VERSION ""

NS_ :

BS_:

BU_: Device Host
VAL_TABLE_ vtBridgeOperation 0 "Freewheeling" 1 "Forward" 2 "Reverse" 3 "Brake" 6 "Error" 7 "Not Available" ;
VAL_TABLE_ vtBridgeStatus 0 "OK" 1 "Shutdown" 2 "Unconfigured" 3 "Not Available" ;
VAL_TABLE_ vtDigitalInput 0 "InputLow" 1 "InputHigh" 2 "Error" 3 "Not Available" ;
VAL_TABLE_ vtOnOff 0 "Off" 1 "On" 2 "Error" 3 "Not Available" ;
VAL_TABLE_ vtPinMode 0 "Disabled" 1 "VREF" 2 "HighSide" 3 "LowSide" 4 "InputOnly" 5 "Bridge" 14 "Error" 15 "Not Available" ;
VAL_TABLE_ vtPinPullMode 0 "None" 1 "PullDown" 2 "PullUp" 3 "Not Available" ;
VAL_TABLE_ vtPwmFreq 0 "1 Hz" 1 "2 Hz" 2 "5 Hz" 3 "10 Hz" 4 "20 Hz" 5 "50 Hz" 6 "100 Hz" 7 "200 Hz" 8 "500 Hz" 9 "1 KHz" 10 "2 KHz" 11 "5 KHz" 14 "Error" 15 "Not Available" ;
VAL_TABLE_ vtQEncoderDirection 0 "Stopped" 1 "Forward" 2 "Reverse" 3 "NotAvailable" ;

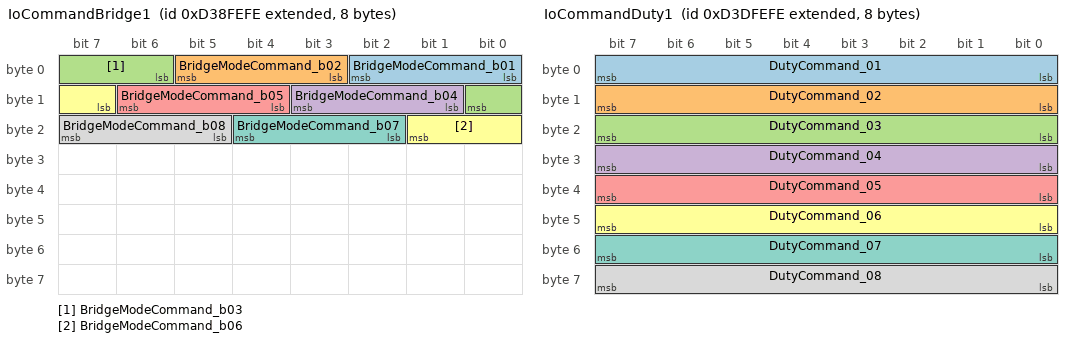
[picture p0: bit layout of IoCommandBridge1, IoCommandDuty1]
BO_ 2369322750 IoCommandBridge1: 8 Host
 SG_ BridgeModeCommand_b01 : 0|3@1+ (1,0) [0|7] ""  Device
 SG_ BridgeModeCommand_b02 : 3|3@1+ (1,0) [0|7] ""  Device
 SG_ BridgeModeCommand_b03 : 6|3@1+ (1,0) [0|7] ""  Device
 SG_ BridgeModeCommand_b04 : 9|3@1+ (1,0) [0|7] ""  Device
 SG_ BridgeModeCommand_b05 : 12|3@1+ (1,0) [0|7] ""  Device
 SG_ BridgeModeCommand_b06 : 15|3@1+ (1,0) [0|7] ""  Device
 SG_ BridgeModeCommand_b07 : 18|3@1+ (1,0) [0|7] ""  Device
 SG_ BridgeModeCommand_b08 : 21|3@1+ (1,0) [0|7] ""  Device

BO_ 2369650430 IoCommandDuty1: 8 Host
 SG_ DutyCommand_01 : 0|8@1+ (0.5,0) [0|100] "%"  Device
 SG_ DutyCommand_02 : 8|8@1+ (0.5,0) [0|100] "%"  Device
 SG_ DutyCommand_03 : 16|8@1+ (0.5,0) [0|100] "%"  Device
 SG_ DutyCommand_04 : 24|8@1+ (0.5,0) [0|100] "%"  Device
 SG_ DutyCommand_05 : 32|8@1+ (0.5,0) [0|100] "%"  Device
 SG_ DutyCommand_06 : 40|8@1+ (0.5,0) [0|100] "%"  Device
 SG_ DutyCommand_07 : 48|8@1+ (0.5,0) [0|100] "%"  Device
 SG_ DutyCommand_08 : 56|8@1+ (0.5,0) [0|100] "%"  Device

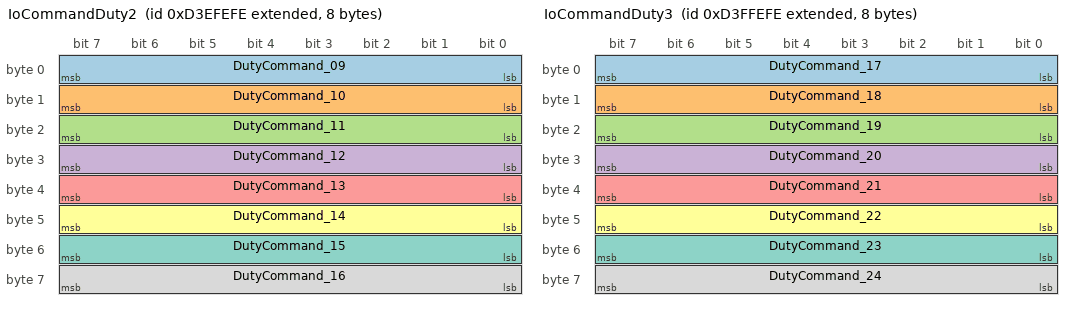
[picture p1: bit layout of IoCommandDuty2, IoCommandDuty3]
BO_ 2369715966 IoCommandDuty2: 8 Host
 SG_ DutyCommand_09 : 0|8@1+ (0.5,0) [0|100] "%"  Device
 SG_ DutyCommand_10 : 8|8@1+ (0.5,0) [0|100] "%"  Device
 SG_ DutyCommand_11 : 16|8@1+ (0.5,0) [0|100] "%"  Device
 SG_ DutyCommand_12 : 24|8@1+ (0.5,0) [0|100] "%"  Device
 SG_ DutyCommand_13 : 32|8@1+ (0.5,0) [0|100] "%"  Device
 SG_ DutyCommand_14 : 40|8@1+ (0.5,0) [0|100] "%"  Device
 SG_ DutyCommand_15 : 48|8@1+ (0.5,0) [0|100] "%"  Device
 SG_ DutyCommand_16 : 56|8@1+ (0.5,0) [0|100] "%"  Device

BO_ 2369781502 IoCommandDuty3: 8 Host
 SG_ DutyCommand_17 : 0|8@1+ (0.5,0) [0|100] "%"  Device
 SG_ DutyCommand_18 : 8|8@1+ (0.5,0) [0|100] "%"  Device
 SG_ DutyCommand_19 : 16|8@1+ (0.5,0) [0|100] "%"  Device
 SG_ DutyCommand_20 : 24|8@1+ (0.5,0) [0|100] "%"  Device
 SG_ DutyCommand_21 : 32|8@1+ (0.5,0) [0|100] "%"  Device
 SG_ DutyCommand_22 : 40|8@1+ (0.5,0) [0|100] "%"  Device
 SG_ DutyCommand_23 : 48|8@1+ (0.5,0) [0|100] "%"  Device
 SG_ DutyCommand_24 : 56|8@1+ (0.5,0) [0|100] "%"  Device

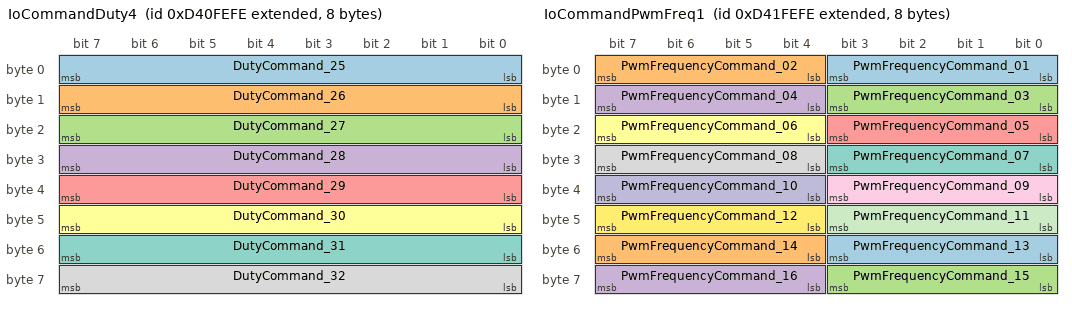
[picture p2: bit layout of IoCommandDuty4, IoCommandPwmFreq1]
BO_ 2369847038 IoCommandDuty4: 8 Host
 SG_ DutyCommand_25 : 0|8@1+ (0.5,0) [0|100] "%"  Device
 SG_ DutyCommand_26 : 8|8@1+ (0.5,0) [0|100] "%"  Device
 SG_ DutyCommand_27 : 16|8@1+ (0.5,0) [0|100] "%"  Device
 SG_ DutyCommand_28 : 24|8@1+ (0.5,0) [0|100] "%"  Device
 SG_ DutyCommand_29 : 32|8@1+ (0.5,0) [0|100] "%"  Device
 SG_ DutyCommand_30 : 40|8@1+ (0.5,0) [0|100] "%"  Device
 SG_ DutyCommand_31 : 48|8@1+ (0.5,0) [0|100] "%"  Device
 SG_ DutyCommand_32 : 56|8@1+ (0.5,0) [0|100] "%"  Device

BO_ 2370043646 IoCommandDutyFD: 32 Host
 SG_ DutyCommand_01 : 0|8@1+ (0.5,0) [0|100] "%"  Device
 SG_ DutyCommand_02 : 8|8@1+ (0.5,0) [0|100] "%"  Device
 SG_ DutyCommand_03 : 16|8@1+ (0.5,0) [0|100] "%"  Device
 SG_ DutyCommand_04 : 24|8@1+ (0.5,0) [0|100] "%"  Device
 SG_ DutyCommand_05 : 32|8@1+ (0.5,0) [0|100] "%"  Device
 SG_ DutyCommand_06 : 40|8@1+ (0.5,0) [0|100] "%"  Device
 SG_ DutyCommand_07 : 48|8@1+ (0.5,0) [0|100] "%"  Device
 SG_ DutyCommand_08 : 56|8@1+ (0.5,0) [0|100] "%"  Device
 SG_ DutyCommand_09 : 64|8@1+ (0.5,0) [0|100] "%"  Device
 SG_ DutyCommand_10 : 72|8@1+ (0.5,0) [0|100] "%"  Device
 SG_ DutyCommand_11 : 80|8@1+ (0.5,0) [0|100] "%"  Device
 SG_ DutyCommand_12 : 88|8@1+ (0.5,0) [0|100] "%"  Device
 SG_ DutyCommand_13 : 96|8@1+ (0.5,0) [0|100] "%"  Device
 SG_ DutyCommand_14 : 104|8@1+ (0.5,0) [0|100] "%"  Device
 SG_ DutyCommand_15 : 112|8@1+ (0.5,0) [0|100] "%"  Device
 SG_ DutyCommand_16 : 120|8@1+ (0.5,0) [0|100] "%"  Device
 SG_ DutyCommand_17 : 128|8@1+ (0.5,0) [0|100] "%"  Device
 SG_ DutyCommand_18 : 136|8@1+ (0.5,0) [0|100] "%"  Device
 SG_ DutyCommand_19 : 144|8@1+ (0.5,0) [0|100] "%"  Device
 SG_ DutyCommand_20 : 152|8@1+ (0.5,0) [0|100] "%"  Device
 SG_ DutyCommand_21 : 160|8@1+ (0.5,0) [0|100] "%"  Device
 SG_ DutyCommand_22 : 168|8@1+ (0.5,0) [0|100] "%"  Device
 SG_ DutyCommand_23 : 176|8@1+ (0.5,0) [0|100] "%"  Device
 SG_ DutyCommand_24 : 184|8@1+ (0.5,0) [0|100] "%"  Device
 SG_ DutyCommand_25 : 192|8@1+ (0.5,0) [0|100] "%"  Device
 SG_ DutyCommand_26 : 200|8@1+ (0.5,0) [0|100] "%"  Device
 SG_ DutyCommand_27 : 208|8@1+ (0.5,0) [0|100] "%"  Device
 SG_ DutyCommand_28 : 216|8@1+ (0.5,0) [0|100] "%"  Device
 SG_ DutyCommand_29 : 224|8@1+ (0.5,0) [0|100] "%"  Device
 SG_ DutyCommand_30 : 232|8@1+ (0.5,0) [0|100] "%"  Device
 SG_ DutyCommand_31 : 240|8@1+ (0.5,0) [0|100] "%"  Device
 SG_ DutyCommand_32 : 248|8@1+ (0.5,0) [0|100] "%"  Device

BO_ 2369388286 IoCommandPinMode1: 8 Host
 SG_ PinModeCommand_01 : 0|4@1+ (1,0) [0|0] ""  Device
 SG_ PinPullModeCommand_01 : 4|2@1+ (1,0) [0|0] ""  Device
 SG_ LoadDetectionCommand_01 : 6|2@1+ (1,0) [0|0] ""  Device
 SG_ PinModeCommand_02 : 8|4@1+ (1,0) [0|0] ""  Device
 SG_ PinPullModeCommand_02 : 12|2@1+ (1,0) [0|0] ""  Device
 SG_ LoadDetectionCommand_02 : 14|2@1+ (1,0) [0|0] ""  Device
 SG_ PinModeCommand_03 : 16|4@1+ (1,0) [0|0] ""  Device
 SG_ PinPullModeCommand_03 : 20|2@1+ (1,0) [0|0] ""  Device
 SG_ LoadDetectionCommand_03 : 22|2@1+ (1,0) [0|0] ""  Device
 SG_ PinModeCommand_04 : 24|4@1+ (1,0) [0|0] ""  Device
 SG_ PinPullModeCommand_04 : 28|2@1+ (1,0) [0|0] ""  Device
 SG_ LoadDetectionCommand_04 : 30|2@1+ (1,0) [0|0] ""  Device
 SG_ PinModeCommand_05 : 32|4@1+ (1,0) [0|0] ""  Device
 SG_ PinPullModeCommand_05 : 36|2@1+ (1,0) [0|0] ""  Device
 SG_ LoadDetectionCommand_05 : 38|2@1+ (1,0) [0|0] ""  Device
 SG_ PinModeCommand_06 : 40|4@1+ (1,0) [0|0] ""  Device
 SG_ PinPullModeCommand_06 : 44|2@1+ (1,0) [0|0] ""  Device
 SG_ LoadDetectionCommand_06 : 46|2@1+ (1,0) [0|0] ""  Device
 SG_ PinModeCommand_07 : 48|4@1+ (1,0) [0|0] ""  Device
 SG_ PinPullModeCommand_07 : 52|2@1+ (1,0) [0|0] ""  Device
 SG_ LoadDetectionCommand_07 : 54|2@1+ (1,0) [0|0] ""  Device
 SG_ PinModeCommand_08 : 56|4@1+ (1,0) [0|0] ""  Device
 SG_ PinPullModeCommand_08 : 60|2@1+ (1,0) [0|0] ""  Device
 SG_ LoadDetectionCommand_08 : 62|2@1+ (1,0) [0|0] ""  Device

BO_ 2369453822 IoCommandPinMode2: 8 Host
 SG_ PinModeCommand_09 : 0|4@1+ (1,0) [0|0] ""  Device
 SG_ PinPullModeCommand_09 : 4|2@1+ (1,0) [0|0] ""  Device
 SG_ LoadDetectionCommand_09 : 6|2@1+ (1,0) [0|0] ""  Device
 SG_ PinModeCommand_10 : 8|4@1+ (1,0) [0|0] ""  Device
 SG_ PinPullModeCommand_10 : 12|2@1+ (1,0) [0|0] ""  Device
 SG_ LoadDetectionCommand_10 : 14|2@1+ (1,0) [0|0] ""  Device
 SG_ PinModeCommand_11 : 16|4@1+ (1,0) [0|0] ""  Device
 SG_ PinPullModeCommand_11 : 20|2@1+ (1,0) [0|0] ""  Device
 SG_ LoadDetectionCommand_11 : 22|2@1+ (1,0) [0|0] ""  Device
 SG_ PinModeCommand_12 : 24|4@1+ (1,0) [0|0] ""  Device
 SG_ PinPullModeCommand_12 : 28|2@1+ (1,0) [0|0] ""  Device
 SG_ LoadDetectionCommand_12 : 30|2@1+ (1,0) [0|0] ""  Device
 SG_ PinModeCommand_13 : 32|4@1+ (1,0) [0|0] ""  Device
 SG_ PinPullModeCommand_13 : 36|2@1+ (1,0) [0|0] ""  Device
 SG_ LoadDetectionCommand_13 : 38|2@1+ (1,0) [0|0] ""  Device
 SG_ PinModeCommand_14 : 40|4@1+ (1,0) [0|0] ""  Device
 SG_ PinPullModeCommand_14 : 44|2@1+ (1,0) [0|0] ""  Device
 SG_ LoadDetectionCommand_14 : 46|2@1+ (1,0) [0|0] ""  Device
 SG_ PinModeCommand_15 : 48|4@1+ (1,0) [0|0] ""  Device
 SG_ PinPullModeCommand_15 : 52|2@1+ (1,0) [0|0] ""  Device
 SG_ LoadDetectionCommand_15 : 54|2@1+ (1,0) [0|0] ""  Device
 SG_ PinModeCommand_16 : 56|4@1+ (1,0) [0|0] ""  Device
 SG_ PinPullModeCommand_16 : 60|2@1+ (1,0) [0|0] ""  Device
 SG_ LoadDetectionCommand_16 : 62|2@1+ (1,0) [0|0] ""  Device

BO_ 2369519358 IoCommandPinMode3: 8 Host
 SG_ PinModeCommand_17 : 0|4@1+ (1,0) [0|0] ""  Device
 SG_ PinPullModeCommand_17 : 4|2@1+ (1,0) [0|0] ""  Device
 SG_ LoadDetectionCommand_17 : 6|2@1+ (1,0) [0|0] ""  Device
 SG_ PinModeCommand_18 : 8|4@1+ (1,0) [0|0] ""  Device
 SG_ PinPullModeCommand_18 : 12|2@1+ (1,0) [0|0] ""  Device
 SG_ LoadDetectionCommand_18 : 14|2@1+ (1,0) [0|0] ""  Device
 SG_ PinModeCommand_19 : 16|4@1+ (1,0) [0|0] ""  Device
 SG_ PinPullModeCommand_19 : 20|2@1+ (1,0) [0|0] ""  Device
 SG_ LoadDetectionCommand_19 : 22|2@1+ (1,0) [0|0] ""  Device
 SG_ PinModeCommand_20 : 24|4@1+ (1,0) [0|0] ""  Device
 SG_ PinPullModeCommand_20 : 28|2@1+ (1,0) [0|0] ""  Device
 SG_ LoadDetectionCommand_20 : 30|2@1+ (1,0) [0|0] ""  Device
 SG_ PinModeCommand_21 : 32|4@1+ (1,0) [0|0] ""  Device
 SG_ PinPullModeCommand_21 : 36|2@1+ (1,0) [0|0] ""  Device
 SG_ LoadDetectionCommand_21 : 38|2@1+ (1,0) [0|0] ""  Device
 SG_ PinModeCommand_22 : 40|4@1+ (1,0) [0|0] ""  Device
 SG_ PinPullModeCommand_22 : 44|2@1+ (1,0) [0|0] ""  Device
 SG_ LoadDetectionCommand_22 : 46|2@1+ (1,0) [0|0] ""  Device
 SG_ PinModeCommand_23 : 48|4@1+ (1,0) [0|0] ""  Device
 SG_ PinPullModeCommand_23 : 52|2@1+ (1,0) [0|0] ""  Device
 SG_ LoadDetectionCommand_23 : 54|2@1+ (1,0) [0|0] ""  Device
 SG_ PinModeCommand_24 : 56|4@1+ (1,0) [0|0] ""  Device
 SG_ PinPullModeCommand_24 : 60|2@1+ (1,0) [0|0] ""  Device
 SG_ LoadDetectionCommand_24 : 62|2@1+ (1,0) [0|0] ""  Device

BO_ 2369584894 IoCommandPinMode4: 8 Host
 SG_ PinModeCommand_25 : 0|4@1+ (1,0) [0|0] ""  Device
 SG_ PinPullModeCommand_25 : 4|2@1+ (1,0) [0|0] ""  Device
 SG_ LoadDetectionCommand_25 : 6|2@1+ (1,0) [0|0] ""  Device
 SG_ PinModeCommand_26 : 8|4@1+ (1,0) [0|0] ""  Device
 SG_ PinPullModeCommand_26 : 12|2@1+ (1,0) [0|0] ""  Device
 SG_ LoadDetectionCommand_26 : 14|2@1+ (1,0) [0|0] ""  Device
 SG_ PinModeCommand_27 : 16|4@1+ (1,0) [0|0] ""  Device
 SG_ PinPullModeCommand_27 : 20|2@1+ (1,0) [0|0] ""  Device
 SG_ LoadDetectionCommand_27 : 22|2@1+ (1,0) [0|0] ""  Device
 SG_ PinModeCommand_28 : 24|4@1+ (1,0) [0|0] ""  Device
 SG_ PinPullModeCommand_28 : 28|2@1+ (1,0) [0|0] ""  Device
 SG_ LoadDetectionCommand_28 : 30|2@1+ (1,0) [0|0] ""  Device
 SG_ PinModeCommand_29 : 32|4@1+ (1,0) [0|0] ""  Device
 SG_ PinPullModeCommand_29 : 36|2@1+ (1,0) [0|0] ""  Device
 SG_ LoadDetectionCommand_29 : 38|2@1+ (1,0) [0|0] ""  Device
 SG_ PinModeCommand_30 : 40|4@1+ (1,0) [0|0] ""  Device
 SG_ PinPullModeCommand_30 : 44|2@1+ (1,0) [0|0] ""  Device
 SG_ LoadDetectionCommand_30 : 46|2@1+ (1,0) [0|0] ""  Device
 SG_ PinModeCommand_31 : 48|4@1+ (1,0) [0|0] ""  Device
 SG_ PinPullModeCommand_31 : 52|2@1+ (1,0) [0|0] ""  Device
 SG_ LoadDetectionCommand_31 : 54|2@1+ (1,0) [0|0] ""  Device
 SG_ PinModeCommand_32 : 56|4@1+ (1,0) [0|0] ""  Device
 SG_ PinPullModeCommand_32 : 60|2@1+ (1,0) [0|0] ""  Device
 SG_ LoadDetectionCommand_32 : 62|2@1+ (1,0) [0|0] ""  Device

BO_ 2369912574 IoCommandPwmFreq1: 8 Host
 SG_ PwmFrequencyCommand_01 : 0|4@1+ (1,0) [0|15] ""  Device
 SG_ PwmFrequencyCommand_02 : 4|4@1+ (1,0) [0|15] ""  Device
 SG_ PwmFrequencyCommand_03 : 8|4@1+ (1,0) [0|15] ""  Device
 SG_ PwmFrequencyCommand_04 : 12|4@1+ (1,0) [0|15] ""  Device
 SG_ PwmFrequencyCommand_05 : 16|4@1+ (1,0) [0|15] ""  Device
 SG_ PwmFrequencyCommand_06 : 20|4@1+ (1,0) [0|15] ""  Device
 SG_ PwmFrequencyCommand_07 : 24|4@1+ (1,0) [0|15] ""  Device
 SG_ PwmFrequencyCommand_08 : 28|4@1+ (1,0) [0|15] ""  Device
 SG_ PwmFrequencyCommand_09 : 32|4@1+ (1,0) [0|15] ""  Device
 SG_ PwmFrequencyCommand_10 : 36|4@1+ (1,0) [0|15] ""  Device
 SG_ PwmFrequencyCommand_11 : 40|4@1+ (1,0) [0|15] ""  Device
 SG_ PwmFrequencyCommand_12 : 44|4@1+ (1,0) [0|15] ""  Device
 SG_ PwmFrequencyCommand_13 : 48|4@1+ (1,0) [0|15] ""  Device
 SG_ PwmFrequencyCommand_14 : 52|4@1+ (1,0) [0|15] ""  Device
 SG_ PwmFrequencyCommand_15 : 56|4@1+ (1,0) [0|15] ""  Device
 SG_ PwmFrequencyCommand_16 : 60|4@1+ (1,0) [0|15] ""  Device

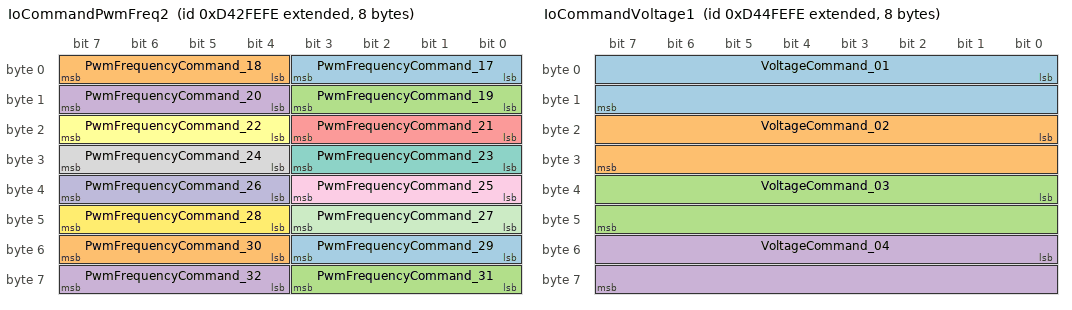
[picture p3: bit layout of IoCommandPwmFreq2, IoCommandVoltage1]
BO_ 2369978110 IoCommandPwmFreq2: 8 Host
 SG_ PwmFrequencyCommand_17 : 0|4@1+ (1,0) [0|15] ""  Device
 SG_ PwmFrequencyCommand_18 : 4|4@1+ (1,0) [0|15] ""  Device
 SG_ PwmFrequencyCommand_19 : 8|4@1+ (1,0) [0|15] ""  Device
 SG_ PwmFrequencyCommand_20 : 12|4@1+ (1,0) [0|15] ""  Device
 SG_ PwmFrequencyCommand_21 : 16|4@1+ (1,0) [0|15] ""  Device
 SG_ PwmFrequencyCommand_22 : 20|4@1+ (1,0) [0|15] ""  Device
 SG_ PwmFrequencyCommand_23 : 24|4@1+ (1,0) [0|15] ""  Device
 SG_ PwmFrequencyCommand_24 : 28|4@1+ (1,0) [0|15] ""  Device
 SG_ PwmFrequencyCommand_25 : 32|4@1+ (1,0) [0|15] ""  Device
 SG_ PwmFrequencyCommand_26 : 36|4@1+ (1,0) [0|15] ""  Device
 SG_ PwmFrequencyCommand_27 : 40|4@1+ (1,0) [0|15] ""  Device
 SG_ PwmFrequencyCommand_28 : 44|4@1+ (1,0) [0|15] ""  Device
 SG_ PwmFrequencyCommand_29 : 48|4@1+ (1,0) [0|15] ""  Device
 SG_ PwmFrequencyCommand_30 : 52|4@1+ (1,0) [0|15] ""  Device
 SG_ PwmFrequencyCommand_31 : 56|4@1+ (1,0) [0|15] ""  Device
 SG_ PwmFrequencyCommand_32 : 60|4@1+ (1,0) [0|15] ""  Device

BO_ 2370109182 IoCommandVoltage1: 8 Host
 SG_ VoltageCommand_01 : 0|16@1+ (0.001,0) [0|64.255] "V"  Device
 SG_ VoltageCommand_02 : 16|16@1+ (0.001,0) [0|64.255] "V"  Device
 SG_ VoltageCommand_03 : 32|16@1+ (0.001,0) [0|64.255] "V"  Device
 SG_ VoltageCommand_04 : 48|16@1+ (0.001,0) [0|64.255] "V"  Device

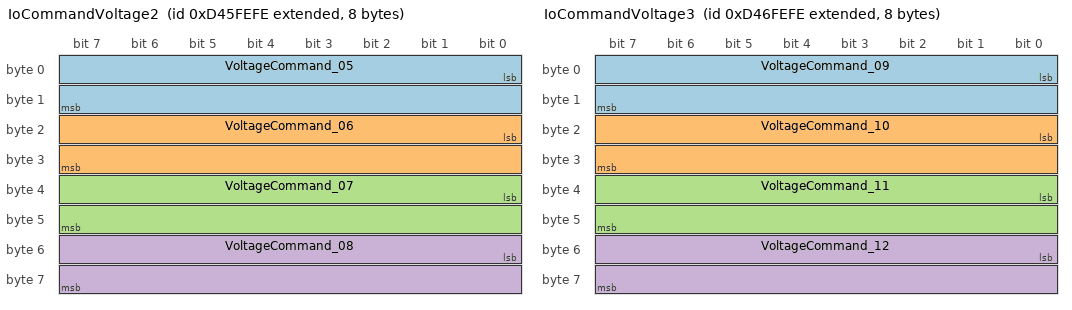
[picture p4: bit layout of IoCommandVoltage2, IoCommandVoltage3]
BO_ 2370174718 IoCommandVoltage2: 8 Host
 SG_ VoltageCommand_05 : 0|16@1+ (0.001,0) [0|64.255] "V"  Device
 SG_ VoltageCommand_06 : 16|16@1+ (0.001,0) [0|64.255] "V"  Device
 SG_ VoltageCommand_07 : 32|16@1+ (0.001,0) [0|64.255] "V"  Device
 SG_ VoltageCommand_08 : 48|16@1+ (0.001,0) [0|64.255] "V"  Device

BO_ 2370240254 IoCommandVoltage3: 8 Host
 SG_ VoltageCommand_09 : 0|16@1+ (0.001,0) [0|64.255] "V"  Device
 SG_ VoltageCommand_10 : 16|16@1+ (0.001,0) [0|64.255] "V"  Device
 SG_ VoltageCommand_11 : 32|16@1+ (0.001,0) [0|64.255] "V"  Device
 SG_ VoltageCommand_12 : 48|16@1+ (0.001,0) [0|64.255] "V"  Device

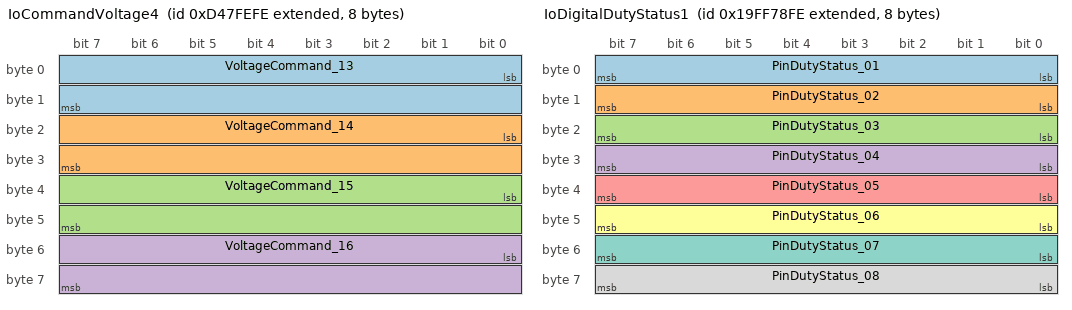
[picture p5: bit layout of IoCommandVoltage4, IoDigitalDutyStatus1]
BO_ 2370305790 IoCommandVoltage4: 8 Host
 SG_ VoltageCommand_13 : 0|16@1+ (0.001,0) [0|64.255] "V"  Device
 SG_ VoltageCommand_14 : 16|16@1+ (0.001,0) [0|64.255] "V"  Device
 SG_ VoltageCommand_15 : 32|16@1+ (0.001,0) [0|64.255] "V"  Device
 SG_ VoltageCommand_16 : 48|16@1+ (0.001,0) [0|64.255] "V"  Device

BO_ 2583656702 IoDigitalDutyStatus1: 8 Device
 SG_ PinDutyStatus_01 : 0|8@1+ (0.5,0) [0|100] "%"  Host
 SG_ PinDutyStatus_02 : 8|8@1+ (0.5,0) [0|100] "%"  Host
 SG_ PinDutyStatus_03 : 16|8@1+ (0.5,0) [0|100] "%"  Host
 SG_ PinDutyStatus_04 : 24|8@1+ (0.5,0) [0|100] "%"  Host
 SG_ PinDutyStatus_05 : 32|8@1+ (0.5,0) [0|100] "%"  Host
 SG_ PinDutyStatus_06 : 40|8@1+ (0.5,0) [0|100] "%"  Host
 SG_ PinDutyStatus_07 : 48|8@1+ (0.5,0) [0|100] "%"  Host
 SG_ PinDutyStatus_08 : 56|8@1+ (0.5,0) [0|100] "%"  Host

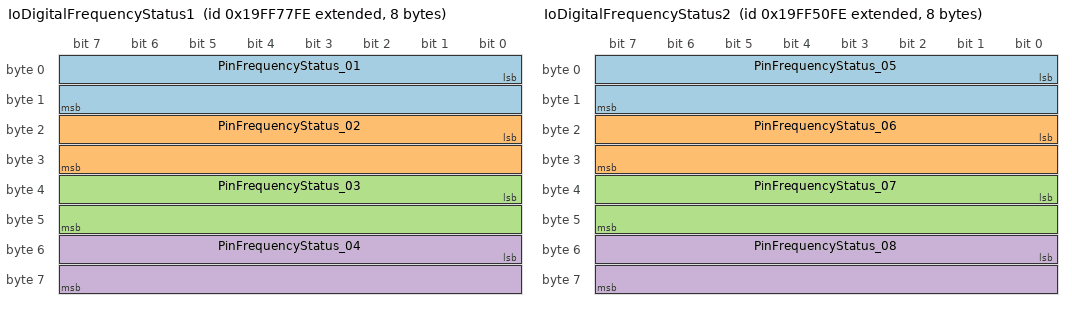
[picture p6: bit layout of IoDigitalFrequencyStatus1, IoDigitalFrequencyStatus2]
BO_ 2583656446 IoDigitalFrequencyStatus1: 8 Device
 SG_ PinFrequencyStatus_01 : 0|16@1+ (0.1,0) [0|6425.5] "Hz"  Host
 SG_ PinFrequencyStatus_02 : 16|16@1+ (0.1,0) [0|6425.5] "Hz"  Host
 SG_ PinFrequencyStatus_03 : 32|16@1+ (0.1,0) [0|6425.5] "Hz"  Host
 SG_ PinFrequencyStatus_04 : 48|16@1+ (0.1,0) [0|6425.5] "Hz"  Host

BO_ 2583646462 IoDigitalFrequencyStatus2: 8 Device
 SG_ PinFrequencyStatus_05 : 0|16@1+ (0.1,0) [0|6425.5] "Hz"  Host
 SG_ PinFrequencyStatus_06 : 16|16@1+ (0.1,0) [0|6425.5] "Hz"  Host
 SG_ PinFrequencyStatus_07 : 32|16@1+ (0.1,0) [0|6425.5] "Hz"  Host
 SG_ PinFrequencyStatus_08 : 48|16@1+ (0.1,0) [0|6425.5] "Hz"  Host

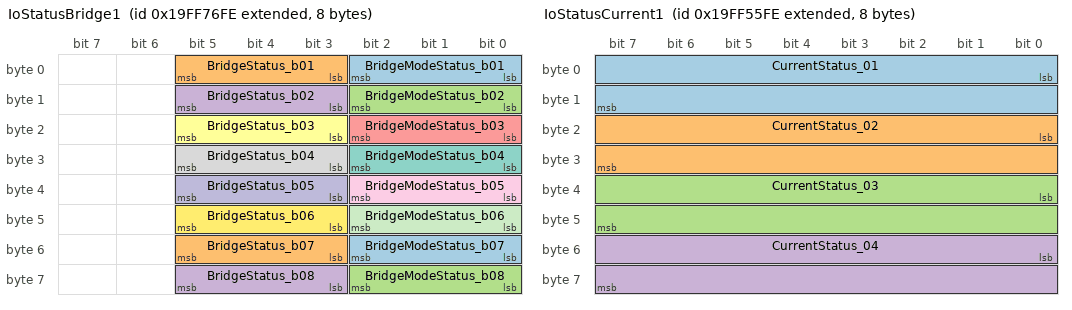
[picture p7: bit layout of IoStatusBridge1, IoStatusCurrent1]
BO_ 2583656190 IoStatusBridge1: 8 Device
 SG_ BridgeModeStatus_b01 : 0|3@1+ (1,0) [0|7] ""  Host
 SG_ BridgeStatus_b01 : 3|3@1+ (1,0) [0|7] ""  Host
 SG_ BridgeModeStatus_b02 : 8|3@1+ (1,0) [0|7] ""  Host
 SG_ BridgeStatus_b02 : 11|3@1+ (1,0) [0|7] ""  Host
 SG_ BridgeModeStatus_b03 : 16|3@1+ (1,0) [0|7] ""  Host
 SG_ BridgeStatus_b03 : 19|3@1+ (1,0) [0|7] ""  Host
 SG_ BridgeModeStatus_b04 : 24|3@1+ (1,0) [0|7] ""  Host
 SG_ BridgeStatus_b04 : 27|3@1+ (1,0) [0|7] ""  Host
 SG_ BridgeModeStatus_b05 : 32|3@1+ (1,0) [0|7] ""  Host
 SG_ BridgeStatus_b05 : 35|3@1+ (1,0) [0|7] ""  Host
 SG_ BridgeModeStatus_b06 : 40|3@1+ (1,0) [0|7] ""  Host
 SG_ BridgeStatus_b06 : 43|3@1+ (1,0) [0|7] ""  Host
 SG_ BridgeModeStatus_b07 : 48|3@1+ (1,0) [0|7] ""  Host
 SG_ BridgeStatus_b07 : 51|3@1+ (1,0) [0|7] ""  Host
 SG_ BridgeModeStatus_b08 : 56|3@1+ (1,0) [0|7] ""  Host
 SG_ BridgeStatus_b08 : 59|3@1+ (1,0) [0|7] ""  Host

BO_ 2583647742 IoStatusCurrent1: 8 Device
 SG_ CurrentStatus_01 : 0|16@1+ (0.01,-320) [-320|320] "A"  Host
 SG_ CurrentStatus_02 : 16|16@1+ (0.01,-320) [-320|320] "A"  Host
 SG_ CurrentStatus_03 : 32|16@1+ (0.01,-320) [-320|320] "A"  Host
 SG_ CurrentStatus_04 : 48|16@1+ (0.01,-320) [-320|320] "A"  Host

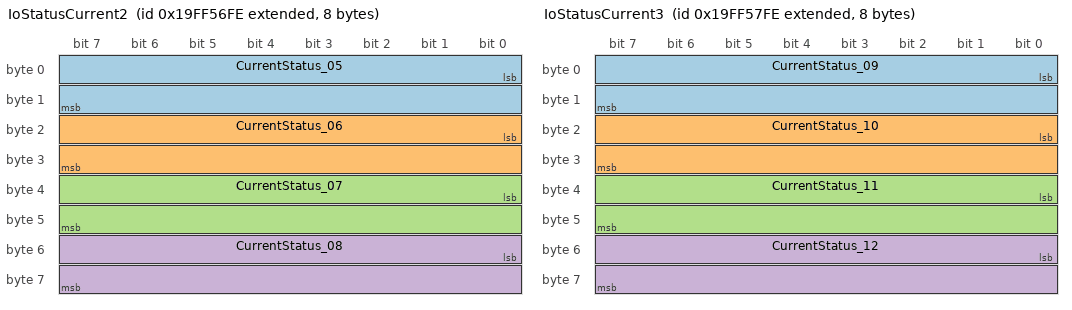
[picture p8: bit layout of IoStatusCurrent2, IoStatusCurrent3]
BO_ 2583647998 IoStatusCurrent2: 8 Device
 SG_ CurrentStatus_05 : 0|16@1+ (0.01,-320) [-320|320] "A"  Host
 SG_ CurrentStatus_06 : 16|16@1+ (0.01,-320) [-320|320] "A"  Host
 SG_ CurrentStatus_07 : 32|16@1+ (0.01,-320) [-320|320] "A"  Host
 SG_ CurrentStatus_08 : 48|16@1+ (0.01,-320) [-320|320] "A"  Host

BO_ 2583648254 IoStatusCurrent3: 8 Device
 SG_ CurrentStatus_09 : 0|16@1+ (0.01,-320) [-320|320] "A"  Host
 SG_ CurrentStatus_10 : 16|16@1+ (0.01,-320) [-320|320] "A"  Host
 SG_ CurrentStatus_11 : 32|16@1+ (0.01,-320) [-320|320] "A"  Host
 SG_ CurrentStatus_12 : 48|16@1+ (0.01,-320) [-320|320] "A"  Host

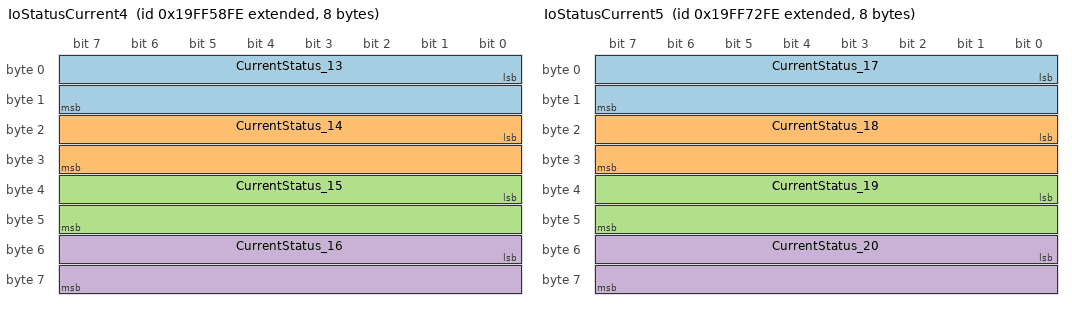
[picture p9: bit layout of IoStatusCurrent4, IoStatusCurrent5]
BO_ 2583648510 IoStatusCurrent4: 8 Device
 SG_ CurrentStatus_13 : 0|16@1+ (0.01,-320) [-320|320] "A"  Host
 SG_ CurrentStatus_14 : 16|16@1+ (0.01,-320) [-320|320] "A"  Host
 SG_ CurrentStatus_15 : 32|16@1+ (0.01,-320) [-320|320] "A"  Host
 SG_ CurrentStatus_16 : 48|16@1+ (0.01,-320) [-320|320] "A"  Host

BO_ 2583655166 IoStatusCurrent5: 8 Device
 SG_ CurrentStatus_17 : 0|16@1+ (0.01,-320) [-320|320] "A"  Host
 SG_ CurrentStatus_18 : 16|16@1+ (0.01,-320) [-320|320] "A"  Host
 SG_ CurrentStatus_19 : 32|16@1+ (0.01,-320) [-320|320] "A"  Host
 SG_ CurrentStatus_20 : 48|16@1+ (0.01,-320) [-320|320] "A"  Host

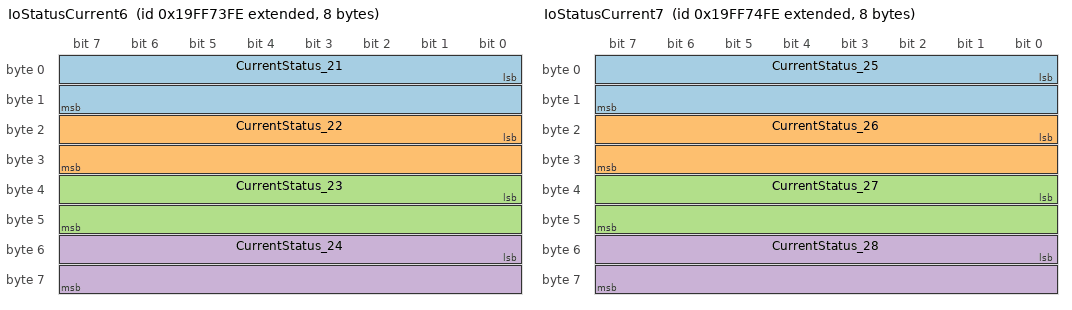
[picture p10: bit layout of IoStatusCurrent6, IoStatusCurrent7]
BO_ 2583655422 IoStatusCurrent6: 8 Device
 SG_ CurrentStatus_21 : 0|16@1+ (0.01,-320) [-320|320] "A"  Host
 SG_ CurrentStatus_22 : 16|16@1+ (0.01,-320) [-320|320] "A"  Host
 SG_ CurrentStatus_23 : 32|16@1+ (0.01,-320) [-320|320] "A"  Host
 SG_ CurrentStatus_24 : 48|16@1+ (0.01,-320) [-320|320] "A"  Host

BO_ 2583655678 IoStatusCurrent7: 8 Device
 SG_ CurrentStatus_25 : 0|16@1+ (0.01,-320) [-320|320] "A"  Host
 SG_ CurrentStatus_26 : 16|16@1+ (0.01,-320) [-320|320] "A"  Host
 SG_ CurrentStatus_27 : 32|16@1+ (0.01,-320) [-320|320] "A"  Host
 SG_ CurrentStatus_28 : 48|16@1+ (0.01,-320) [-320|320] "A"  Host

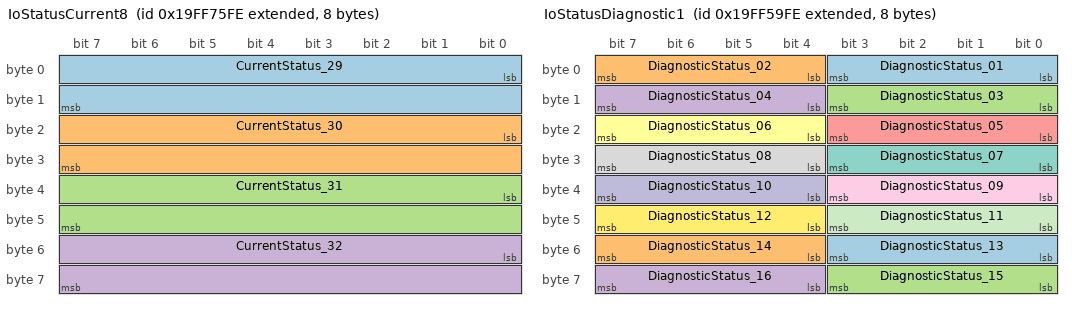
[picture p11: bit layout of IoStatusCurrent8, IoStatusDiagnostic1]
BO_ 2583655934 IoStatusCurrent8: 8 Device
 SG_ CurrentStatus_29 : 0|16@1+ (0.01,-320) [-320|320] "A"  Host
 SG_ CurrentStatus_30 : 16|16@1+ (0.01,-320) [-320|320] "A"  Host
 SG_ CurrentStatus_31 : 32|16@1+ (0.01,-320) [-320|320] "A"  Host
 SG_ CurrentStatus_32 : 48|16@1+ (0.01,-320) [-320|320] "A"  Host

BO_ 2582845950 IoStatusCurrentFD: 64 Device
 SG_ CurrentStatus_01 : 0|16@1+ (0.01,-320) [-320|320] "A"  Host
 SG_ CurrentStatus_02 : 16|16@1+ (0.01,-320) [-320|320] "A"  Host
 SG_ CurrentStatus_03 : 32|16@1+ (0.01,-320) [-320|320] "A"  Host
 SG_ CurrentStatus_04 : 48|16@1+ (0.01,-320) [-320|320] "A"  Host
 SG_ CurrentStatus_05 : 64|16@1+ (0.01,-320) [-320|320] "A"  Host
 SG_ CurrentStatus_06 : 80|16@1+ (0.01,-320) [-320|320] "A"  Host
 SG_ CurrentStatus_07 : 96|16@1+ (0.01,-320) [-320|320] "A"  Host
 SG_ CurrentStatus_08 : 112|16@1+ (0.01,-320) [-320|320] "A"  Host
 SG_ CurrentStatus_09 : 128|16@1+ (0.01,-320) [-320|320] "A"  Host
 SG_ CurrentStatus_10 : 144|16@1+ (0.01,-320) [-320|320] "A"  Host
 SG_ CurrentStatus_11 : 160|16@1+ (0.01,-320) [-320|320] "A"  Host
 SG_ CurrentStatus_12 : 176|16@1+ (0.01,-320) [-320|320] "A"  Host
 SG_ CurrentStatus_13 : 192|16@1+ (0.01,-320) [-320|320] "A"  Host
 SG_ CurrentStatus_14 : 208|16@1+ (0.01,-320) [-320|320] "A"  Host
 SG_ CurrentStatus_15 : 224|16@1+ (0.01,-320) [-320|320] "A"  Host
 SG_ CurrentStatus_16 : 240|16@1+ (0.01,-320) [-320|320] "A"  Host
 SG_ CurrentStatus_17 : 256|16@1+ (0.01,-320) [-320|320] "A"  Host
 SG_ CurrentStatus_18 : 272|16@1+ (0.01,-320) [-320|320] "A"  Host
 SG_ CurrentStatus_19 : 288|16@1+ (0.01,-320) [-320|320] "A"  Host
 SG_ CurrentStatus_20 : 304|16@1+ (0.01,-320) [-320|320] "A"  Host
 SG_ CurrentStatus_21 : 320|16@1+ (0.01,-320) [-320|320] "A"  Host
 SG_ CurrentStatus_22 : 336|16@1+ (0.01,-320) [-320|320] "A"  Host
 SG_ CurrentStatus_23 : 352|16@1+ (0.01,-320) [-320|320] "A"  Host
 SG_ CurrentStatus_24 : 368|16@1+ (0.01,-320) [-320|320] "A"  Host
 SG_ CurrentStatus_25 : 384|16@1+ (0.01,-320) [-320|320] "A"  Host
 SG_ CurrentStatus_26 : 400|16@1+ (0.01,-320) [-320|320] "A"  Host
 SG_ CurrentStatus_27 : 416|16@1+ (0.01,-320) [-320|320] "A"  Host
 SG_ CurrentStatus_28 : 432|16@1+ (0.01,-320) [-320|320] "A"  Host
 SG_ CurrentStatus_29 : 448|16@1+ (0.01,-320) [-320|320] "A"  Host
 SG_ CurrentStatus_30 : 464|16@1+ (0.01,-320) [-320|320] "A"  Host
 SG_ CurrentStatus_31 : 480|16@1+ (0.01,-320) [-320|320] "A"  Host
 SG_ CurrentStatus_32 : 496|16@1+ (0.01,-320) [-320|320] "A"  Host

BO_ 2583648766 IoStatusDiagnostic1: 8 Device
 SG_ DiagnosticStatus_01 : 0|4@1+ (1,0) [0|0] ""  Host
 SG_ DiagnosticStatus_02 : 4|4@1+ (1,0) [0|0] ""  Host
 SG_ DiagnosticStatus_03 : 8|4@1+ (1,0) [0|0] ""  Host
 SG_ DiagnosticStatus_04 : 12|4@1+ (1,0) [0|0] ""  Host
 SG_ DiagnosticStatus_05 : 16|4@1+ (1,0) [0|0] ""  Host
 SG_ DiagnosticStatus_06 : 20|4@1+ (1,0) [0|0] ""  Host
 SG_ DiagnosticStatus_07 : 24|4@1+ (1,0) [0|0] ""  Host
 SG_ DiagnosticStatus_08 : 28|4@1+ (1,0) [0|0] ""  Host
 SG_ DiagnosticStatus_09 : 32|4@1+ (1,0) [0|0] ""  Host
 SG_ DiagnosticStatus_10 : 36|4@1+ (1,0) [0|0] ""  Host
 SG_ DiagnosticStatus_11 : 40|4@1+ (1,0) [0|0] ""  Host
 SG_ DiagnosticStatus_12 : 44|4@1+ (1,0) [0|0] ""  Host
 SG_ DiagnosticStatus_13 : 48|4@1+ (1,0) [0|0] ""  Host
 SG_ DiagnosticStatus_14 : 52|4@1+ (1,0) [0|0] ""  Host
 SG_ DiagnosticStatus_15 : 56|4@1+ (1,0) [0|0] ""  Host
 SG_ DiagnosticStatus_16 : 60|4@1+ (1,0) [0|0] ""  Host

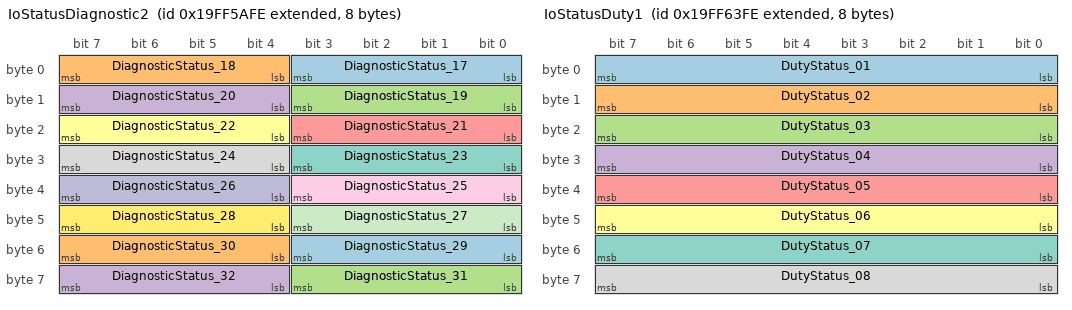
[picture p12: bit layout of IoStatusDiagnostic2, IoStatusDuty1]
BO_ 2583649022 IoStatusDiagnostic2: 8 Device
 SG_ DiagnosticStatus_17 : 0|4@1+ (1,0) [0|0] ""  Host
 SG_ DiagnosticStatus_18 : 4|4@1+ (1,0) [0|0] ""  Host
 SG_ DiagnosticStatus_19 : 8|4@1+ (1,0) [0|0] ""  Host
 SG_ DiagnosticStatus_20 : 12|4@1+ (1,0) [0|0] ""  Host
 SG_ DiagnosticStatus_21 : 16|4@1+ (1,0) [0|0] ""  Host
 SG_ DiagnosticStatus_22 : 20|4@1+ (1,0) [0|0] ""  Host
 SG_ DiagnosticStatus_23 : 24|4@1+ (1,0) [0|0] ""  Host
 SG_ DiagnosticStatus_24 : 28|4@1+ (1,0) [0|0] ""  Host
 SG_ DiagnosticStatus_25 : 32|4@1+ (1,0) [0|0] ""  Host
 SG_ DiagnosticStatus_26 : 36|4@1+ (1,0) [0|0] ""  Host
 SG_ DiagnosticStatus_27 : 40|4@1+ (1,0) [0|0] ""  Host
 SG_ DiagnosticStatus_28 : 44|4@1+ (1,0) [0|0] ""  Host
 SG_ DiagnosticStatus_29 : 48|4@1+ (1,0) [0|0] ""  Host
 SG_ DiagnosticStatus_30 : 52|4@1+ (1,0) [0|0] ""  Host
 SG_ DiagnosticStatus_31 : 56|4@1+ (1,0) [0|0] ""  Host
 SG_ DiagnosticStatus_32 : 60|4@1+ (1,0) [0|0] ""  Host

BO_ 2582847486 IoStatusDiagnosticFD: 16 Device
 SG_ DiagnosticStatus_01 : 0|4@1+ (1,0) [0|0] ""  Host
 SG_ DiagnosticStatus_02 : 4|4@1+ (1,0) [0|0] ""  Host
 SG_ DiagnosticStatus_03 : 8|4@1+ (1,0) [0|0] ""  Host
 SG_ DiagnosticStatus_04 : 12|4@1+ (1,0) [0|0] ""  Host
 SG_ DiagnosticStatus_05 : 16|4@1+ (1,0) [0|0] ""  Host
 SG_ DiagnosticStatus_06 : 20|4@1+ (1,0) [0|0] ""  Host
 SG_ DiagnosticStatus_07 : 24|4@1+ (1,0) [0|0] ""  Host
 SG_ DiagnosticStatus_08 : 28|4@1+ (1,0) [0|0] ""  Host
 SG_ DiagnosticStatus_09 : 32|4@1+ (1,0) [0|0] ""  Host
 SG_ DiagnosticStatus_10 : 36|4@1+ (1,0) [0|0] ""  Host
 SG_ DiagnosticStatus_11 : 40|4@1+ (1,0) [0|0] ""  Host
 SG_ DiagnosticStatus_12 : 44|4@1+ (1,0) [0|0] ""  Host
 SG_ DiagnosticStatus_13 : 48|4@1+ (1,0) [0|0] ""  Host
 SG_ DiagnosticStatus_14 : 52|4@1+ (1,0) [0|0] ""  Host
 SG_ DiagnosticStatus_15 : 56|4@1+ (1,0) [0|0] ""  Host
 SG_ DiagnosticStatus_16 : 60|4@1+ (1,0) [0|0] ""  Host
 SG_ DiagnosticStatus_17 : 64|4@1+ (1,0) [0|0] ""  Host
 SG_ DiagnosticStatus_18 : 68|4@1+ (1,0) [0|0] ""  Host
 SG_ DiagnosticStatus_19 : 72|4@1+ (1,0) [0|0] ""  Host
 SG_ DiagnosticStatus_20 : 76|4@1+ (1,0) [0|0] ""  Host
 SG_ DiagnosticStatus_21 : 80|4@1+ (1,0) [0|0] ""  Host
 SG_ DiagnosticStatus_22 : 84|4@1+ (1,0) [0|0] ""  Host
 SG_ DiagnosticStatus_23 : 88|4@1+ (1,0) [0|0] ""  Host
 SG_ DiagnosticStatus_24 : 92|4@1+ (1,0) [0|0] ""  Host
 SG_ DiagnosticStatus_25 : 96|4@1+ (1,0) [0|0] ""  Host
 SG_ DiagnosticStatus_26 : 100|4@1+ (1,0) [0|0] ""  Host
 SG_ DiagnosticStatus_27 : 104|4@1+ (1,0) [0|0] ""  Host
 SG_ DiagnosticStatus_28 : 108|4@1+ (1,0) [0|0] ""  Host
 SG_ DiagnosticStatus_29 : 112|4@1+ (1,0) [0|0] ""  Host
 SG_ DiagnosticStatus_30 : 116|4@1+ (1,0) [0|0] ""  Host
 SG_ DiagnosticStatus_31 : 120|4@1+ (1,0) [0|0] ""  Host
 SG_ DiagnosticStatus_32 : 124|4@1+ (1,0) [0|0] ""  Host

BO_ 2583651326 IoStatusDuty1: 8 Device
 SG_ DutyStatus_01 : 0|8@1+ (0.5,0) [0|100] "%"  Host
 SG_ DutyStatus_02 : 8|8@1+ (0.5,0) [0|100] "%"  Host
 SG_ DutyStatus_03 : 16|8@1+ (0.5,0) [0|100] "%"  Host
 SG_ DutyStatus_04 : 24|8@1+ (0.5,0) [0|100] "%"  Host
 SG_ DutyStatus_05 : 32|8@1+ (0.5,0) [0|100] "%"  Host
 SG_ DutyStatus_06 : 40|8@1+ (0.5,0) [0|100] "%"  Host
 SG_ DutyStatus_07 : 48|8@1+ (0.5,0) [0|100] "%"  Host
 SG_ DutyStatus_08 : 56|8@1+ (0.5,0) [0|100] "%"  Host

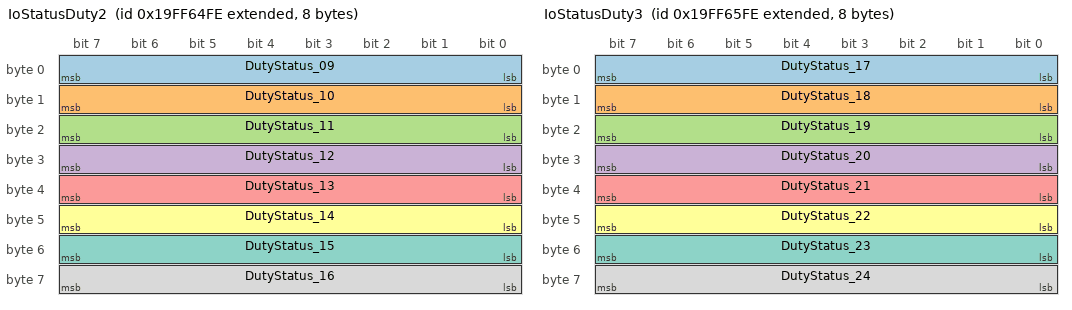
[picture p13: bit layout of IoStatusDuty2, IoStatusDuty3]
BO_ 2583651582 IoStatusDuty2: 8 Device
 SG_ DutyStatus_09 : 0|8@1+ (0.5,0) [0|100] "%"  Host
 SG_ DutyStatus_10 : 8|8@1+ (0.5,0) [0|100] "%"  Host
 SG_ DutyStatus_11 : 16|8@1+ (0.5,0) [0|100] "%"  Host
 SG_ DutyStatus_12 : 24|8@1+ (0.5,0) [0|100] "%"  Host
 SG_ DutyStatus_13 : 32|8@1+ (0.5,0) [0|100] "%"  Host
 SG_ DutyStatus_14 : 40|8@1+ (0.5,0) [0|100] "%"  Host
 SG_ DutyStatus_15 : 48|8@1+ (0.5,0) [0|100] "%"  Host
 SG_ DutyStatus_16 : 56|8@1+ (0.5,0) [0|100] "%"  Host

BO_ 2583651838 IoStatusDuty3: 8 Device
 SG_ DutyStatus_17 : 0|8@1+ (0.5,0) [0|100] "%"  Host
 SG_ DutyStatus_18 : 8|8@1+ (0.5,0) [0|100] "%"  Host
 SG_ DutyStatus_19 : 16|8@1+ (0.5,0) [0|100] "%"  Host
 SG_ DutyStatus_20 : 24|8@1+ (0.5,0) [0|100] "%"  Host
 SG_ DutyStatus_21 : 32|8@1+ (0.5,0) [0|100] "%"  Host
 SG_ DutyStatus_22 : 40|8@1+ (0.5,0) [0|100] "%"  Host
 SG_ DutyStatus_23 : 48|8@1+ (0.5,0) [0|100] "%"  Host
 SG_ DutyStatus_24 : 56|8@1+ (0.5,0) [0|100] "%"  Host

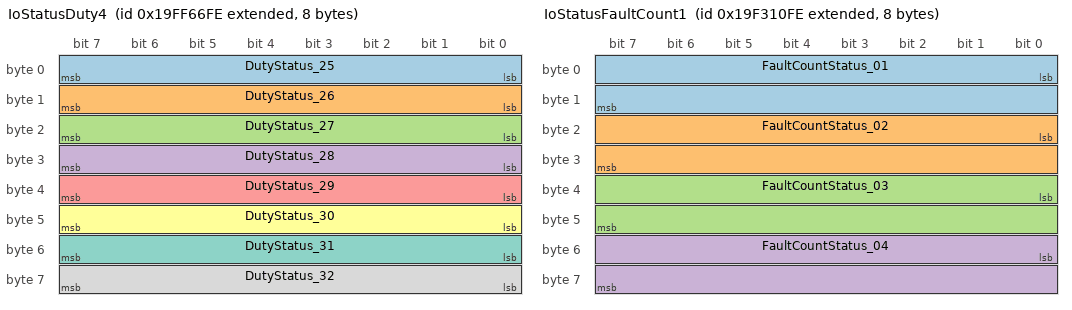
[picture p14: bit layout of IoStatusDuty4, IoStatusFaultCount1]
BO_ 2583652094 IoStatusDuty4: 8 Device
 SG_ DutyStatus_25 : 0|8@1+ (0.5,0) [0|100] "%"  Host
 SG_ DutyStatus_26 : 8|8@1+ (0.5,0) [0|100] "%"  Host
 SG_ DutyStatus_27 : 16|8@1+ (0.5,0) [0|100] "%"  Host
 SG_ DutyStatus_28 : 24|8@1+ (0.5,0) [0|100] "%"  Host
 SG_ DutyStatus_29 : 32|8@1+ (0.5,0) [0|100] "%"  Host
 SG_ DutyStatus_30 : 40|8@1+ (0.5,0) [0|100] "%"  Host
 SG_ DutyStatus_31 : 48|8@1+ (0.5,0) [0|100] "%"  Host
 SG_ DutyStatus_32 : 56|8@1+ (0.5,0) [0|100] "%"  Host

BO_ 2582847742 IoStatusDutyFD: 32 Device
 SG_ DutyStatus_01 : 0|8@1+ (0.5,0) [0|100] "%"  Host
 SG_ DutyStatus_02 : 8|8@1+ (0.5,0) [0|100] "%"  Host
 SG_ DutyStatus_03 : 16|8@1+ (0.5,0) [0|100] "%"  Host
 SG_ DutyStatus_04 : 24|8@1+ (0.5,0) [0|100] "%"  Host
 SG_ DutyStatus_05 : 32|8@1+ (0.5,0) [0|100] "%"  Host
 SG_ DutyStatus_06 : 40|8@1+ (0.5,0) [0|100] "%"  Host
 SG_ DutyStatus_07 : 48|8@1+ (0.5,0) [0|100] "%"  Host
 SG_ DutyStatus_08 : 56|8@1+ (0.5,0) [0|100] "%"  Host
 SG_ DutyStatus_09 : 64|8@1+ (0.5,0) [0|100] "%"  Host
 SG_ DutyStatus_10 : 72|8@1+ (0.5,0) [0|100] "%"  Host
 SG_ DutyStatus_11 : 80|8@1+ (0.5,0) [0|100] "%"  Host
 SG_ DutyStatus_12 : 88|8@1+ (0.5,0) [0|100] "%"  Host
 SG_ DutyStatus_13 : 96|8@1+ (0.5,0) [0|100] "%"  Host
 SG_ DutyStatus_14 : 104|8@1+ (0.5,0) [0|100] "%"  Host
 SG_ DutyStatus_15 : 112|8@1+ (0.5,0) [0|100] "%"  Host
 SG_ DutyStatus_16 : 120|8@1+ (0.5,0) [0|100] "%"  Host
 SG_ DutyStatus_17 : 128|8@1+ (0.5,0) [0|100] "%"  Host
 SG_ DutyStatus_18 : 136|8@1+ (0.5,0) [0|100] "%"  Host
 SG_ DutyStatus_19 : 144|8@1+ (0.5,0) [0|100] "%"  Host
 SG_ DutyStatus_20 : 152|8@1+ (0.5,0) [0|100] "%"  Host
 SG_ DutyStatus_21 : 160|8@1+ (0.5,0) [0|100] "%"  Host
 SG_ DutyStatus_22 : 168|8@1+ (0.5,0) [0|100] "%"  Host
 SG_ DutyStatus_23 : 176|8@1+ (0.5,0) [0|100] "%"  Host
 SG_ DutyStatus_24 : 184|8@1+ (0.5,0) [0|100] "%"  Host
 SG_ DutyStatus_25 : 192|8@1+ (0.5,0) [0|100] "%"  Host
 SG_ DutyStatus_26 : 200|8@1+ (0.5,0) [0|100] "%"  Host
 SG_ DutyStatus_27 : 208|8@1+ (0.5,0) [0|100] "%"  Host
 SG_ DutyStatus_28 : 216|8@1+ (0.5,0) [0|100] "%"  Host
 SG_ DutyStatus_29 : 224|8@1+ (0.5,0) [0|100] "%"  Host
 SG_ DutyStatus_30 : 232|8@1+ (0.5,0) [0|100] "%"  Host
 SG_ DutyStatus_31 : 240|8@1+ (0.5,0) [0|100] "%"  Host
 SG_ DutyStatus_32 : 248|8@1+ (0.5,0) [0|100] "%"  Host

BO_ 2582843646 IoStatusFaultCount1: 8 Device
 SG_ FaultCountStatus_01 : 0|16@1+ (1,0) [0|64255] ""  Host
 SG_ FaultCountStatus_02 : 16|16@1+ (1,0) [0|64255] ""  Host
 SG_ FaultCountStatus_03 : 32|16@1+ (1,0) [0|64255] ""  Host
 SG_ FaultCountStatus_04 : 48|16@1+ (1,0) [0|64255] ""  Host

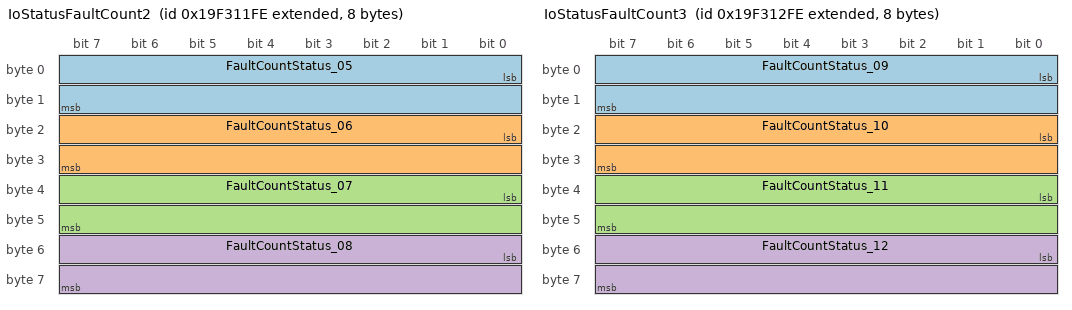
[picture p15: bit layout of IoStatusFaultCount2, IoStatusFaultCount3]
BO_ 2582843902 IoStatusFaultCount2: 8 Device
 SG_ FaultCountStatus_05 : 0|16@1+ (1,0) [0|64255] ""  Host
 SG_ FaultCountStatus_06 : 16|16@1+ (1,0) [0|64255] ""  Host
 SG_ FaultCountStatus_07 : 32|16@1+ (1,0) [0|64255] ""  Host
 SG_ FaultCountStatus_08 : 48|16@1+ (1,0) [0|64255] ""  Host

BO_ 2582844158 IoStatusFaultCount3: 8 Device
 SG_ FaultCountStatus_09 : 0|16@1+ (1,0) [0|64255] ""  Host
 SG_ FaultCountStatus_10 : 16|16@1+ (1,0) [0|64255] ""  Host
 SG_ FaultCountStatus_11 : 32|16@1+ (1,0) [0|64255] ""  Host
 SG_ FaultCountStatus_12 : 48|16@1+ (1,0) [0|64255] ""  Host

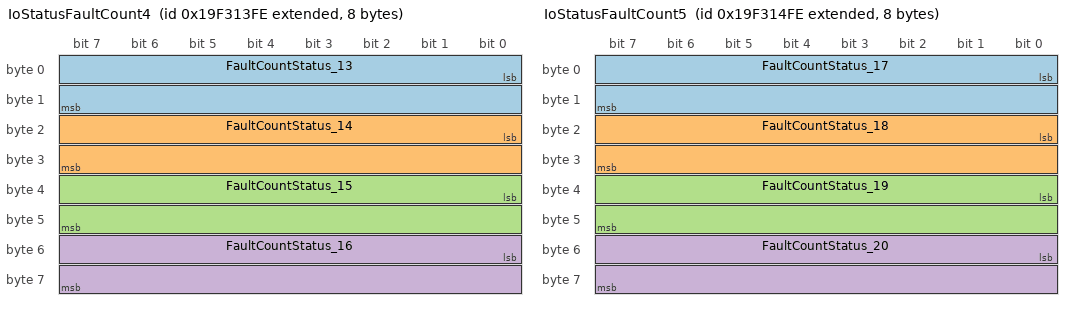
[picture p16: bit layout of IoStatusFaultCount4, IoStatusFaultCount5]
BO_ 2582844414 IoStatusFaultCount4: 8 Device
 SG_ FaultCountStatus_13 : 0|16@1+ (1,0) [0|64255] ""  Host
 SG_ FaultCountStatus_14 : 16|16@1+ (1,0) [0|64255] ""  Host
 SG_ FaultCountStatus_15 : 32|16@1+ (1,0) [0|64255] ""  Host
 SG_ FaultCountStatus_16 : 48|16@1+ (1,0) [0|64255] ""  Host

BO_ 2582844670 IoStatusFaultCount5: 8 Device
 SG_ FaultCountStatus_17 : 0|16@1+ (1,0) [0|64255] ""  Host
 SG_ FaultCountStatus_18 : 16|16@1+ (1,0) [0|64255] ""  Host
 SG_ FaultCountStatus_19 : 32|16@1+ (1,0) [0|64255] ""  Host
 SG_ FaultCountStatus_20 : 48|16@1+ (1,0) [0|64255] ""  Host

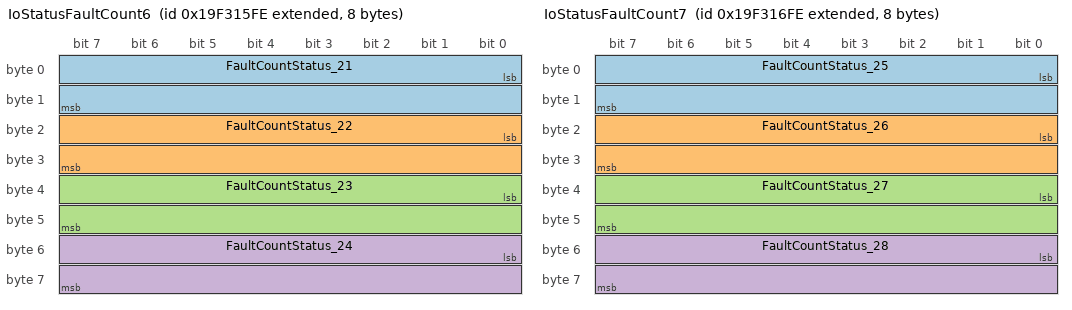
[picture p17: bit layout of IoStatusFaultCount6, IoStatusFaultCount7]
BO_ 2582844926 IoStatusFaultCount6: 8 Device
 SG_ FaultCountStatus_21 : 0|16@1+ (1,0) [0|64255] ""  Host
 SG_ FaultCountStatus_22 : 16|16@1+ (1,0) [0|64255] ""  Host
 SG_ FaultCountStatus_23 : 32|16@1+ (1,0) [0|64255] ""  Host
 SG_ FaultCountStatus_24 : 48|16@1+ (1,0) [0|64255] ""  Host

BO_ 2582845182 IoStatusFaultCount7: 8 Device
 SG_ FaultCountStatus_25 : 0|16@1+ (1,0) [0|64255] ""  Host
 SG_ FaultCountStatus_26 : 16|16@1+ (1,0) [0|64255] ""  Host
 SG_ FaultCountStatus_27 : 32|16@1+ (1,0) [0|64255] ""  Host
 SG_ FaultCountStatus_28 : 48|16@1+ (1,0) [0|64255] ""  Host

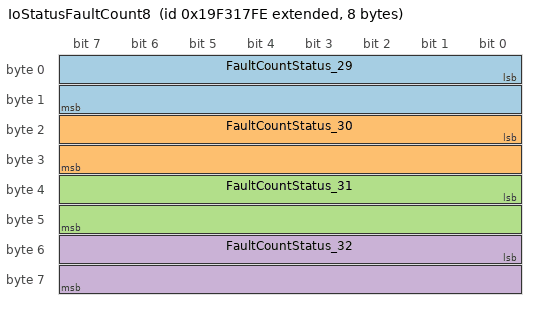
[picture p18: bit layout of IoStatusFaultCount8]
BO_ 2582845438 IoStatusFaultCount8: 8 Device
 SG_ FaultCountStatus_29 : 0|16@1+ (1,0) [0|64255] ""  Host
 SG_ FaultCountStatus_30 : 16|16@1+ (1,0) [0|64255] ""  Host
 SG_ FaultCountStatus_31 : 32|16@1+ (1,0) [0|64255] ""  Host
 SG_ FaultCountStatus_32 : 48|16@1+ (1,0) [0|64255] ""  Host

CM_ "Universal IO (UIO) messages
$File: //system_software/dbc/UIO/0.36.0.0/Arrival_uio.dbc $
$Change: 208863 $
$DateTime: 2023/11/10 13:11:00 $
$Revision: #1 $";
CM_ BO_ 2369322750 "Bridge management command";
CM_ BO_ 2369650430 "Comand to change pin duty value. This value will be used if pin on HighSide, LowSide or Bridge mode.";
CM_ BO_ 2369715966 "Comand to change pin duty value. This value will be used if pin on HighSide, LowSide or Bridge mode.";
CM_ BO_ 2369781502 "Comand to change pin duty value. This value will be used if pin on HighSide, LowSide or Bridge mode.";
CM_ BO_ 2369847038 "Comand to change pin duty value. This value will be used if pin on HighSide, LowSide or Bridge mode.";
CM_ BO_ 2370043646 "Comand to change pin duty value. This value will be used if pin on HighSide, LowSide or Bridge mode.";
CM_ BO_ 2369388286 "Command to change pin mode on fly";
CM_ SG_ 2369388286 PinModeCommand_01 "Pin mode Command";
CM_ SG_ 2369388286 PinPullModeCommand_01 "Pin pullup/pulldown mode Command";
CM_ SG_ 2369388286 LoadDetectionCommand_01 "Enable/disable load detection diagnostic";
CM_ SG_ 2369388286 PinModeCommand_02 "Pin mode Command";
CM_ SG_ 2369388286 PinPullModeCommand_02 "Pin pullup/pulldown mode Command";
CM_ SG_ 2369388286 LoadDetectionCommand_02 "Enable/disable load detection diagnostic";
CM_ SG_ 2369388286 PinModeCommand_03 "Pin mode Command";
CM_ SG_ 2369388286 PinPullModeCommand_03 "Pin pullup/pulldown mode Command";
CM_ SG_ 2369388286 LoadDetectionCommand_03 "Enable/disable load detection diagnostic";
CM_ SG_ 2369388286 PinModeCommand_04 "Pin mode Command";
CM_ SG_ 2369388286 PinPullModeCommand_04 "Pin pullup/pulldown mode Command";
CM_ SG_ 2369388286 LoadDetectionCommand_04 "Enable/disable load detection diagnostic";
CM_ SG_ 2369388286 PinModeCommand_05 "Pin mode Command";
CM_ SG_ 2369388286 PinPullModeCommand_05 "Pin pullup/pulldown mode Command";
CM_ SG_ 2369388286 LoadDetectionCommand_05 "Enable/disable load detection diagnostic";
CM_ SG_ 2369388286 PinModeCommand_06 "Pin mode Command";
CM_ SG_ 2369388286 PinPullModeCommand_06 "Pin pullup/pulldown mode Command";
CM_ SG_ 2369388286 LoadDetectionCommand_06 "Enable/disable load detection diagnostic";
CM_ SG_ 2369388286 PinModeCommand_07 "Pin mode Command";
CM_ SG_ 2369388286 PinPullModeCommand_07 "Pin pullup/pulldown mode Command";
CM_ SG_ 2369388286 LoadDetectionCommand_07 "Enable/disable load detection diagnostic";
CM_ SG_ 2369388286 PinModeCommand_08 "Pin mode Command";
CM_ SG_ 2369388286 PinPullModeCommand_08 "Pin pullup/pulldown mode Command";
CM_ SG_ 2369388286 LoadDetectionCommand_08 "Enable/disable load detection diagnostic";
CM_ BO_ 2369453822 "Command to change pin mode on fly";
CM_ SG_ 2369453822 PinModeCommand_09 "Pin mode Command";
CM_ SG_ 2369453822 PinPullModeCommand_09 "Pin pullup/pulldown mode Command";
CM_ SG_ 2369453822 LoadDetectionCommand_09 "Enable/disable load detection diagnostic";
CM_ SG_ 2369453822 PinModeCommand_10 "Pin mode Command";
CM_ SG_ 2369453822 PinPullModeCommand_10 "Pin pullup/pulldown mode Command";
CM_ SG_ 2369453822 LoadDetectionCommand_10 "Enable/disable load detection diagnostic";
CM_ SG_ 2369453822 PinModeCommand_11 "Pin mode Command";
CM_ SG_ 2369453822 PinPullModeCommand_11 "Pin pullup/pulldown mode Command";
CM_ SG_ 2369453822 LoadDetectionCommand_11 "Enable/disable load detection diagnostic";
CM_ SG_ 2369453822 PinModeCommand_12 "Pin mode Command";
CM_ SG_ 2369453822 PinPullModeCommand_12 "Pin pullup/pulldown mode Command";
CM_ SG_ 2369453822 LoadDetectionCommand_12 "Enable/disable load detection diagnostic";
CM_ SG_ 2369453822 PinModeCommand_13 "Pin mode Command";
CM_ SG_ 2369453822 PinPullModeCommand_13 "Pin pullup/pulldown mode Command";
CM_ SG_ 2369453822 LoadDetectionCommand_13 "Enable/disable load detection diagnostic";
CM_ SG_ 2369453822 PinModeCommand_14 "Pin mode Command";
CM_ SG_ 2369453822 PinPullModeCommand_14 "Pin pullup/pulldown mode Command";
CM_ SG_ 2369453822 LoadDetectionCommand_14 "Enable/disable load detection diagnostic";
CM_ SG_ 2369453822 PinModeCommand_15 "Pin mode Command";
CM_ SG_ 2369453822 PinPullModeCommand_15 "Pin pullup/pulldown mode Command";
CM_ SG_ 2369453822 LoadDetectionCommand_15 "Enable/disable load detection diagnostic";
CM_ SG_ 2369453822 PinModeCommand_16 "Pin mode Command";
CM_ SG_ 2369453822 PinPullModeCommand_16 "Pin pullup/pulldown mode Command";
CM_ SG_ 2369453822 LoadDetectionCommand_16 "Enable/disable load detection diagnostic";
CM_ BO_ 2369519358 "Command to change pin mode on fly";
CM_ SG_ 2369519358 PinModeCommand_17 "Pin mode Command";
CM_ SG_ 2369519358 PinPullModeCommand_17 "Pin pullup/pulldown mode Command";
CM_ SG_ 2369519358 LoadDetectionCommand_17 "Enable/disable load detection diagnostic";
CM_ SG_ 2369519358 PinModeCommand_18 "Pin mode Command";
CM_ SG_ 2369519358 PinPullModeCommand_18 "Pin pullup/pulldown mode Command";
CM_ SG_ 2369519358 LoadDetectionCommand_18 "Enable/disable load detection diagnostic";
CM_ SG_ 2369519358 PinModeCommand_19 "Pin mode Command";
CM_ SG_ 2369519358 PinPullModeCommand_19 "Pin pullup/pulldown mode Command";
CM_ SG_ 2369519358 LoadDetectionCommand_19 "Enable/disable load detection diagnostic";
CM_ SG_ 2369519358 PinModeCommand_20 "Pin mode Command";
CM_ SG_ 2369519358 PinPullModeCommand_20 "Pin pullup/pulldown mode Command";
CM_ SG_ 2369519358 LoadDetectionCommand_20 "Enable/disable load detection diagnostic";
CM_ SG_ 2369519358 PinModeCommand_21 "Pin mode Command";
CM_ SG_ 2369519358 PinPullModeCommand_21 "Pin pullup/pulldown mode Command";
CM_ SG_ 2369519358 LoadDetectionCommand_21 "Enable/disable load detection diagnostic";
CM_ SG_ 2369519358 PinModeCommand_22 "Pin mode Command";
CM_ SG_ 2369519358 PinPullModeCommand_22 "Pin pullup/pulldown mode Command";
CM_ SG_ 2369519358 LoadDetectionCommand_22 "Enable/disable load detection diagnostic";
CM_ SG_ 2369519358 PinModeCommand_23 "Pin mode Command";
CM_ SG_ 2369519358 PinPullModeCommand_23 "Pin pullup/pulldown mode Command";
CM_ SG_ 2369519358 LoadDetectionCommand_23 "Enable/disable load detection diagnostic";
CM_ SG_ 2369519358 PinModeCommand_24 "Pin mode Command";
CM_ SG_ 2369519358 PinPullModeCommand_24 "Pin pullup/pulldown mode Command";
CM_ SG_ 2369519358 LoadDetectionCommand_24 "Enable/disable load detection diagnostic";
CM_ BO_ 2369584894 "Command to change pin mode on fly";
CM_ SG_ 2369584894 PinModeCommand_25 "Pin mode Command";
CM_ SG_ 2369584894 PinPullModeCommand_25 "Pin pullup/pulldown mode Command";
CM_ SG_ 2369584894 LoadDetectionCommand_25 "Enable/disable load detection diagnostic";
CM_ SG_ 2369584894 PinModeCommand_26 "Pin mode Command";
CM_ SG_ 2369584894 PinPullModeCommand_26 "Pin pullup/pulldown mode Command";
CM_ SG_ 2369584894 LoadDetectionCommand_26 "Enable/disable load detection diagnostic";
CM_ SG_ 2369584894 PinModeCommand_27 "Pin mode Command";
CM_ SG_ 2369584894 PinPullModeCommand_27 "Pin pullup/pulldown mode Command";
CM_ SG_ 2369584894 LoadDetectionCommand_27 "Enable/disable load detection diagnostic";
CM_ SG_ 2369584894 PinModeCommand_28 "Pin mode Command";
CM_ SG_ 2369584894 PinPullModeCommand_28 "Pin pullup/pulldown mode Command";
CM_ SG_ 2369584894 LoadDetectionCommand_28 "Enable/disable load detection diagnostic";
CM_ SG_ 2369584894 PinModeCommand_29 "Pin mode Command";
CM_ SG_ 2369584894 PinPullModeCommand_29 "Pin pullup/pulldown mode Command";
CM_ SG_ 2369584894 LoadDetectionCommand_29 "Enable/disable load detection diagnostic";
CM_ SG_ 2369584894 PinModeCommand_30 "Pin mode Command";
CM_ SG_ 2369584894 PinPullModeCommand_30 "Pin pullup/pulldown mode Command";
CM_ SG_ 2369584894 LoadDetectionCommand_30 "Enable/disable load detection diagnostic";
CM_ SG_ 2369584894 PinModeCommand_31 "Pin mode Command";
CM_ SG_ 2369584894 PinPullModeCommand_31 "Pin pullup/pulldown mode Command";
CM_ SG_ 2369584894 LoadDetectionCommand_31 "Enable/disable load detection diagnostic";
CM_ SG_ 2369584894 PinModeCommand_32 "Pin mode Command";
CM_ SG_ 2369584894 PinPullModeCommand_32 "Pin pullup/pulldown mode Command";
CM_ SG_ 2369584894 LoadDetectionCommand_32 "Enable/disable load detection diagnostic";
CM_ BO_ 2369912574 "Comand to change pin PWM frequency value. This value will be used if pin on HighSide, LowSide or Bridge mode.";
CM_ BO_ 2369978110 "Comand to change pin PWM frequency value. This value will be used if pin on HighSide, LowSide or Bridge mode.";
CM_ BO_ 2370109182 "Comand to change pin voltage value";
CM_ SG_ 2370109182 VoltageCommand_01 "Set output voltage";
CM_ SG_ 2370109182 VoltageCommand_02 "Set output voltage";
CM_ SG_ 2370109182 VoltageCommand_03 "Set output voltage";
CM_ SG_ 2370109182 VoltageCommand_04 "Set output voltage";
CM_ BO_ 2370174718 "Comand to change pin voltage value";
CM_ SG_ 2370174718 VoltageCommand_05 "Set output voltage";
CM_ SG_ 2370174718 VoltageCommand_06 "Set output voltage";
CM_ SG_ 2370174718 VoltageCommand_07 "Set output voltage";
CM_ SG_ 2370174718 VoltageCommand_08 "Set output voltage";
CM_ BO_ 2370240254 "Comand to change pin voltage value";
CM_ SG_ 2370240254 VoltageCommand_09 "Set output voltage";
CM_ SG_ 2370240254 VoltageCommand_10 "Set output voltage";
CM_ SG_ 2370240254 VoltageCommand_11 "Set output voltage";
CM_ SG_ 2370240254 VoltageCommand_12 "Set output voltage";
CM_ BO_ 2370305790 "Comand to change pin voltage value";
CM_ SG_ 2370305790 VoltageCommand_13 "Set output voltage";
CM_ SG_ 2370305790 VoltageCommand_14 "Set output voltage";
CM_ SG_ 2370305790 VoltageCommand_15 "Set output voltage";
CM_ SG_ 2370305790 VoltageCommand_16 "Set output voltage";
CM_ BO_ 2583656702 "Measured frequency on inputs 1";
CM_ SG_ 2583656702 PinDutyStatus_01 "Measured PWM duty in input";
CM_ SG_ 2583656702 PinDutyStatus_02 "Measured PWM duty in input";
CM_ SG_ 2583656702 PinDutyStatus_03 "Measured PWM duty in input";
CM_ SG_ 2583656702 PinDutyStatus_04 "Measured PWM duty in input";
CM_ SG_ 2583656702 PinDutyStatus_05 "Measured PWM duty in input";
CM_ SG_ 2583656702 PinDutyStatus_06 "Measured PWM duty in input";
CM_ SG_ 2583656702 PinDutyStatus_07 "Measured PWM duty in input";
CM_ SG_ 2583656702 PinDutyStatus_08 "Measured PWM duty in input";
CM_ BO_ 2583656446 "Measured frequency on inputs 1";
CM_ SG_ 2583656446 PinFrequencyStatus_01 "Measured frequency on input 01";
CM_ SG_ 2583656446 PinFrequencyStatus_02 "Measured frequency on input 02";
CM_ SG_ 2583656446 PinFrequencyStatus_03 "Measured frequency on input 03";
CM_ SG_ 2583656446 PinFrequencyStatus_04 "Measured frequency on input 04";
CM_ BO_ 2583646462 "Measured frequency on inputs 2";
CM_ SG_ 2583646462 PinFrequencyStatus_05 "Measured frequency on input 05";
CM_ SG_ 2583646462 PinFrequencyStatus_06 "Measured frequency on input 06";
CM_ SG_ 2583646462 PinFrequencyStatus_07 "Measured frequency on input 07";
CM_ SG_ 2583646462 PinFrequencyStatus_08 "Measured frequency on input 08";
CM_ BO_ 2583656190 "Bridge status";
CM_ BO_ 2583647742 "Measured output current";
CM_ BO_ 2583647998 "Measured output current";
CM_ BO_ 2583648254 "Measured output current";
CM_ BO_ 2583648510 "Measured output current";
CM_ BO_ 2583655166 "Measured output current";
CM_ BO_ 2583655422 "Measured output current";
CM_ BO_ 2583655678 "Measured output current";
CM_ BO_ 2583655934 "Measured output current";
CM_ BO_ 2582845950 "Measured output current";
CM_ BO_ 2583648766 "Diagnostic state";
CM_ BO_ 2583649022 "Diagnostic state";
CM_ BO_ 2582847486 "Diagnostic state";
CM_ BO_ 2583651326 "Current configured output duty value";
CM_ SG_ 2583651326 DutyStatus_01 "Configured PWM duty on output";
CM_ SG_ 2583651326 DutyStatus_02 "Configured PWM duty on output";
CM_ SG_ 2583651326 DutyStatus_03 "Configured PWM duty on output";
CM_ SG_ 2583651326 DutyStatus_04 "Configured PWM duty on output";
CM_ SG_ 2583651326 DutyStatus_05 "Configured PWM duty on output";
CM_ SG_ 2583651326 DutyStatus_06 "Configured PWM duty on output";
CM_ SG_ 2583651326 DutyStatus_07 "Configured PWM duty on output";
CM_ SG_ 2583651326 DutyStatus_08 "Configured PWM duty on output";
CM_ BO_ 2583651582 "Current configured output duty value";
CM_ SG_ 2583651582 DutyStatus_09 "Configured PWM duty on output";
CM_ SG_ 2583651582 DutyStatus_10 "Configured PWM duty on output";
CM_ SG_ 2583651582 DutyStatus_11 "Configured PWM duty on output";
CM_ SG_ 2583651582 DutyStatus_12 "Configured PWM duty on output";
CM_ SG_ 2583651582 DutyStatus_13 "Configured PWM duty on output";
CM_ SG_ 2583651582 DutyStatus_14 "Configured PWM duty on output";
CM_ SG_ 2583651582 DutyStatus_15 "Configured PWM duty on output";
CM_ SG_ 2583651582 DutyStatus_16 "Configured PWM duty on output";
CM_ BO_ 2583651838 "Current configured output duty value";
CM_ SG_ 2583651838 DutyStatus_17 "Configured PWM duty on output";
CM_ SG_ 2583651838 DutyStatus_18 "Configured PWM duty on output";
CM_ SG_ 2583651838 DutyStatus_19 "Configured PWM duty on output";
CM_ SG_ 2583651838 DutyStatus_20 "Configured PWM duty on output";
CM_ SG_ 2583651838 DutyStatus_21 "Configured PWM duty on output";
CM_ SG_ 2583651838 DutyStatus_22 "Configured PWM duty on output";
CM_ SG_ 2583651838 DutyStatus_23 "Configured PWM duty on output";
CM_ SG_ 2583651838 DutyStatus_24 "Configured PWM duty on output";
CM_ BO_ 2583652094 "Current configured output duty value";
CM_ SG_ 2583652094 DutyStatus_25 "Configured PWM duty on output";
CM_ SG_ 2583652094 DutyStatus_26 "Configured PWM duty on output";
CM_ SG_ 2583652094 DutyStatus_27 "Configured PWM duty on output";
CM_ SG_ 2583652094 DutyStatus_28 "Configured PWM duty on output";
CM_ SG_ 2583652094 DutyStatus_29 "Configured PWM duty on output";
CM_ SG_ 2583652094 DutyStatus_30 "Configured PWM duty on output";
CM_ SG_ 2583652094 DutyStatus_31 "Configured PWM duty on output";
CM_ SG_ 2583652094 DutyStatus_32 "Configured PWM duty on output";
CM_ BO_ 2582847742 "Current configured output duty value";
CM_ SG_ 2582847742 DutyStatus_01 "Configured PWM duty on output";
CM_ SG_ 2582847742 DutyStatus_02 "Configured PWM duty on output";
CM_ SG_ 2582847742 DutyStatus_03 "Configured PWM duty on output";
CM_ SG_ 2582847742 DutyStatus_04 "Configured PWM duty on output";
CM_ SG_ 2582847742 DutyStatus_05 "Configured PWM duty on output";
CM_ SG_ 2582847742 DutyStatus_06 "Configured PWM duty on output";
CM_ SG_ 2582847742 DutyStatus_07 "Configured PWM duty on output";
CM_ SG_ 2582847742 DutyStatus_08 "Configured PWM duty on output";
CM_ SG_ 2582847742 DutyStatus_09 "Configured PWM duty on output";
CM_ SG_ 2582847742 DutyStatus_10 "Configured PWM duty on output";
CM_ SG_ 2582847742 DutyStatus_11 "Configured PWM duty on output";
CM_ SG_ 2582847742 DutyStatus_12 "Configured PWM duty on output";
CM_ SG_ 2582847742 DutyStatus_13 "Configured PWM duty on output";
CM_ SG_ 2582847742 DutyStatus_14 "Configured PWM duty on output";
CM_ SG_ 2582847742 DutyStatus_15 "Configured PWM duty on output";
CM_ SG_ 2582847742 DutyStatus_16 "Configured PWM duty on output";
CM_ SG_ 2582847742 DutyStatus_17 "Configured PWM duty on output";
CM_ SG_ 2582847742 DutyStatus_18 "Configured PWM duty on output";
CM_ SG_ 2582847742 DutyStatus_19 "Configured PWM duty on output";
CM_ SG_ 2582847742 DutyStatus_20 "Configured PWM duty on output";
CM_ SG_ 2582847742 DutyStatus_21 "Configured PWM duty on output";
CM_ SG_ 2582847742 DutyStatus_22 "Configured PWM duty on output";
CM_ SG_ 2582847742 DutyStatus_23 "Configured PWM duty on output";
CM_ SG_ 2582847742 DutyStatus_24 "Configured PWM duty on output";
CM_ SG_ 2582847742 DutyStatus_25 "Configured PWM duty on output";
CM_ SG_ 2582847742 DutyStatus_26 "Configured PWM duty on output";
CM_ SG_ 2582847742 DutyStatus_27 "Configured PWM duty on output";
CM_ SG_ 2582847742 DutyStatus_28 "Configured PWM duty on output";
CM_ SG_ 2582847742 DutyStatus_29 "Configured PWM duty on output";
CM_ SG_ 2582847742 DutyStatus_30 "Configured PWM duty on output";
CM_ SG_ 2582847742 DutyStatus_31 "Configured PWM duty on output";
CM_ SG_ 2582847742 DutyStatus_32 "Configured PWM duty on output";
CM_ BO_ 2582843646 "Faults count";
CM_ SG_ 2582843646 FaultCountStatus_01 "Detected faults count";
CM_ SG_ 2582843646 FaultCountStatus_02 "Detected faults count";
CM_ SG_ 2582843646 FaultCountStatus_03 "Detected faults count";
CM_ SG_ 2582843646 FaultCountStatus_04 "Detected faults count";
CM_ BO_ 2582843902 "Faults count";
CM_ SG_ 2582843902 FaultCountStatus_05 "Detected faults count";
CM_ SG_ 2582843902 FaultCountStatus_06 "Detected faults count";
CM_ SG_ 2582843902 FaultCountStatus_07 "Detected faults count";
CM_ SG_ 2582843902 FaultCountStatus_08 "Detected faults count";
CM_ BO_ 2582844158 "Faults count";
CM_ SG_ 2582844158 FaultCountStatus_09 "Detected faults count";
CM_ SG_ 2582844158 FaultCountStatus_10 "Detected faults count";
CM_ SG_ 2582844158 FaultCountStatus_11 "Detected faults count";
CM_ SG_ 2582844158 FaultCountStatus_12 "Detected faults count";
CM_ BO_ 2582844414 "Faults count";
CM_ SG_ 2582844414 FaultCountStatus_13 "Detected faults count";
CM_ SG_ 2582844414 FaultCountStatus_14 "Detected faults count";
CM_ SG_ 2582844414 FaultCountStatus_15 "Detected faults count";
CM_ SG_ 2582844414 FaultCountStatus_16 "Detected faults count";
CM_ BO_ 2582844670 "Faults count";
CM_ SG_ 2582844670 FaultCountStatus_17 "Detected faults count";
CM_ SG_ 2582844670 FaultCountStatus_18 "Detected faults count";
CM_ SG_ 2582844670 FaultCountStatus_19 "Detected faults count";
CM_ SG_ 2582844670 FaultCountStatus_20 "Detected faults count";
CM_ BO_ 2582844926 "Faults count";
CM_ SG_ 2582844926 FaultCountStatus_21 "Detected faults count";
CM_ SG_ 2582844926 FaultCountStatus_22 "Detected faults count";
CM_ SG_ 2582844926 FaultCountStatus_23 "Detected faults count";
CM_ SG_ 2582844926 FaultCountStatus_24 "Detected faults count";
CM_ BO_ 2582845182 "Faults count";
CM_ SG_ 2582845182 FaultCountStatus_25 "Detected faults count";
CM_ SG_ 2582845182 FaultCountStatus_26 "Detected faults count";
CM_ SG_ 2582845182 FaultCountStatus_27 "Detected faults count";
CM_ SG_ 2582845182 FaultCountStatus_28 "Detected faults count";
CM_ BO_ 2582845438 "Faults count";
CM_ SG_ 2582845438 FaultCountStatus_29 "Detected faults count";
CM_ SG_ 2582845438 FaultCountStatus_30 "Detected faults count";
CM_ SG_ 2582845438 FaultCountStatus_31 "Detected faults count";
CM_ SG_ 2582845438 FaultCountStatus_32 "Detected faults count";
BA_DEF_ "BusType" STRING ;
BA_DEF_ "DBName" STRING ;
BA_DEF_ "DatabaseVersion" STRING ;
BA_DEF_ BO_ "GenMsgCycleTime" INT 0 3600000;
BA_DEF_ BO_ "GenMsgILSupport" ENUM "No","Yes";
BA_DEF_ BO_ "GenMsgRequestable" INT 0 1;
BA_DEF_ BO_ "GenMsgSendType" ENUM "cyclic","NotUsed","NotUsed","NotUsed","NotUsed","NotUsed","NotUsed","IfActive","noMsgSendType";
BA_DEF_ SG_ "GenSigEVName" STRING ;
BA_DEF_ SG_ "GenSigILSupport" ENUM "No","Yes";
BA_DEF_ SG_ "GenSigSendType" ENUM "Cyclic","OnWrite","OnWriteWithRepetition","OnChange","OnChangeWithRepetition","IfActive","IfActiveWithRepetition","NoSigSendType";
BA_DEF_ SG_ "GenSigStartValue" INT 0 2147483647;
BA_DEF_ BU_ "NmStationAddress" INT 0 255;
BA_DEF_ "ProtocolType" STRING ;
BA_DEF_ "SAE_J1939_21_SpecVersion" STRING ;
BA_DEF_ "SAE_J1939_71_SpecVersion" STRING ;
BA_DEF_ "SAE_J1939_73_SpecVersion" STRING ;
BA_DEF_ "SAE_J1939_75_SpecVersion" STRING ;
BA_DEF_ "SAE_J1939_81_SpecVersion" STRING ;
BA_DEF_ "SAE_J1939_DA_SpecVersion" STRING ;
BA_DEF_ SG_ "SPN" INT 0 524287;
BA_DEF_ BO_ "SendOnChange" ENUM "No","Yes";
BA_DEF_ SG_ "SigType" ENUM "Default","Range","RangeSigned","ASCII","Discrete","Control","ReferencePGN","DTC","StringDelimiter","StringLength","StringLengthControl","MessageCounter","MessageChecksum";
BA_DEF_ BO_ "VFrameFormat" ENUM "StandardCAN","ExtendedCAN","reserved","J1939PG","reserved","reserved","reserved","reserved","reserved","reserved","reserved","reserved","reserved","reserved","StandardCAN_FD","ExtendedCAN_FD";
BA_DEF_DEF_ "BusType" "";
BA_DEF_DEF_ "DBName" "";
BA_DEF_DEF_ "DatabaseVersion" "";
BA_DEF_DEF_ "GenMsgCycleTime" 0;
BA_DEF_DEF_ "GenMsgILSupport" "Yes";
BA_DEF_DEF_ "GenMsgRequestable" 1;
BA_DEF_DEF_ "GenMsgSendType" "noMsgSendType";
BA_DEF_DEF_ "GenSigEVName" "Env@Nodename_@Signame";
BA_DEF_DEF_ "GenSigILSupport" "Yes";
BA_DEF_DEF_ "GenSigSendType" "NoSigSendType";
BA_DEF_DEF_ "GenSigStartValue" 0;
BA_DEF_DEF_ "NmStationAddress" 254;
BA_DEF_DEF_ "ProtocolType" "";
BA_DEF_DEF_ "SAE_J1939_21_SpecVersion" "";
BA_DEF_DEF_ "SAE_J1939_71_SpecVersion" "";
BA_DEF_DEF_ "SAE_J1939_73_SpecVersion" "";
BA_DEF_DEF_ "SAE_J1939_75_SpecVersion" "";
BA_DEF_DEF_ "SAE_J1939_81_SpecVersion" "";
BA_DEF_DEF_ "SAE_J1939_DA_SpecVersion" "";
BA_DEF_DEF_ "SPN" 0;
BA_DEF_DEF_ "SendOnChange" "No";
BA_DEF_DEF_ "SigType" "Default";
BA_DEF_DEF_ "VFrameFormat" "J1939PG";
BA_ "BusType" "CAN";
BA_ "DBName" "Arrival_UIO";
BA_ "DatabaseVersion" "8.5";
BA_ "ProtocolType" "J1939";
BA_ "SAE_J1939_21_SpecVersion" "2006-10";
BA_ "SAE_J1939_71_SpecVersion" "2012-10";
BA_ "SAE_J1939_73_SpecVersion" "2012-10";
BA_ "SAE_J1939_75_SpecVersion" "2012-05";
BA_ "SAE_J1939_81_SpecVersion" "2012-05";
BA_ "SAE_J1939_DA_SpecVersion" "2015-01";
BA_ "GenMsgCycleTime" BO_ 2369322750 100;
BA_ "GenMsgRequestable" BO_ 2369322750 0;
BA_ "GenMsgSendType" BO_ 2369322750 0;
BA_ "SendOnChange" BO_ 2369322750 1;
BA_ "GenMsgCycleTime" BO_ 2369650430 100;
BA_ "GenMsgRequestable" BO_ 2369650430 0;
BA_ "GenMsgSendType" BO_ 2369650430 0;
BA_ "SendOnChange" BO_ 2369650430 1;
BA_ "GenMsgCycleTime" BO_ 2369715966 100;
BA_ "GenMsgRequestable" BO_ 2369715966 0;
BA_ "GenMsgSendType" BO_ 2369715966 0;
BA_ "SendOnChange" BO_ 2369715966 1;
BA_ "GenMsgCycleTime" BO_ 2369781502 100;
BA_ "GenMsgRequestable" BO_ 2369781502 0;
BA_ "GenMsgSendType" BO_ 2369781502 0;
BA_ "SendOnChange" BO_ 2369781502 1;
BA_ "GenMsgCycleTime" BO_ 2369847038 100;
BA_ "GenMsgRequestable" BO_ 2369847038 0;
BA_ "GenMsgSendType" BO_ 2369847038 0;
BA_ "SendOnChange" BO_ 2369847038 1;
BA_ "GenMsgCycleTime" BO_ 2370043646 100;
BA_ "GenMsgRequestable" BO_ 2370043646 0;
BA_ "GenMsgSendType" BO_ 2370043646 0;
BA_ "GenMsgCycleTime" BO_ 2369388286 100;
BA_ "GenMsgRequestable" BO_ 2369388286 0;
BA_ "GenMsgSendType" BO_ 2369388286 0;
BA_ "SendOnChange" BO_ 2369388286 1;
BA_ "GenMsgCycleTime" BO_ 2369453822 100;
BA_ "GenMsgRequestable" BO_ 2369453822 0;
BA_ "GenMsgSendType" BO_ 2369453822 0;
BA_ "SendOnChange" BO_ 2369453822 1;
BA_ "GenMsgCycleTime" BO_ 2369519358 100;
BA_ "GenMsgRequestable" BO_ 2369519358 0;
BA_ "GenMsgSendType" BO_ 2369519358 0;
BA_ "SendOnChange" BO_ 2369519358 1;
BA_ "GenMsgCycleTime" BO_ 2369584894 100;
BA_ "GenMsgRequestable" BO_ 2369584894 0;
BA_ "GenMsgSendType" BO_ 2369584894 0;
BA_ "SendOnChange" BO_ 2369584894 1;
BA_ "GenMsgCycleTime" BO_ 2369912574 1000;
BA_ "GenMsgRequestable" BO_ 2369912574 0;
BA_ "GenMsgSendType" BO_ 2369912574 0;
BA_ "SendOnChange" BO_ 2369912574 1;
BA_ "GenMsgCycleTime" BO_ 2369978110 1000;
BA_ "GenMsgRequestable" BO_ 2369978110 0;
BA_ "GenMsgSendType" BO_ 2369978110 0;
BA_ "SendOnChange" BO_ 2369978110 1;
BA_ "GenMsgCycleTime" BO_ 2370109182 100;
BA_ "GenMsgRequestable" BO_ 2370109182 0;
BA_ "GenMsgSendType" BO_ 2370109182 0;
BA_ "SendOnChange" BO_ 2370109182 1;
BA_ "GenMsgCycleTime" BO_ 2370174718 100;
BA_ "GenMsgRequestable" BO_ 2370174718 0;
BA_ "GenMsgSendType" BO_ 2370174718 0;
BA_ "SendOnChange" BO_ 2370174718 1;
BA_ "GenMsgCycleTime" BO_ 2370240254 100;
BA_ "GenMsgRequestable" BO_ 2370240254 0;
BA_ "GenMsgSendType" BO_ 2370240254 0;
BA_ "SendOnChange" BO_ 2370240254 1;
BA_ "GenMsgCycleTime" BO_ 2370305790 100;
BA_ "GenMsgRequestable" BO_ 2370305790 0;
BA_ "GenMsgSendType" BO_ 2370305790 0;
BA_ "SendOnChange" BO_ 2370305790 1;
BA_ "GenMsgCycleTime" BO_ 2583656702 100;
BA_ "GenMsgRequestable" BO_ 2583656702 0;
BA_ "GenMsgSendType" BO_ 2583656702 0;
BA_ "GenMsgCycleTime" BO_ 2583656446 100;
BA_ "GenMsgRequestable" BO_ 2583656446 0;
BA_ "GenMsgSendType" BO_ 2583656446 0;
BA_ "GenMsgCycleTime" BO_ 2583646462 100;
BA_ "GenMsgRequestable" BO_ 2583646462 0;
BA_ "GenMsgSendType" BO_ 2583646462 0;
BA_ "GenMsgCycleTime" BO_ 2583656190 100;
BA_ "GenMsgRequestable" BO_ 2583656190 0;
BA_ "GenMsgSendType" BO_ 2583656190 0;
BA_ "GenMsgCycleTime" BO_ 2583647742 100;
BA_ "GenMsgRequestable" BO_ 2583647742 0;
BA_ "GenMsgSendType" BO_ 2583647742 0;
BA_ "GenMsgCycleTime" BO_ 2583647998 100;
BA_ "GenMsgRequestable" BO_ 2583647998 0;
BA_ "GenMsgSendType" BO_ 2583647998 0;
BA_ "GenMsgCycleTime" BO_ 2583648254 100;
BA_ "GenMsgRequestable" BO_ 2583648254 0;
BA_ "GenMsgSendType" BO_ 2583648254 0;
BA_ "GenMsgCycleTime" BO_ 2583648510 100;
BA_ "GenMsgRequestable" BO_ 2583648510 0;
BA_ "GenMsgSendType" BO_ 2583648510 0;
BA_ "GenMsgCycleTime" BO_ 2583655166 100;
BA_ "GenMsgRequestable" BO_ 2583655166 0;
BA_ "GenMsgSendType" BO_ 2583655166 0;
BA_ "GenMsgCycleTime" BO_ 2583655422 100;
BA_ "GenMsgRequestable" BO_ 2583655422 0;
BA_ "GenMsgSendType" BO_ 2583655422 0;
BA_ "GenMsgCycleTime" BO_ 2583655678 100;
BA_ "GenMsgRequestable" BO_ 2583655678 0;
BA_ "GenMsgSendType" BO_ 2583655678 0;
BA_ "GenMsgCycleTime" BO_ 2583655934 100;
BA_ "GenMsgRequestable" BO_ 2583655934 0;
BA_ "GenMsgSendType" BO_ 2583655934 0;
BA_ "GenMsgCycleTime" BO_ 2582845950 100;
BA_ "GenMsgRequestable" BO_ 2582845950 0;
BA_ "GenMsgSendType" BO_ 2582845950 0;
BA_ "GenMsgCycleTime" BO_ 2583648766 1000;
BA_ "GenMsgRequestable" BO_ 2583648766 0;
BA_ "GenMsgSendType" BO_ 2583648766 0;
BA_ "GenMsgCycleTime" BO_ 2583649022 1000;
BA_ "GenMsgRequestable" BO_ 2583649022 0;
BA_ "GenMsgSendType" BO_ 2583649022 0;
BA_ "GenMsgCycleTime" BO_ 2582847486 1000;
BA_ "GenMsgRequestable" BO_ 2582847486 0;
BA_ "GenMsgSendType" BO_ 2582847486 0;
BA_ "GenMsgCycleTime" BO_ 2583651326 100;
BA_ "GenMsgRequestable" BO_ 2583651326 0;
BA_ "GenMsgSendType" BO_ 2583651326 0;
BA_ "GenMsgCycleTime" BO_ 2583651582 100;
BA_ "GenMsgRequestable" BO_ 2583651582 0;
BA_ "GenMsgSendType" BO_ 2583651582 0;
BA_ "GenMsgCycleTime" BO_ 2583651838 100;
BA_ "GenMsgRequestable" BO_ 2583651838 0;
BA_ "GenMsgSendType" BO_ 2583651838 0;
BA_ "GenMsgCycleTime" BO_ 2583652094 100;
BA_ "GenMsgRequestable" BO_ 2583652094 0;
BA_ "GenMsgSendType" BO_ 2583652094 0;
BA_ "GenMsgCycleTime" BO_ 2582847742 100;
BA_ "GenMsgRequestable" BO_ 2582847742 0;
BA_ "GenMsgSendType" BO_ 2582847742 0;
BA_ "GenMsgCycleTime" BO_ 2582843646 1000;
BA_ "GenMsgRequestable" BO_ 2582843646 0;
BA_ "GenMsgSendType" BO_ 2582843646 0;
BA_ "GenMsgCycleTime" BO_ 2582843902 1000;
BA_ "GenMsgRequestable" BO_ 2582843902 0;
BA_ "GenMsgSendType" BO_ 2582843902 0;
BA_ "GenMsgCycleTime" BO_ 2582844158 1000;
BA_ "GenMsgRequestable" BO_ 2582844158 0;
BA_ "GenMsgSendType" BO_ 2582844158 0;
BA_ "GenMsgCycleTime" BO_ 2582844414 1000;
BA_ "GenMsgRequestable" BO_ 2582844414 0;
BA_ "GenMsgSendType" BO_ 2582844414 0;
BA_ "GenMsgCycleTime" BO_ 2582844670 1000;
BA_ "GenMsgRequestable" BO_ 2582844670 0;
BA_ "GenMsgSendType" BO_ 2582844670 0;
BA_ "GenMsgCycleTime" BO_ 2582844926 1000;
BA_ "GenMsgRequestable" BO_ 2582844926 0;
BA_ "GenMsgSendType" BO_ 2582844926 0;
BA_ "GenMsgCycleTime" BO_ 2582845182 1000;
BA_ "GenMsgRequestable" BO_ 2582845182 0;
BA_ "GenMsgSendType" BO_ 2582845182 0;
BA_ "GenMsgCycleTime" BO_ 2582845438 1000;
BA_ "GenMsgRequestable" BO_ 2582845438 0;
BA_ "GenMsgSendType" BO_ 2582845438 0;
BA_ "SPN" SG_ 2369322750 BridgeModeCommand_b01 516600;
BA_ "SPN" SG_ 2369322750 BridgeModeCommand_b02 516601;
BA_ "SPN" SG_ 2369322750 BridgeModeCommand_b03 516602;
BA_ "SPN" SG_ 2369322750 BridgeModeCommand_b04 516603;
BA_ "SPN" SG_ 2369322750 BridgeModeCommand_b05 516604;
BA_ "SPN" SG_ 2369322750 BridgeModeCommand_b06 516605;
BA_ "SPN" SG_ 2369322750 BridgeModeCommand_b07 516606;
BA_ "SPN" SG_ 2369322750 BridgeModeCommand_b08 516607;
BA_ "SPN" SG_ 2369650430 DutyCommand_01 516608;
BA_ "SigType" SG_ 2369650430 DutyCommand_01 1;
BA_ "SPN" SG_ 2369650430 DutyCommand_02 516609;
BA_ "SigType" SG_ 2369650430 DutyCommand_02 1;
BA_ "SPN" SG_ 2369650430 DutyCommand_03 516610;
BA_ "SigType" SG_ 2369650430 DutyCommand_03 1;
BA_ "SPN" SG_ 2369650430 DutyCommand_04 516611;
BA_ "SigType" SG_ 2369650430 DutyCommand_04 1;
BA_ "SPN" SG_ 2369650430 DutyCommand_05 516612;
BA_ "SigType" SG_ 2369650430 DutyCommand_05 1;
BA_ "SPN" SG_ 2369650430 DutyCommand_06 516613;
BA_ "SigType" SG_ 2369650430 DutyCommand_06 1;
BA_ "SPN" SG_ 2369650430 DutyCommand_07 516614;
BA_ "SigType" SG_ 2369650430 DutyCommand_07 1;
BA_ "SPN" SG_ 2369650430 DutyCommand_08 516615;
BA_ "SigType" SG_ 2369650430 DutyCommand_08 1;
BA_ "SPN" SG_ 2369715966 DutyCommand_09 516616;
BA_ "SigType" SG_ 2369715966 DutyCommand_09 1;
BA_ "SPN" SG_ 2369715966 DutyCommand_10 516617;
BA_ "SigType" SG_ 2369715966 DutyCommand_10 1;
BA_ "SPN" SG_ 2369715966 DutyCommand_11 516618;
BA_ "SigType" SG_ 2369715966 DutyCommand_11 1;
BA_ "SPN" SG_ 2369715966 DutyCommand_12 516619;
BA_ "SigType" SG_ 2369715966 DutyCommand_12 1;
BA_ "SPN" SG_ 2369715966 DutyCommand_13 516620;
BA_ "SigType" SG_ 2369715966 DutyCommand_13 1;
BA_ "SPN" SG_ 2369715966 DutyCommand_14 516621;
BA_ "SigType" SG_ 2369715966 DutyCommand_14 1;
BA_ "SPN" SG_ 2369715966 DutyCommand_15 516622;
BA_ "SigType" SG_ 2369715966 DutyCommand_15 1;
BA_ "SPN" SG_ 2369715966 DutyCommand_16 516623;
BA_ "SigType" SG_ 2369715966 DutyCommand_16 1;
BA_ "SPN" SG_ 2369781502 DutyCommand_17 516624;
BA_ "SigType" SG_ 2369781502 DutyCommand_17 1;
BA_ "SPN" SG_ 2369781502 DutyCommand_18 516625;
BA_ "SigType" SG_ 2369781502 DutyCommand_18 1;
BA_ "SPN" SG_ 2369781502 DutyCommand_19 516626;
BA_ "SigType" SG_ 2369781502 DutyCommand_19 1;
BA_ "SPN" SG_ 2369781502 DutyCommand_20 516627;
BA_ "SigType" SG_ 2369781502 DutyCommand_20 1;
BA_ "SPN" SG_ 2369781502 DutyCommand_21 516628;
BA_ "SigType" SG_ 2369781502 DutyCommand_21 1;
BA_ "SPN" SG_ 2369781502 DutyCommand_22 516629;
BA_ "SigType" SG_ 2369781502 DutyCommand_22 1;
BA_ "SPN" SG_ 2369781502 DutyCommand_23 516630;
BA_ "SigType" SG_ 2369781502 DutyCommand_23 1;
BA_ "SPN" SG_ 2369781502 DutyCommand_24 516631;
BA_ "SigType" SG_ 2369781502 DutyCommand_24 1;
BA_ "SPN" SG_ 2369847038 DutyCommand_25 516632;
BA_ "SigType" SG_ 2369847038 DutyCommand_25 1;
BA_ "SPN" SG_ 2369847038 DutyCommand_26 516633;
BA_ "SigType" SG_ 2369847038 DutyCommand_26 1;
BA_ "SPN" SG_ 2369847038 DutyCommand_27 516634;
BA_ "SigType" SG_ 2369847038 DutyCommand_27 1;
BA_ "SPN" SG_ 2369847038 DutyCommand_28 516635;
BA_ "SigType" SG_ 2369847038 DutyCommand_28 1;
BA_ "SPN" SG_ 2369847038 DutyCommand_29 516636;
BA_ "SigType" SG_ 2369847038 DutyCommand_29 1;
BA_ "SPN" SG_ 2369847038 DutyCommand_30 516637;
BA_ "SigType" SG_ 2369847038 DutyCommand_30 1;
BA_ "SPN" SG_ 2369847038 DutyCommand_31 516638;
BA_ "SigType" SG_ 2369847038 DutyCommand_31 1;
BA_ "SPN" SG_ 2369847038 DutyCommand_32 516639;
BA_ "SigType" SG_ 2369847038 DutyCommand_32 1;
BA_ "SPN" SG_ 2370043646 DutyCommand_01 516608;
BA_ "SigType" SG_ 2370043646 DutyCommand_01 1;
BA_ "SPN" SG_ 2370043646 DutyCommand_02 516609;
BA_ "SigType" SG_ 2370043646 DutyCommand_02 1;
BA_ "SPN" SG_ 2370043646 DutyCommand_03 516610;
BA_ "SigType" SG_ 2370043646 DutyCommand_03 1;
BA_ "SPN" SG_ 2370043646 DutyCommand_04 516611;
BA_ "SigType" SG_ 2370043646 DutyCommand_04 1;
BA_ "SPN" SG_ 2370043646 DutyCommand_05 516612;
BA_ "SigType" SG_ 2370043646 DutyCommand_05 1;
BA_ "SPN" SG_ 2370043646 DutyCommand_06 516613;
BA_ "SigType" SG_ 2370043646 DutyCommand_06 1;
BA_ "SPN" SG_ 2370043646 DutyCommand_07 516614;
BA_ "SigType" SG_ 2370043646 DutyCommand_07 1;
BA_ "SPN" SG_ 2370043646 DutyCommand_08 516615;
BA_ "SigType" SG_ 2370043646 DutyCommand_08 1;
BA_ "SPN" SG_ 2370043646 DutyCommand_09 516616;
BA_ "SigType" SG_ 2370043646 DutyCommand_09 1;
BA_ "SPN" SG_ 2370043646 DutyCommand_10 516617;
BA_ "SigType" SG_ 2370043646 DutyCommand_10 1;
BA_ "SPN" SG_ 2370043646 DutyCommand_11 516618;
BA_ "SigType" SG_ 2370043646 DutyCommand_11 1;
BA_ "SPN" SG_ 2370043646 DutyCommand_12 516619;
BA_ "SigType" SG_ 2370043646 DutyCommand_12 1;
BA_ "SPN" SG_ 2370043646 DutyCommand_13 516620;
BA_ "SigType" SG_ 2370043646 DutyCommand_13 1;
BA_ "SPN" SG_ 2370043646 DutyCommand_14 516621;
BA_ "SigType" SG_ 2370043646 DutyCommand_14 1;
BA_ "SPN" SG_ 2370043646 DutyCommand_15 516622;
BA_ "SigType" SG_ 2370043646 DutyCommand_15 1;
BA_ "SPN" SG_ 2370043646 DutyCommand_16 516623;
BA_ "SigType" SG_ 2370043646 DutyCommand_16 1;
BA_ "SPN" SG_ 2370043646 DutyCommand_17 516624;
BA_ "SigType" SG_ 2370043646 DutyCommand_17 1;
BA_ "SPN" SG_ 2370043646 DutyCommand_18 516625;
BA_ "SigType" SG_ 2370043646 DutyCommand_18 1;
BA_ "SPN" SG_ 2370043646 DutyCommand_19 516626;
BA_ "SigType" SG_ 2370043646 DutyCommand_19 1;
BA_ "SPN" SG_ 2370043646 DutyCommand_20 516627;
BA_ "SigType" SG_ 2370043646 DutyCommand_20 1;
BA_ "SPN" SG_ 2370043646 DutyCommand_21 516628;
BA_ "SigType" SG_ 2370043646 DutyCommand_21 1;
BA_ "SPN" SG_ 2370043646 DutyCommand_22 516629;
BA_ "SigType" SG_ 2370043646 DutyCommand_22 1;
BA_ "SPN" SG_ 2370043646 DutyCommand_23 516630;
BA_ "SigType" SG_ 2370043646 DutyCommand_23 1;
BA_ "SPN" SG_ 2370043646 DutyCommand_24 516631;
BA_ "SigType" SG_ 2370043646 DutyCommand_24 1;
BA_ "SPN" SG_ 2370043646 DutyCommand_25 516632;
BA_ "SigType" SG_ 2370043646 DutyCommand_25 1;
BA_ "SPN" SG_ 2370043646 DutyCommand_26 516633;
BA_ "SigType" SG_ 2370043646 DutyCommand_26 1;
BA_ "SPN" SG_ 2370043646 DutyCommand_27 516634;
BA_ "SigType" SG_ 2370043646 DutyCommand_27 1;
BA_ "SPN" SG_ 2370043646 DutyCommand_28 516635;
BA_ "SigType" SG_ 2370043646 DutyCommand_28 1;
BA_ "SPN" SG_ 2370043646 DutyCommand_29 516636;
BA_ "SigType" SG_ 2370043646 DutyCommand_29 1;
BA_ "SPN" SG_ 2370043646 DutyCommand_30 516637;
BA_ "SigType" SG_ 2370043646 DutyCommand_30 1;
BA_ "SPN" SG_ 2370043646 DutyCommand_31 516638;
BA_ "SigType" SG_ 2370043646 DutyCommand_31 1;
BA_ "SPN" SG_ 2370043646 DutyCommand_32 516639;
BA_ "SigType" SG_ 2370043646 DutyCommand_32 1;
BA_ "SPN" SG_ 2369388286 PinModeCommand_01 516640;
BA_ "SPN" SG_ 2369388286 PinPullModeCommand_01 516641;
BA_ "SPN" SG_ 2369388286 LoadDetectionCommand_01 516642;
BA_ "SPN" SG_ 2369388286 PinModeCommand_02 516643;
BA_ "SPN" SG_ 2369388286 PinPullModeCommand_02 516644;
BA_ "SPN" SG_ 2369388286 LoadDetectionCommand_02 516645;
BA_ "SPN" SG_ 2369388286 PinModeCommand_03 516646;
BA_ "SPN" SG_ 2369388286 PinPullModeCommand_03 516647;
BA_ "SPN" SG_ 2369388286 LoadDetectionCommand_03 516648;
BA_ "SPN" SG_ 2369388286 PinModeCommand_04 516649;
BA_ "SPN" SG_ 2369388286 PinPullModeCommand_04 516650;
BA_ "SPN" SG_ 2369388286 LoadDetectionCommand_04 516651;
BA_ "SPN" SG_ 2369388286 PinModeCommand_05 516652;
BA_ "SPN" SG_ 2369388286 PinPullModeCommand_05 516653;
BA_ "SPN" SG_ 2369388286 LoadDetectionCommand_05 516654;
BA_ "SPN" SG_ 2369388286 PinModeCommand_06 516655;
BA_ "SPN" SG_ 2369388286 PinPullModeCommand_06 516656;
BA_ "SPN" SG_ 2369388286 LoadDetectionCommand_06 516657;
BA_ "SPN" SG_ 2369388286 PinModeCommand_07 516658;
BA_ "SPN" SG_ 2369388286 PinPullModeCommand_07 516659;
BA_ "SPN" SG_ 2369388286 LoadDetectionCommand_07 516660;
BA_ "SPN" SG_ 2369388286 PinModeCommand_08 516661;
BA_ "SPN" SG_ 2369388286 PinPullModeCommand_08 516662;
BA_ "SPN" SG_ 2369388286 LoadDetectionCommand_08 516663;
BA_ "SPN" SG_ 2369453822 PinModeCommand_09 516664;
BA_ "SPN" SG_ 2369453822 PinPullModeCommand_09 516665;
BA_ "SPN" SG_ 2369453822 LoadDetectionCommand_09 516666;
BA_ "SPN" SG_ 2369453822 PinModeCommand_10 516667;
BA_ "SPN" SG_ 2369453822 PinPullModeCommand_10 516668;
BA_ "SPN" SG_ 2369453822 LoadDetectionCommand_10 516669;
BA_ "SPN" SG_ 2369453822 PinModeCommand_11 516670;
BA_ "SPN" SG_ 2369453822 PinPullModeCommand_11 516671;
BA_ "SPN" SG_ 2369453822 LoadDetectionCommand_11 516672;
BA_ "SPN" SG_ 2369453822 PinModeCommand_12 516673;
BA_ "SPN" SG_ 2369453822 PinPullModeCommand_12 516674;
BA_ "SPN" SG_ 2369453822 LoadDetectionCommand_12 516675;
BA_ "SPN" SG_ 2369453822 PinModeCommand_13 516676;
BA_ "SPN" SG_ 2369453822 PinPullModeCommand_13 516677;
BA_ "SPN" SG_ 2369453822 LoadDetectionCommand_13 516678;
BA_ "SPN" SG_ 2369453822 PinModeCommand_14 516679;
BA_ "SPN" SG_ 2369453822 PinPullModeCommand_14 516680;
BA_ "SPN" SG_ 2369453822 LoadDetectionCommand_14 516681;
BA_ "SPN" SG_ 2369453822 PinModeCommand_15 516682;
BA_ "SPN" SG_ 2369453822 PinPullModeCommand_15 516683;
BA_ "SPN" SG_ 2369453822 LoadDetectionCommand_15 516684;
BA_ "SPN" SG_ 2369453822 PinModeCommand_16 516685;
BA_ "SPN" SG_ 2369453822 PinPullModeCommand_16 516686;
BA_ "SPN" SG_ 2369453822 LoadDetectionCommand_16 516687;
BA_ "SPN" SG_ 2369519358 PinModeCommand_17 516688;
BA_ "SPN" SG_ 2369519358 PinPullModeCommand_17 516689;
BA_ "SPN" SG_ 2369519358 LoadDetectionCommand_17 516690;
BA_ "SPN" SG_ 2369519358 PinModeCommand_18 516691;
BA_ "SPN" SG_ 2369519358 PinPullModeCommand_18 516692;
BA_ "SPN" SG_ 2369519358 LoadDetectionCommand_18 516693;
BA_ "SPN" SG_ 2369519358 PinModeCommand_19 516694;
BA_ "SPN" SG_ 2369519358 PinPullModeCommand_19 516695;
BA_ "SPN" SG_ 2369519358 LoadDetectionCommand_19 516696;
BA_ "SPN" SG_ 2369519358 PinModeCommand_20 516697;
BA_ "SPN" SG_ 2369519358 PinPullModeCommand_20 516698;
BA_ "SPN" SG_ 2369519358 LoadDetectionCommand_20 516699;
BA_ "SPN" SG_ 2369519358 PinModeCommand_21 516700;
BA_ "SPN" SG_ 2369519358 PinPullModeCommand_21 516701;
BA_ "SPN" SG_ 2369519358 LoadDetectionCommand_21 516702;
BA_ "SPN" SG_ 2369519358 PinModeCommand_22 516703;
BA_ "SPN" SG_ 2369519358 PinPullModeCommand_22 516704;
BA_ "SPN" SG_ 2369519358 LoadDetectionCommand_22 516705;
BA_ "SPN" SG_ 2369519358 PinModeCommand_23 516706;
BA_ "SPN" SG_ 2369519358 PinPullModeCommand_23 516707;
BA_ "SPN" SG_ 2369519358 LoadDetectionCommand_23 516708;
BA_ "SPN" SG_ 2369519358 PinModeCommand_24 516709;
BA_ "SPN" SG_ 2369519358 PinPullModeCommand_24 516710;
BA_ "SPN" SG_ 2369519358 LoadDetectionCommand_24 516711;
BA_ "SPN" SG_ 2369584894 PinModeCommand_25 516712;
BA_ "SPN" SG_ 2369584894 PinPullModeCommand_25 516713;
BA_ "SPN" SG_ 2369584894 LoadDetectionCommand_25 516714;
BA_ "SPN" SG_ 2369584894 PinModeCommand_26 516715;
BA_ "SPN" SG_ 2369584894 PinPullModeCommand_26 516716;
BA_ "SPN" SG_ 2369584894 LoadDetectionCommand_26 516717;
BA_ "SPN" SG_ 2369584894 PinModeCommand_27 516718;
BA_ "SPN" SG_ 2369584894 PinPullModeCommand_27 516719;
BA_ "SPN" SG_ 2369584894 LoadDetectionCommand_27 516720;
BA_ "SPN" SG_ 2369584894 PinModeCommand_28 516721;
BA_ "SPN" SG_ 2369584894 PinPullModeCommand_28 516722;
BA_ "SPN" SG_ 2369584894 LoadDetectionCommand_28 516723;
BA_ "SPN" SG_ 2369584894 PinModeCommand_29 516724;
BA_ "SPN" SG_ 2369584894 PinPullModeCommand_29 516725;
BA_ "SPN" SG_ 2369584894 LoadDetectionCommand_29 516726;
BA_ "SPN" SG_ 2369584894 PinModeCommand_30 516727;
BA_ "SPN" SG_ 2369584894 PinPullModeCommand_30 516728;
BA_ "SPN" SG_ 2369584894 LoadDetectionCommand_30 516729;
BA_ "SPN" SG_ 2369584894 PinModeCommand_31 516730;
BA_ "SPN" SG_ 2369584894 PinPullModeCommand_31 516731;
BA_ "SPN" SG_ 2369584894 LoadDetectionCommand_31 516732;
BA_ "SPN" SG_ 2369584894 PinModeCommand_32 516733;
BA_ "SPN" SG_ 2369584894 PinPullModeCommand_32 516734;
BA_ "SPN" SG_ 2369584894 LoadDetectionCommand_32 516735;
BA_ "SPN" SG_ 2369912574 PwmFrequencyCommand_01 516736;
BA_ "SPN" SG_ 2369912574 PwmFrequencyCommand_02 516737;
BA_ "SPN" SG_ 2369912574 PwmFrequencyCommand_03 516738;
BA_ "SPN" SG_ 2369912574 PwmFrequencyCommand_04 516739;
BA_ "SPN" SG_ 2369912574 PwmFrequencyCommand_05 516740;
BA_ "SPN" SG_ 2369912574 PwmFrequencyCommand_06 516741;
BA_ "SPN" SG_ 2369912574 PwmFrequencyCommand_07 516742;
BA_ "SPN" SG_ 2369912574 PwmFrequencyCommand_08 516743;
BA_ "SPN" SG_ 2369912574 PwmFrequencyCommand_09 516744;
BA_ "SPN" SG_ 2369912574 PwmFrequencyCommand_10 516745;
BA_ "SPN" SG_ 2369912574 PwmFrequencyCommand_11 516746;
BA_ "SPN" SG_ 2369912574 PwmFrequencyCommand_12 516747;
BA_ "SPN" SG_ 2369912574 PwmFrequencyCommand_13 516748;
BA_ "SPN" SG_ 2369912574 PwmFrequencyCommand_14 516749;
BA_ "SPN" SG_ 2369912574 PwmFrequencyCommand_15 516750;
BA_ "SPN" SG_ 2369912574 PwmFrequencyCommand_16 516751;
BA_ "SPN" SG_ 2369978110 PwmFrequencyCommand_17 516752;
BA_ "SPN" SG_ 2369978110 PwmFrequencyCommand_18 516753;
BA_ "SPN" SG_ 2369978110 PwmFrequencyCommand_19 516754;
BA_ "SPN" SG_ 2369978110 PwmFrequencyCommand_20 516755;
BA_ "SPN" SG_ 2369978110 PwmFrequencyCommand_21 516756;
BA_ "SPN" SG_ 2369978110 PwmFrequencyCommand_22 516757;
BA_ "SPN" SG_ 2369978110 PwmFrequencyCommand_23 516758;
BA_ "SPN" SG_ 2369978110 PwmFrequencyCommand_24 516759;
BA_ "SPN" SG_ 2369978110 PwmFrequencyCommand_25 516760;
BA_ "SPN" SG_ 2369978110 PwmFrequencyCommand_26 516761;
BA_ "SPN" SG_ 2369978110 PwmFrequencyCommand_27 516762;
BA_ "SPN" SG_ 2369978110 PwmFrequencyCommand_28 516763;
BA_ "SPN" SG_ 2369978110 PwmFrequencyCommand_29 516764;
BA_ "SPN" SG_ 2369978110 PwmFrequencyCommand_30 516765;
BA_ "SPN" SG_ 2369978110 PwmFrequencyCommand_31 516766;
BA_ "SPN" SG_ 2369978110 PwmFrequencyCommand_32 516767;
BA_ "SPN" SG_ 2370109182 VoltageCommand_01 519262;
BA_ "SigType" SG_ 2370109182 VoltageCommand_01 1;
BA_ "SPN" SG_ 2370109182 VoltageCommand_02 519263;
BA_ "SigType" SG_ 2370109182 VoltageCommand_02 1;
BA_ "SPN" SG_ 2370109182 VoltageCommand_03 519264;
BA_ "SigType" SG_ 2370109182 VoltageCommand_03 1;
BA_ "SPN" SG_ 2370109182 VoltageCommand_04 519265;
BA_ "SigType" SG_ 2370109182 VoltageCommand_04 1;
BA_ "SPN" SG_ 2370174718 VoltageCommand_05 519266;
BA_ "SigType" SG_ 2370174718 VoltageCommand_05 1;
BA_ "SPN" SG_ 2370174718 VoltageCommand_06 519267;
BA_ "SigType" SG_ 2370174718 VoltageCommand_06 1;
BA_ "SPN" SG_ 2370174718 VoltageCommand_07 519268;
BA_ "SigType" SG_ 2370174718 VoltageCommand_07 1;
BA_ "SPN" SG_ 2370174718 VoltageCommand_08 519269;
BA_ "SigType" SG_ 2370174718 VoltageCommand_08 1;
BA_ "SPN" SG_ 2370240254 VoltageCommand_09 519270;
BA_ "SigType" SG_ 2370240254 VoltageCommand_09 1;
BA_ "SPN" SG_ 2370240254 VoltageCommand_10 519271;
BA_ "SigType" SG_ 2370240254 VoltageCommand_10 1;
BA_ "SPN" SG_ 2370240254 VoltageCommand_11 519272;
BA_ "SigType" SG_ 2370240254 VoltageCommand_11 1;
BA_ "SPN" SG_ 2370240254 VoltageCommand_12 519273;
BA_ "SigType" SG_ 2370240254 VoltageCommand_12 1;
BA_ "SPN" SG_ 2370305790 VoltageCommand_13 519274;
BA_ "SigType" SG_ 2370305790 VoltageCommand_13 1;
BA_ "SPN" SG_ 2370305790 VoltageCommand_14 519275;
BA_ "SigType" SG_ 2370305790 VoltageCommand_14 1;
BA_ "SPN" SG_ 2370305790 VoltageCommand_15 519276;
BA_ "SigType" SG_ 2370305790 VoltageCommand_15 1;
BA_ "SPN" SG_ 2370305790 VoltageCommand_16 519277;
BA_ "SigType" SG_ 2370305790 VoltageCommand_16 1;
BA_ "SPN" SG_ 2583656702 PinDutyStatus_01 516768;
BA_ "SigType" SG_ 2583656702 PinDutyStatus_01 1;
BA_ "SPN" SG_ 2583656702 PinDutyStatus_02 516769;
BA_ "SigType" SG_ 2583656702 PinDutyStatus_02 1;
BA_ "SPN" SG_ 2583656702 PinDutyStatus_03 516770;
BA_ "SigType" SG_ 2583656702 PinDutyStatus_03 1;
BA_ "SPN" SG_ 2583656702 PinDutyStatus_04 516771;
BA_ "SigType" SG_ 2583656702 PinDutyStatus_04 1;
BA_ "SPN" SG_ 2583656702 PinDutyStatus_05 516772;
BA_ "SigType" SG_ 2583656702 PinDutyStatus_05 1;
BA_ "SPN" SG_ 2583656702 PinDutyStatus_06 516773;
BA_ "SigType" SG_ 2583656702 PinDutyStatus_06 1;
BA_ "SPN" SG_ 2583656702 PinDutyStatus_07 516774;
BA_ "SigType" SG_ 2583656702 PinDutyStatus_07 1;
BA_ "SPN" SG_ 2583656702 PinDutyStatus_08 516775;
BA_ "SigType" SG_ 2583656702 PinDutyStatus_08 1;
BA_ "SPN" SG_ 2583656446 PinFrequencyStatus_01 516776;
BA_ "SigType" SG_ 2583656446 PinFrequencyStatus_01 1;
BA_ "SPN" SG_ 2583656446 PinFrequencyStatus_02 516777;
BA_ "SigType" SG_ 2583656446 PinFrequencyStatus_02 1;
BA_ "SPN" SG_ 2583656446 PinFrequencyStatus_03 516778;
BA_ "SigType" SG_ 2583656446 PinFrequencyStatus_03 1;
BA_ "SPN" SG_ 2583656446 PinFrequencyStatus_04 516779;
BA_ "SigType" SG_ 2583656446 PinFrequencyStatus_04 1;
BA_ "SPN" SG_ 2583646462 PinFrequencyStatus_05 516780;
BA_ "SigType" SG_ 2583646462 PinFrequencyStatus_05 1;
BA_ "SPN" SG_ 2583646462 PinFrequencyStatus_06 516781;
BA_ "SigType" SG_ 2583646462 PinFrequencyStatus_06 1;
BA_ "SPN" SG_ 2583646462 PinFrequencyStatus_07 516782;
BA_ "SigType" SG_ 2583646462 PinFrequencyStatus_07 1;
BA_ "SPN" SG_ 2583646462 PinFrequencyStatus_08 516783;
BA_ "SigType" SG_ 2583646462 PinFrequencyStatus_08 1;
BA_ "SPN" SG_ 2583656190 BridgeModeStatus_b01 516784;
BA_ "SPN" SG_ 2583656190 BridgeStatus_b01 516785;
BA_ "SPN" SG_ 2583656190 BridgeModeStatus_b02 516786;
BA_ "SPN" SG_ 2583656190 BridgeStatus_b02 516787;
BA_ "SPN" SG_ 2583656190 BridgeModeStatus_b03 516788;
BA_ "SPN" SG_ 2583656190 BridgeStatus_b03 516789;
BA_ "SPN" SG_ 2583656190 BridgeModeStatus_b04 516790;
BA_ "SPN" SG_ 2583656190 BridgeStatus_b04 516791;
BA_ "SPN" SG_ 2583656190 BridgeModeStatus_b05 516792;
BA_ "SPN" SG_ 2583656190 BridgeStatus_b05 516793;
BA_ "SPN" SG_ 2583656190 BridgeModeStatus_b06 516794;
BA_ "SPN" SG_ 2583656190 BridgeStatus_b06 516795;
BA_ "SPN" SG_ 2583656190 BridgeModeStatus_b07 516796;
BA_ "SPN" SG_ 2583656190 BridgeStatus_b07 516797;
BA_ "SPN" SG_ 2583656190 BridgeModeStatus_b08 516798;
BA_ "SPN" SG_ 2583656190 BridgeStatus_b08 516799;
BA_ "GenSigStartValue" SG_ 2583647742 CurrentStatus_01 32000;
BA_ "SPN" SG_ 2583647742 CurrentStatus_01 516900;
BA_ "SigType" SG_ 2583647742 CurrentStatus_01 1;
BA_ "GenSigStartValue" SG_ 2583647742 CurrentStatus_02 32000;
BA_ "SPN" SG_ 2583647742 CurrentStatus_02 516901;
BA_ "SigType" SG_ 2583647742 CurrentStatus_02 1;
BA_ "GenSigStartValue" SG_ 2583647742 CurrentStatus_03 32000;
BA_ "SPN" SG_ 2583647742 CurrentStatus_03 516902;
BA_ "SigType" SG_ 2583647742 CurrentStatus_03 1;
BA_ "GenSigStartValue" SG_ 2583647742 CurrentStatus_04 32000;
BA_ "SPN" SG_ 2583647742 CurrentStatus_04 516903;
BA_ "SigType" SG_ 2583647742 CurrentStatus_04 1;
BA_ "GenSigStartValue" SG_ 2583647998 CurrentStatus_05 32000;
BA_ "SPN" SG_ 2583647998 CurrentStatus_05 516904;
BA_ "SigType" SG_ 2583647998 CurrentStatus_05 1;
BA_ "GenSigStartValue" SG_ 2583647998 CurrentStatus_06 32000;
BA_ "SPN" SG_ 2583647998 CurrentStatus_06 516905;
BA_ "SigType" SG_ 2583647998 CurrentStatus_06 1;
BA_ "GenSigStartValue" SG_ 2583647998 CurrentStatus_07 32000;
BA_ "SPN" SG_ 2583647998 CurrentStatus_07 516906;
BA_ "SigType" SG_ 2583647998 CurrentStatus_07 1;
BA_ "GenSigStartValue" SG_ 2583647998 CurrentStatus_08 32000;
BA_ "SPN" SG_ 2583647998 CurrentStatus_08 516907;
BA_ "SigType" SG_ 2583647998 CurrentStatus_08 1;
BA_ "GenSigStartValue" SG_ 2583648254 CurrentStatus_09 32000;
BA_ "SPN" SG_ 2583648254 CurrentStatus_09 516908;
BA_ "SigType" SG_ 2583648254 CurrentStatus_09 1;
BA_ "GenSigStartValue" SG_ 2583648254 CurrentStatus_10 32000;
BA_ "SPN" SG_ 2583648254 CurrentStatus_10 516909;
BA_ "SigType" SG_ 2583648254 CurrentStatus_10 1;
BA_ "GenSigStartValue" SG_ 2583648254 CurrentStatus_11 32000;
BA_ "SPN" SG_ 2583648254 CurrentStatus_11 516910;
BA_ "SigType" SG_ 2583648254 CurrentStatus_11 1;
BA_ "GenSigStartValue" SG_ 2583648254 CurrentStatus_12 32000;
BA_ "SPN" SG_ 2583648254 CurrentStatus_12 516911;
BA_ "SigType" SG_ 2583648254 CurrentStatus_12 1;
BA_ "GenSigStartValue" SG_ 2583648510 CurrentStatus_13 32000;
BA_ "SPN" SG_ 2583648510 CurrentStatus_13 516912;
BA_ "SigType" SG_ 2583648510 CurrentStatus_13 1;
BA_ "GenSigStartValue" SG_ 2583648510 CurrentStatus_14 32000;
BA_ "SPN" SG_ 2583648510 CurrentStatus_14 516913;
BA_ "SigType" SG_ 2583648510 CurrentStatus_14 1;
BA_ "GenSigStartValue" SG_ 2583648510 CurrentStatus_15 32000;
BA_ "SPN" SG_ 2583648510 CurrentStatus_15 516914;
BA_ "SigType" SG_ 2583648510 CurrentStatus_15 1;
BA_ "GenSigStartValue" SG_ 2583648510 CurrentStatus_16 32000;
BA_ "SPN" SG_ 2583648510 CurrentStatus_16 516915;
BA_ "SigType" SG_ 2583648510 CurrentStatus_16 1;
BA_ "GenSigStartValue" SG_ 2583655166 CurrentStatus_17 32000;
BA_ "SPN" SG_ 2583655166 CurrentStatus_17 516916;
BA_ "SigType" SG_ 2583655166 CurrentStatus_17 1;
BA_ "GenSigStartValue" SG_ 2583655166 CurrentStatus_18 32000;
BA_ "SPN" SG_ 2583655166 CurrentStatus_18 516917;
BA_ "SigType" SG_ 2583655166 CurrentStatus_18 1;
BA_ "GenSigStartValue" SG_ 2583655166 CurrentStatus_19 32000;
BA_ "SPN" SG_ 2583655166 CurrentStatus_19 516918;
BA_ "SigType" SG_ 2583655166 CurrentStatus_19 1;
BA_ "GenSigStartValue" SG_ 2583655166 CurrentStatus_20 32000;
BA_ "SPN" SG_ 2583655166 CurrentStatus_20 516919;
BA_ "SigType" SG_ 2583655166 CurrentStatus_20 1;
BA_ "GenSigStartValue" SG_ 2583655422 CurrentStatus_21 32000;
BA_ "SPN" SG_ 2583655422 CurrentStatus_21 516920;
BA_ "SigType" SG_ 2583655422 CurrentStatus_21 1;
BA_ "GenSigStartValue" SG_ 2583655422 CurrentStatus_22 32000;
BA_ "SPN" SG_ 2583655422 CurrentStatus_22 516921;
BA_ "SigType" SG_ 2583655422 CurrentStatus_22 1;
BA_ "GenSigStartValue" SG_ 2583655422 CurrentStatus_23 32000;
BA_ "SPN" SG_ 2583655422 CurrentStatus_23 516922;
BA_ "SigType" SG_ 2583655422 CurrentStatus_23 1;
BA_ "GenSigStartValue" SG_ 2583655422 CurrentStatus_24 32000;
BA_ "SPN" SG_ 2583655422 CurrentStatus_24 516923;
BA_ "SigType" SG_ 2583655422 CurrentStatus_24 1;
BA_ "GenSigStartValue" SG_ 2583655678 CurrentStatus_25 32000;
BA_ "SPN" SG_ 2583655678 CurrentStatus_25 516924;
BA_ "SigType" SG_ 2583655678 CurrentStatus_25 1;
BA_ "GenSigStartValue" SG_ 2583655678 CurrentStatus_26 32000;
BA_ "SPN" SG_ 2583655678 CurrentStatus_26 516925;
BA_ "SigType" SG_ 2583655678 CurrentStatus_26 1;
BA_ "GenSigStartValue" SG_ 2583655678 CurrentStatus_27 32000;
BA_ "SPN" SG_ 2583655678 CurrentStatus_27 516926;
BA_ "SigType" SG_ 2583655678 CurrentStatus_27 1;
BA_ "GenSigStartValue" SG_ 2583655678 CurrentStatus_28 32000;
BA_ "SPN" SG_ 2583655678 CurrentStatus_28 516927;
BA_ "SigType" SG_ 2583655678 CurrentStatus_28 1;
BA_ "GenSigStartValue" SG_ 2583655934 CurrentStatus_29 32000;
BA_ "SPN" SG_ 2583655934 CurrentStatus_29 516928;
BA_ "SigType" SG_ 2583655934 CurrentStatus_29 1;
BA_ "GenSigStartValue" SG_ 2583655934 CurrentStatus_30 32000;
BA_ "SPN" SG_ 2583655934 CurrentStatus_30 516929;
BA_ "SigType" SG_ 2583655934 CurrentStatus_30 1;
BA_ "GenSigStartValue" SG_ 2583655934 CurrentStatus_31 32000;
BA_ "SPN" SG_ 2583655934 CurrentStatus_31 516930;
BA_ "SigType" SG_ 2583655934 CurrentStatus_31 1;
BA_ "GenSigStartValue" SG_ 2583655934 CurrentStatus_32 32000;
BA_ "SPN" SG_ 2583655934 CurrentStatus_32 516931;
BA_ "SigType" SG_ 2583655934 CurrentStatus_32 1;
BA_ "GenSigStartValue" SG_ 2582845950 CurrentStatus_01 32000;
BA_ "SPN" SG_ 2582845950 CurrentStatus_01 516900;
BA_ "SigType" SG_ 2582845950 CurrentStatus_01 1;
BA_ "GenSigStartValue" SG_ 2582845950 CurrentStatus_02 32000;
BA_ "SPN" SG_ 2582845950 CurrentStatus_02 516901;
BA_ "SigType" SG_ 2582845950 CurrentStatus_02 1;
BA_ "GenSigStartValue" SG_ 2582845950 CurrentStatus_03 32000;
BA_ "SPN" SG_ 2582845950 CurrentStatus_03 516902;
BA_ "SigType" SG_ 2582845950 CurrentStatus_03 1;
BA_ "GenSigStartValue" SG_ 2582845950 CurrentStatus_04 32000;
BA_ "SPN" SG_ 2582845950 CurrentStatus_04 516903;
BA_ "SigType" SG_ 2582845950 CurrentStatus_04 1;
BA_ "GenSigStartValue" SG_ 2582845950 CurrentStatus_05 32000;
BA_ "SPN" SG_ 2582845950 CurrentStatus_05 516904;
BA_ "SigType" SG_ 2582845950 CurrentStatus_05 1;
BA_ "GenSigStartValue" SG_ 2582845950 CurrentStatus_06 32000;
BA_ "SPN" SG_ 2582845950 CurrentStatus_06 516905;
BA_ "SigType" SG_ 2582845950 CurrentStatus_06 1;
BA_ "GenSigStartValue" SG_ 2582845950 CurrentStatus_07 32000;
BA_ "SPN" SG_ 2582845950 CurrentStatus_07 516906;
BA_ "SigType" SG_ 2582845950 CurrentStatus_07 1;
BA_ "GenSigStartValue" SG_ 2582845950 CurrentStatus_08 32000;
BA_ "SPN" SG_ 2582845950 CurrentStatus_08 516907;
BA_ "SigType" SG_ 2582845950 CurrentStatus_08 1;
BA_ "GenSigStartValue" SG_ 2582845950 CurrentStatus_09 32000;
BA_ "SPN" SG_ 2582845950 CurrentStatus_09 516908;
BA_ "SigType" SG_ 2582845950 CurrentStatus_09 1;
BA_ "GenSigStartValue" SG_ 2582845950 CurrentStatus_10 32000;
BA_ "SPN" SG_ 2582845950 CurrentStatus_10 516909;
BA_ "SigType" SG_ 2582845950 CurrentStatus_10 1;
BA_ "GenSigStartValue" SG_ 2582845950 CurrentStatus_11 32000;
BA_ "SPN" SG_ 2582845950 CurrentStatus_11 516910;
BA_ "SigType" SG_ 2582845950 CurrentStatus_11 1;
BA_ "GenSigStartValue" SG_ 2582845950 CurrentStatus_12 32000;
BA_ "SPN" SG_ 2582845950 CurrentStatus_12 516911;
BA_ "SigType" SG_ 2582845950 CurrentStatus_12 1;
BA_ "GenSigStartValue" SG_ 2582845950 CurrentStatus_13 32000;
BA_ "SPN" SG_ 2582845950 CurrentStatus_13 516912;
BA_ "SigType" SG_ 2582845950 CurrentStatus_13 1;
BA_ "GenSigStartValue" SG_ 2582845950 CurrentStatus_14 32000;
BA_ "SPN" SG_ 2582845950 CurrentStatus_14 516913;
BA_ "SigType" SG_ 2582845950 CurrentStatus_14 1;
BA_ "GenSigStartValue" SG_ 2582845950 CurrentStatus_15 32000;
BA_ "SPN" SG_ 2582845950 CurrentStatus_15 516914;
BA_ "SigType" SG_ 2582845950 CurrentStatus_15 1;
BA_ "GenSigStartValue" SG_ 2582845950 CurrentStatus_16 32000;
BA_ "SPN" SG_ 2582845950 CurrentStatus_16 516915;
BA_ "SigType" SG_ 2582845950 CurrentStatus_16 1;
BA_ "GenSigStartValue" SG_ 2582845950 CurrentStatus_17 32000;
BA_ "SPN" SG_ 2582845950 CurrentStatus_17 516916;
BA_ "SigType" SG_ 2582845950 CurrentStatus_17 1;
BA_ "GenSigStartValue" SG_ 2582845950 CurrentStatus_18 32000;
BA_ "SPN" SG_ 2582845950 CurrentStatus_18 516917;
BA_ "SigType" SG_ 2582845950 CurrentStatus_18 1;
BA_ "GenSigStartValue" SG_ 2582845950 CurrentStatus_19 32000;
BA_ "SPN" SG_ 2582845950 CurrentStatus_19 516918;
BA_ "SigType" SG_ 2582845950 CurrentStatus_19 1;
BA_ "GenSigStartValue" SG_ 2582845950 CurrentStatus_20 32000;
BA_ "SPN" SG_ 2582845950 CurrentStatus_20 516919;
BA_ "SigType" SG_ 2582845950 CurrentStatus_20 1;
BA_ "GenSigStartValue" SG_ 2582845950 CurrentStatus_21 32000;
BA_ "SPN" SG_ 2582845950 CurrentStatus_21 516920;
BA_ "SigType" SG_ 2582845950 CurrentStatus_21 1;
BA_ "GenSigStartValue" SG_ 2582845950 CurrentStatus_22 32000;
BA_ "SPN" SG_ 2582845950 CurrentStatus_22 516921;
BA_ "SigType" SG_ 2582845950 CurrentStatus_22 1;
BA_ "GenSigStartValue" SG_ 2582845950 CurrentStatus_23 32000;
BA_ "SPN" SG_ 2582845950 CurrentStatus_23 516922;
BA_ "SigType" SG_ 2582845950 CurrentStatus_23 1;
BA_ "GenSigStartValue" SG_ 2582845950 CurrentStatus_24 32000;
BA_ "SPN" SG_ 2582845950 CurrentStatus_24 516923;
BA_ "SigType" SG_ 2582845950 CurrentStatus_24 1;
BA_ "GenSigStartValue" SG_ 2582845950 CurrentStatus_25 32000;
BA_ "SPN" SG_ 2582845950 CurrentStatus_25 516924;
BA_ "SigType" SG_ 2582845950 CurrentStatus_25 1;
BA_ "GenSigStartValue" SG_ 2582845950 CurrentStatus_26 32000;
BA_ "SPN" SG_ 2582845950 CurrentStatus_26 516925;
BA_ "SigType" SG_ 2582845950 CurrentStatus_26 1;
BA_ "GenSigStartValue" SG_ 2582845950 CurrentStatus_27 32000;
BA_ "SPN" SG_ 2582845950 CurrentStatus_27 516926;
BA_ "SigType" SG_ 2582845950 CurrentStatus_27 1;
BA_ "GenSigStartValue" SG_ 2582845950 CurrentStatus_28 32000;
BA_ "SPN" SG_ 2582845950 CurrentStatus_28 516927;
BA_ "SigType" SG_ 2582845950 CurrentStatus_28 1;
BA_ "GenSigStartValue" SG_ 2582845950 CurrentStatus_29 32000;
BA_ "SPN" SG_ 2582845950 CurrentStatus_29 516928;
BA_ "SigType" SG_ 2582845950 CurrentStatus_29 1;
BA_ "GenSigStartValue" SG_ 2582845950 CurrentStatus_30 32000;
BA_ "SPN" SG_ 2582845950 CurrentStatus_30 516929;
BA_ "SigType" SG_ 2582845950 CurrentStatus_30 1;
BA_ "GenSigStartValue" SG_ 2582845950 CurrentStatus_31 32000;
BA_ "SPN" SG_ 2582845950 CurrentStatus_31 516930;
BA_ "SigType" SG_ 2582845950 CurrentStatus_31 1;
BA_ "GenSigStartValue" SG_ 2582845950 CurrentStatus_32 32000;
BA_ "SPN" SG_ 2582845950 CurrentStatus_32 516931;
BA_ "SigType" SG_ 2582845950 CurrentStatus_32 1;
BA_ "SPN" SG_ 2583648766 DiagnosticStatus_01 516932;
BA_ "SigType" SG_ 2583648766 DiagnosticStatus_01 4;
BA_ "SPN" SG_ 2583648766 DiagnosticStatus_02 516933;
BA_ "SPN" SG_ 2583648766 DiagnosticStatus_03 516934;
BA_ "SPN" SG_ 2583648766 DiagnosticStatus_04 516935;
BA_ "SPN" SG_ 2583648766 DiagnosticStatus_05 516936;
BA_ "SPN" SG_ 2583648766 DiagnosticStatus_06 516937;
BA_ "SPN" SG_ 2583648766 DiagnosticStatus_07 516938;
BA_ "SPN" SG_ 2583648766 DiagnosticStatus_08 516939;
BA_ "SPN" SG_ 2583648766 DiagnosticStatus_09 516940;
BA_ "SPN" SG_ 2583648766 DiagnosticStatus_10 516941;
BA_ "SPN" SG_ 2583648766 DiagnosticStatus_11 516942;
BA_ "SPN" SG_ 2583648766 DiagnosticStatus_12 516943;
BA_ "SPN" SG_ 2583648766 DiagnosticStatus_13 516944;
BA_ "SPN" SG_ 2583648766 DiagnosticStatus_14 516945;
BA_ "SPN" SG_ 2583648766 DiagnosticStatus_15 516946;
BA_ "SPN" SG_ 2583648766 DiagnosticStatus_16 516947;
BA_ "SPN" SG_ 2583649022 DiagnosticStatus_17 516948;
BA_ "SPN" SG_ 2583649022 DiagnosticStatus_18 516949;
BA_ "SPN" SG_ 2583649022 DiagnosticStatus_19 516950;
BA_ "SPN" SG_ 2583649022 DiagnosticStatus_20 516951;
BA_ "SPN" SG_ 2583649022 DiagnosticStatus_21 516952;
BA_ "SPN" SG_ 2583649022 DiagnosticStatus_22 516953;
BA_ "SPN" SG_ 2583649022 DiagnosticStatus_23 516954;
BA_ "SPN" SG_ 2583649022 DiagnosticStatus_24 516955;
BA_ "SPN" SG_ 2583649022 DiagnosticStatus_25 516956;
BA_ "SPN" SG_ 2583649022 DiagnosticStatus_26 516957;
BA_ "SPN" SG_ 2583649022 DiagnosticStatus_27 516958;
BA_ "SPN" SG_ 2583649022 DiagnosticStatus_28 516959;
BA_ "SPN" SG_ 2583649022 DiagnosticStatus_29 516960;
BA_ "SPN" SG_ 2583649022 DiagnosticStatus_30 516961;
BA_ "SPN" SG_ 2583649022 DiagnosticStatus_31 516962;
BA_ "SPN" SG_ 2583649022 DiagnosticStatus_32 516963;
BA_ "SPN" SG_ 2582847486 DiagnosticStatus_01 516932;
BA_ "SigType" SG_ 2582847486 DiagnosticStatus_01 4;
BA_ "SPN" SG_ 2582847486 DiagnosticStatus_02 516933;
BA_ "SPN" SG_ 2582847486 DiagnosticStatus_03 516934;
BA_ "SPN" SG_ 2582847486 DiagnosticStatus_04 516935;
BA_ "SPN" SG_ 2582847486 DiagnosticStatus_05 516936;
BA_ "SPN" SG_ 2582847486 DiagnosticStatus_06 516937;
BA_ "SPN" SG_ 2582847486 DiagnosticStatus_07 516938;
BA_ "SPN" SG_ 2582847486 DiagnosticStatus_08 516939;
BA_ "SPN" SG_ 2582847486 DiagnosticStatus_09 516940;
BA_ "SPN" SG_ 2582847486 DiagnosticStatus_10 516941;
BA_ "SPN" SG_ 2582847486 DiagnosticStatus_11 516942;
BA_ "SPN" SG_ 2582847486 DiagnosticStatus_12 516943;
BA_ "SPN" SG_ 2582847486 DiagnosticStatus_13 516944;
BA_ "SPN" SG_ 2582847486 DiagnosticStatus_14 516945;
BA_ "SPN" SG_ 2582847486 DiagnosticStatus_15 516946;
BA_ "SPN" SG_ 2582847486 DiagnosticStatus_16 516947;
BA_ "SPN" SG_ 2582847486 DiagnosticStatus_17 516948;
BA_ "SPN" SG_ 2582847486 DiagnosticStatus_18 516949;
BA_ "SPN" SG_ 2582847486 DiagnosticStatus_19 516950;
BA_ "SPN" SG_ 2582847486 DiagnosticStatus_20 516951;
BA_ "SPN" SG_ 2582847486 DiagnosticStatus_21 516952;
BA_ "SPN" SG_ 2582847486 DiagnosticStatus_22 516953;
BA_ "SPN" SG_ 2582847486 DiagnosticStatus_23 516954;
BA_ "SPN" SG_ 2582847486 DiagnosticStatus_24 516955;
BA_ "SPN" SG_ 2582847486 DiagnosticStatus_25 516956;
BA_ "SPN" SG_ 2582847486 DiagnosticStatus_26 516957;
BA_ "SPN" SG_ 2582847486 DiagnosticStatus_27 516958;
BA_ "SPN" SG_ 2582847486 DiagnosticStatus_28 516959;
BA_ "SPN" SG_ 2582847486 DiagnosticStatus_29 516960;
BA_ "SPN" SG_ 2582847486 DiagnosticStatus_30 516961;
BA_ "SPN" SG_ 2582847486 DiagnosticStatus_31 516962;
BA_ "SPN" SG_ 2582847486 DiagnosticStatus_32 516963;
BA_ "SPN" SG_ 2583651326 DutyStatus_01 516964;
BA_ "SigType" SG_ 2583651326 DutyStatus_01 1;
BA_ "SPN" SG_ 2583651326 DutyStatus_02 516965;
BA_ "SigType" SG_ 2583651326 DutyStatus_02 1;
BA_ "SPN" SG_ 2583651326 DutyStatus_03 516966;
BA_ "SigType" SG_ 2583651326 DutyStatus_03 1;
BA_ "SPN" SG_ 2583651326 DutyStatus_04 516967;
BA_ "SigType" SG_ 2583651326 DutyStatus_04 1;
BA_ "SPN" SG_ 2583651326 DutyStatus_05 516968;
BA_ "SigType" SG_ 2583651326 DutyStatus_05 1;
BA_ "SPN" SG_ 2583651326 DutyStatus_06 516969;
BA_ "SigType" SG_ 2583651326 DutyStatus_06 1;
BA_ "SPN" SG_ 2583651326 DutyStatus_07 516970;
BA_ "SigType" SG_ 2583651326 DutyStatus_07 1;
BA_ "SPN" SG_ 2583651326 DutyStatus_08 516971;
BA_ "SigType" SG_ 2583651326 DutyStatus_08 1;
BA_ "SPN" SG_ 2583651582 DutyStatus_09 516972;
BA_ "SigType" SG_ 2583651582 DutyStatus_09 1;
BA_ "SPN" SG_ 2583651582 DutyStatus_10 516973;
BA_ "SigType" SG_ 2583651582 DutyStatus_10 1;
BA_ "SPN" SG_ 2583651582 DutyStatus_11 516974;
BA_ "SigType" SG_ 2583651582 DutyStatus_11 1;
BA_ "SPN" SG_ 2583651582 DutyStatus_12 516975;
BA_ "SigType" SG_ 2583651582 DutyStatus_12 1;
BA_ "SPN" SG_ 2583651582 DutyStatus_13 516976;
BA_ "SigType" SG_ 2583651582 DutyStatus_13 1;
BA_ "SPN" SG_ 2583651582 DutyStatus_14 516977;
BA_ "SigType" SG_ 2583651582 DutyStatus_14 1;
BA_ "SPN" SG_ 2583651582 DutyStatus_15 516978;
BA_ "SigType" SG_ 2583651582 DutyStatus_15 1;
BA_ "SPN" SG_ 2583651582 DutyStatus_16 516979;
BA_ "SigType" SG_ 2583651582 DutyStatus_16 1;
BA_ "SPN" SG_ 2583651838 DutyStatus_17 516980;
BA_ "SigType" SG_ 2583651838 DutyStatus_17 1;
BA_ "SPN" SG_ 2583651838 DutyStatus_18 516981;
BA_ "SigType" SG_ 2583651838 DutyStatus_18 1;
BA_ "SPN" SG_ 2583651838 DutyStatus_19 516982;
BA_ "SigType" SG_ 2583651838 DutyStatus_19 1;
BA_ "SPN" SG_ 2583651838 DutyStatus_20 516983;
BA_ "SigType" SG_ 2583651838 DutyStatus_20 1;
BA_ "SPN" SG_ 2583651838 DutyStatus_21 516984;
BA_ "SigType" SG_ 2583651838 DutyStatus_21 1;
BA_ "SPN" SG_ 2583651838 DutyStatus_22 516985;
BA_ "SigType" SG_ 2583651838 DutyStatus_22 1;
BA_ "SPN" SG_ 2583651838 DutyStatus_23 516986;
BA_ "SigType" SG_ 2583651838 DutyStatus_23 1;
BA_ "SPN" SG_ 2583651838 DutyStatus_24 516987;
BA_ "SigType" SG_ 2583651838 DutyStatus_24 1;
BA_ "SPN" SG_ 2583652094 DutyStatus_25 516988;
BA_ "SigType" SG_ 2583652094 DutyStatus_25 1;
BA_ "SPN" SG_ 2583652094 DutyStatus_26 516989;
BA_ "SigType" SG_ 2583652094 DutyStatus_26 1;
BA_ "SPN" SG_ 2583652094 DutyStatus_27 516990;
BA_ "SigType" SG_ 2583652094 DutyStatus_27 1;
BA_ "SPN" SG_ 2583652094 DutyStatus_28 516991;
BA_ "SigType" SG_ 2583652094 DutyStatus_28 1;
BA_ "SPN" SG_ 2583652094 DutyStatus_29 516992;
BA_ "SigType" SG_ 2583652094 DutyStatus_29 1;
BA_ "SPN" SG_ 2583652094 DutyStatus_30 516993;
BA_ "SigType" SG_ 2583652094 DutyStatus_30 1;
BA_ "SPN" SG_ 2583652094 DutyStatus_31 516994;
BA_ "SigType" SG_ 2583652094 DutyStatus_31 1;
BA_ "SPN" SG_ 2583652094 DutyStatus_32 516995;
BA_ "SigType" SG_ 2583652094 DutyStatus_32 1;
BA_ "SPN" SG_ 2582847742 DutyStatus_01 516964;
BA_ "SigType" SG_ 2582847742 DutyStatus_01 1;
BA_ "SPN" SG_ 2582847742 DutyStatus_02 516965;
BA_ "SigType" SG_ 2582847742 DutyStatus_02 1;
BA_ "SPN" SG_ 2582847742 DutyStatus_03 516966;
BA_ "SigType" SG_ 2582847742 DutyStatus_03 1;
BA_ "SPN" SG_ 2582847742 DutyStatus_04 516967;
BA_ "SigType" SG_ 2582847742 DutyStatus_04 1;
BA_ "SPN" SG_ 2582847742 DutyStatus_05 516968;
BA_ "SigType" SG_ 2582847742 DutyStatus_05 1;
BA_ "SPN" SG_ 2582847742 DutyStatus_06 516969;
BA_ "SigType" SG_ 2582847742 DutyStatus_06 1;
BA_ "SPN" SG_ 2582847742 DutyStatus_07 516970;
BA_ "SigType" SG_ 2582847742 DutyStatus_07 1;
BA_ "SPN" SG_ 2582847742 DutyStatus_08 516971;
BA_ "SigType" SG_ 2582847742 DutyStatus_08 1;
BA_ "SPN" SG_ 2582847742 DutyStatus_09 516972;
BA_ "SigType" SG_ 2582847742 DutyStatus_09 1;
BA_ "SPN" SG_ 2582847742 DutyStatus_10 516973;
BA_ "SigType" SG_ 2582847742 DutyStatus_10 1;
BA_ "SPN" SG_ 2582847742 DutyStatus_11 516974;
BA_ "SigType" SG_ 2582847742 DutyStatus_11 1;
BA_ "SPN" SG_ 2582847742 DutyStatus_12 516975;
BA_ "SigType" SG_ 2582847742 DutyStatus_12 1;
BA_ "SPN" SG_ 2582847742 DutyStatus_13 516976;
BA_ "SigType" SG_ 2582847742 DutyStatus_13 1;
BA_ "SPN" SG_ 2582847742 DutyStatus_14 516977;
BA_ "SigType" SG_ 2582847742 DutyStatus_14 1;
BA_ "SPN" SG_ 2582847742 DutyStatus_15 516978;
BA_ "SigType" SG_ 2582847742 DutyStatus_15 1;
BA_ "SPN" SG_ 2582847742 DutyStatus_16 516979;
BA_ "SigType" SG_ 2582847742 DutyStatus_16 1;
BA_ "SPN" SG_ 2582847742 DutyStatus_17 516980;
BA_ "SigType" SG_ 2582847742 DutyStatus_17 1;
BA_ "SPN" SG_ 2582847742 DutyStatus_18 516981;
BA_ "SigType" SG_ 2582847742 DutyStatus_18 1;
BA_ "SPN" SG_ 2582847742 DutyStatus_19 516982;
BA_ "SigType" SG_ 2582847742 DutyStatus_19 1;
BA_ "SPN" SG_ 2582847742 DutyStatus_20 516983;
BA_ "SigType" SG_ 2582847742 DutyStatus_20 1;
BA_ "SPN" SG_ 2582847742 DutyStatus_21 516984;
BA_ "SigType" SG_ 2582847742 DutyStatus_21 1;
BA_ "SPN" SG_ 2582847742 DutyStatus_22 516985;
BA_ "SigType" SG_ 2582847742 DutyStatus_22 1;
BA_ "SPN" SG_ 2582847742 DutyStatus_23 516986;
BA_ "SigType" SG_ 2582847742 DutyStatus_23 1;
BA_ "SPN" SG_ 2582847742 DutyStatus_24 516987;
BA_ "SigType" SG_ 2582847742 DutyStatus_24 1;
BA_ "SPN" SG_ 2582847742 DutyStatus_25 516988;
BA_ "SigType" SG_ 2582847742 DutyStatus_25 1;
BA_ "SPN" SG_ 2582847742 DutyStatus_26 516989;
BA_ "SigType" SG_ 2582847742 DutyStatus_26 1;
BA_ "SPN" SG_ 2582847742 DutyStatus_27 516990;
BA_ "SigType" SG_ 2582847742 DutyStatus_27 1;
BA_ "SPN" SG_ 2582847742 DutyStatus_28 516991;
BA_ "SigType" SG_ 2582847742 DutyStatus_28 1;
BA_ "SPN" SG_ 2582847742 DutyStatus_29 516992;
BA_ "SigType" SG_ 2582847742 DutyStatus_29 1;
BA_ "SPN" SG_ 2582847742 DutyStatus_30 516993;
BA_ "SigType" SG_ 2582847742 DutyStatus_30 1;
BA_ "SPN" SG_ 2582847742 DutyStatus_31 516994;
BA_ "SigType" SG_ 2582847742 DutyStatus_31 1;
BA_ "SPN" SG_ 2582847742 DutyStatus_32 516995;
BA_ "SigType" SG_ 2582847742 DutyStatus_32 1;
BA_ "SPN" SG_ 2582843646 FaultCountStatus_01 516996;
BA_ "SigType" SG_ 2582843646 FaultCountStatus_01 1;
BA_ "SPN" SG_ 2582843646 FaultCountStatus_02 516997;
BA_ "SigType" SG_ 2582843646 FaultCountStatus_02 1;
BA_ "SPN" SG_ 2582843646 FaultCountStatus_03 516998;
BA_ "SigType" SG_ 2582843646 FaultCountStatus_03 1;
BA_ "SPN" SG_ 2582843646 FaultCountStatus_04 516999;
BA_ "SigType" SG_ 2582843646 FaultCountStatus_04 1;
BA_ "SPN" SG_ 2582843902 FaultCountStatus_05 519000;
BA_ "SigType" SG_ 2582843902 FaultCountStatus_05 1;
BA_ "SPN" SG_ 2582843902 FaultCountStatus_06 519001;
BA_ "SigType" SG_ 2582843902 FaultCountStatus_06 1;
BA_ "SPN" SG_ 2582843902 FaultCountStatus_07 519002;
BA_ "SigType" SG_ 2582843902 FaultCountStatus_07 1;
BA_ "SPN" SG_ 2582843902 FaultCountStatus_08 519003;
BA_ "SigType" SG_ 2582843902 FaultCountStatus_08 1;
BA_ "SPN" SG_ 2582844158 FaultCountStatus_09 519004;
BA_ "SigType" SG_ 2582844158 FaultCountStatus_09 1;
BA_ "SPN" SG_ 2582844158 FaultCountStatus_10 519005;
BA_ "SigType" SG_ 2582844158 FaultCountStatus_10 1;
BA_ "SPN" SG_ 2582844158 FaultCountStatus_11 519006;
BA_ "SigType" SG_ 2582844158 FaultCountStatus_11 1;
BA_ "SPN" SG_ 2582844158 FaultCountStatus_12 519007;
BA_ "SigType" SG_ 2582844158 FaultCountStatus_12 1;
BA_ "SPN" SG_ 2582844414 FaultCountStatus_13 519008;
BA_ "SigType" SG_ 2582844414 FaultCountStatus_13 1;
BA_ "SPN" SG_ 2582844414 FaultCountStatus_14 519009;
BA_ "SigType" SG_ 2582844414 FaultCountStatus_14 1;
BA_ "SPN" SG_ 2582844414 FaultCountStatus_15 519010;
BA_ "SigType" SG_ 2582844414 FaultCountStatus_15 1;
BA_ "SPN" SG_ 2582844414 FaultCountStatus_16 519011;
BA_ "SigType" SG_ 2582844414 FaultCountStatus_16 1;
BA_ "SPN" SG_ 2582844670 FaultCountStatus_17 519012;
BA_ "SigType" SG_ 2582844670 FaultCountStatus_17 1;
BA_ "SPN" SG_ 2582844670 FaultCountStatus_18 519013;
BA_ "SigType" SG_ 2582844670 FaultCountStatus_18 1;
BA_ "SPN" SG_ 2582844670 FaultCountStatus_19 519014;
BA_ "SigType" SG_ 2582844670 FaultCountStatus_19 1;
BA_ "SPN" SG_ 2582844670 FaultCountStatus_20 519015;
BA_ "SigType" SG_ 2582844670 FaultCountStatus_20 1;
BA_ "SPN" SG_ 2582844926 FaultCountStatus_21 519016;
BA_ "SigType" SG_ 2582844926 FaultCountStatus_21 1;
BA_ "SPN" SG_ 2582844926 FaultCountStatus_22 519017;
BA_ "SigType" SG_ 2582844926 FaultCountStatus_22 1;
BA_ "SPN" SG_ 2582844926 FaultCountStatus_23 519018;
BA_ "SigType" SG_ 2582844926 FaultCountStatus_23 1;
BA_ "SPN" SG_ 2582844926 FaultCountStatus_24 519019;
BA_ "SigType" SG_ 2582844926 FaultCountStatus_24 1;
BA_ "SPN" SG_ 2582845182 FaultCountStatus_25 519020;
BA_ "SigType" SG_ 2582845182 FaultCountStatus_25 1;
BA_ "SPN" SG_ 2582845182 FaultCountStatus_26 519021;
BA_ "SigType" SG_ 2582845182 FaultCountStatus_26 1;
BA_ "SPN" SG_ 2582845182 FaultCountStatus_27 519022;
BA_ "SigType" SG_ 2582845182 FaultCountStatus_27 1;
BA_ "SPN" SG_ 2582845182 FaultCountStatus_28 519023;
BA_ "SigType" SG_ 2582845182 FaultCountStatus_28 1;
BA_ "SPN" SG_ 2582845438 FaultCountStatus_29 519024;
BA_ "SigType" SG_ 2582845438 FaultCountStatus_29 1;
BA_ "SPN" SG_ 2582845438 FaultCountStatus_30 519025;
BA_ "SigType" SG_ 2582845438 FaultCountStatus_30 1;
BA_ "SPN" SG_ 2582845438 FaultCountStatus_31 519026;
BA_ "SigType" SG_ 2582845438 FaultCountStatus_31 1;
BA_ "SPN" SG_ 2582845438 FaultCountStatus_32 519027;
BA_ "SigType" SG_ 2582845438 FaultCountStatus_32 1;
VAL_ 2369322750 BridgeModeCommand_b01 0 "Freewheeling" 1 "Forward" 2 "Reverse" 3 "Brake" 6 "Error" 7 "Not Available" ;
VAL_ 2369322750 BridgeModeCommand_b02 0 "Freewheeling" 1 "Forward" 2 "Reverse" 3 "Brake" 6 "Error" 7 "Not Available" ;
VAL_ 2369322750 BridgeModeCommand_b03 0 "Freewheeling" 1 "Forward" 2 "Reverse" 3 "Brake" 6 "Error" 7 "Not Available" ;
VAL_ 2369322750 BridgeModeCommand_b04 0 "Freewheeling" 1 "Forward" 2 "Reverse" 3 "Brake" 6 "Error" 7 "Not Available" ;
VAL_ 2369322750 BridgeModeCommand_b05 0 "Freewheeling" 1 "Forward" 2 "Reverse" 3 "Brake" 6 "Error" 7 "Not Available" ;
VAL_ 2369322750 BridgeModeCommand_b06 0 "Freewheeling" 1 "Forward" 2 "Reverse" 3 "Brake" 6 "Error" 7 "Not Available" ;
VAL_ 2369322750 BridgeModeCommand_b07 0 "Freewheeling" 1 "Forward" 2 "Reverse" 3 "Brake" 6 "Error" 7 "Not Available" ;
VAL_ 2369322750 BridgeModeCommand_b08 0 "Freewheeling" 1 "Forward" 2 "Reverse" 3 "Brake" 6 "Error" 7 "Not Available" ;
VAL_ 2369388286 PinModeCommand_01 0 "Disabled" 1 "VREF" 2 "HighSide" 3 "LowSide" 4 "InputOnly" 5 "Bridge" 14 "Error" 15 "Not Available" ;
VAL_ 2369388286 PinPullModeCommand_01 0 "None" 1 "PullDown" 2 "PullUp" 3 "Not Available" ;
VAL_ 2369388286 LoadDetectionCommand_01 0 "Off" 1 "On" 2 "Error" 3 "Not Available" ;
VAL_ 2369388286 PinModeCommand_02 0 "Disabled" 1 "VREF" 2 "HighSide" 3 "LowSide" 4 "InputOnly" 5 "Bridge" 14 "Error" 15 "Not Available" ;
VAL_ 2369388286 PinPullModeCommand_02 0 "None" 1 "PullDown" 2 "PullUp" 3 "Not Available" ;
VAL_ 2369388286 LoadDetectionCommand_02 0 "Off" 1 "On" 2 "Error" 3 "Not Available" ;
VAL_ 2369388286 PinModeCommand_03 0 "Disabled" 1 "VREF" 2 "HighSide" 3 "LowSide" 4 "InputOnly" 5 "Bridge" 14 "Error" 15 "Not Available" ;
VAL_ 2369388286 PinPullModeCommand_03 0 "None" 1 "PullDown" 2 "PullUp" 3 "Not Available" ;
VAL_ 2369388286 LoadDetectionCommand_03 0 "Off" 1 "On" 2 "Error" 3 "Not Available" ;
VAL_ 2369388286 PinModeCommand_04 0 "Disabled" 1 "VREF" 2 "HighSide" 3 "LowSide" 4 "InputOnly" 5 "Bridge" 14 "Error" 15 "Not Available" ;
VAL_ 2369388286 PinPullModeCommand_04 0 "None" 1 "PullDown" 2 "PullUp" 3 "Not Available" ;
VAL_ 2369388286 LoadDetectionCommand_04 0 "Off" 1 "On" 2 "Error" 3 "Not Available" ;
VAL_ 2369388286 PinModeCommand_05 0 "Disabled" 1 "VREF" 2 "HighSide" 3 "LowSide" 4 "InputOnly" 5 "Bridge" 14 "Error" 15 "Not Available" ;
VAL_ 2369388286 PinPullModeCommand_05 0 "None" 1 "PullDown" 2 "PullUp" 3 "Not Available" ;
VAL_ 2369388286 LoadDetectionCommand_05 0 "Off" 1 "On" 2 "Error" 3 "Not Available" ;
VAL_ 2369388286 PinModeCommand_06 0 "Disabled" 1 "VREF" 2 "HighSide" 3 "LowSide" 4 "InputOnly" 5 "Bridge" 14 "Error" 15 "Not Available" ;
VAL_ 2369388286 PinPullModeCommand_06 0 "None" 1 "PullDown" 2 "PullUp" 3 "Not Available" ;
VAL_ 2369388286 LoadDetectionCommand_06 0 "Off" 1 "On" 2 "Error" 3 "Not Available" ;
VAL_ 2369388286 PinModeCommand_07 0 "Disabled" 1 "VREF" 2 "HighSide" 3 "LowSide" 4 "InputOnly" 5 "Bridge" 14 "Error" 15 "Not Available" ;
VAL_ 2369388286 PinPullModeCommand_07 0 "None" 1 "PullDown" 2 "PullUp" 3 "Not Available" ;
VAL_ 2369388286 LoadDetectionCommand_07 0 "Off" 1 "On" 2 "Error" 3 "Not Available" ;
VAL_ 2369388286 PinModeCommand_08 0 "Disabled" 1 "VREF" 2 "HighSide" 3 "LowSide" 4 "InputOnly" 5 "Bridge" 14 "Error" 15 "Not Available" ;
VAL_ 2369388286 PinPullModeCommand_08 0 "None" 1 "PullDown" 2 "PullUp" 3 "Not Available" ;
VAL_ 2369388286 LoadDetectionCommand_08 0 "Off" 1 "On" 2 "Error" 3 "Not Available" ;
VAL_ 2369453822 PinModeCommand_09 0 "Disabled" 1 "VREF" 2 "HighSide" 3 "LowSide" 4 "InputOnly" 5 "Bridge" 14 "Error" 15 "Not Available" ;
VAL_ 2369453822 PinPullModeCommand_09 0 "None" 1 "PullDown" 2 "PullUp" 3 "Not Available" ;
VAL_ 2369453822 LoadDetectionCommand_09 0 "Off" 1 "On" 2 "Error" 3 "Not Available" ;
VAL_ 2369453822 PinModeCommand_10 0 "Disabled" 1 "VREF" 2 "HighSide" 3 "LowSide" 4 "InputOnly" 5 "Bridge" 14 "Error" 15 "Not Available" ;
VAL_ 2369453822 PinPullModeCommand_10 0 "None" 1 "PullDown" 2 "PullUp" 3 "Not Available" ;
VAL_ 2369453822 LoadDetectionCommand_10 0 "Off" 1 "On" 2 "Error" 3 "Not Available" ;
VAL_ 2369453822 PinModeCommand_11 0 "Disabled" 1 "VREF" 2 "HighSide" 3 "LowSide" 4 "InputOnly" 5 "Bridge" 14 "Error" 15 "Not Available" ;
VAL_ 2369453822 PinPullModeCommand_11 0 "None" 1 "PullDown" 2 "PullUp" 3 "Not Available" ;
VAL_ 2369453822 LoadDetectionCommand_11 0 "Off" 1 "On" 2 "Error" 3 "Not Available" ;
VAL_ 2369453822 PinModeCommand_12 0 "Disabled" 1 "VREF" 2 "HighSide" 3 "LowSide" 4 "InputOnly" 5 "Bridge" 14 "Error" 15 "Not Available" ;
VAL_ 2369453822 PinPullModeCommand_12 0 "None" 1 "PullDown" 2 "PullUp" 3 "Not Available" ;
VAL_ 2369453822 LoadDetectionCommand_12 0 "Off" 1 "On" 2 "Error" 3 "Not Available" ;
VAL_ 2369453822 PinModeCommand_13 0 "Disabled" 1 "VREF" 2 "HighSide" 3 "LowSide" 4 "InputOnly" 5 "Bridge" 14 "Error" 15 "Not Available" ;
VAL_ 2369453822 PinPullModeCommand_13 0 "None" 1 "PullDown" 2 "PullUp" 3 "Not Available" ;
VAL_ 2369453822 LoadDetectionCommand_13 0 "Off" 1 "On" 2 "Error" 3 "Not Available" ;
VAL_ 2369453822 PinModeCommand_14 0 "Disabled" 1 "VREF" 2 "HighSide" 3 "LowSide" 4 "InputOnly" 5 "Bridge" 14 "Error" 15 "Not Available" ;
VAL_ 2369453822 PinPullModeCommand_14 0 "None" 1 "PullDown" 2 "PullUp" 3 "Not Available" ;
VAL_ 2369453822 LoadDetectionCommand_14 0 "Off" 1 "On" 2 "Error" 3 "Not Available" ;
VAL_ 2369453822 PinModeCommand_15 0 "Disabled" 1 "VREF" 2 "HighSide" 3 "LowSide" 4 "InputOnly" 5 "Bridge" 14 "Error" 15 "Not Available" ;
VAL_ 2369453822 PinPullModeCommand_15 0 "None" 1 "PullDown" 2 "PullUp" 3 "Not Available" ;
VAL_ 2369453822 LoadDetectionCommand_15 0 "Off" 1 "On" 2 "Error" 3 "Not Available" ;
VAL_ 2369453822 PinModeCommand_16 0 "Disabled" 1 "VREF" 2 "HighSide" 3 "LowSide" 4 "InputOnly" 5 "Bridge" 14 "Error" 15 "Not Available" ;
VAL_ 2369453822 PinPullModeCommand_16 0 "None" 1 "PullDown" 2 "PullUp" 3 "Not Available" ;
VAL_ 2369453822 LoadDetectionCommand_16 0 "Off" 1 "On" 2 "Error" 3 "Not Available" ;
VAL_ 2369519358 PinModeCommand_17 0 "Disabled" 1 "VREF" 2 "HighSide" 3 "LowSide" 4 "InputOnly" 5 "Bridge" 14 "Error" 15 "Not Available" ;
VAL_ 2369519358 PinPullModeCommand_17 0 "None" 1 "PullDown" 2 "PullUp" 3 "Not Available" ;
VAL_ 2369519358 LoadDetectionCommand_17 0 "Off" 1 "On" 2 "Error" 3 "Not Available" ;
VAL_ 2369519358 PinModeCommand_18 0 "Disabled" 1 "VREF" 2 "HighSide" 3 "LowSide" 4 "InputOnly" 5 "Bridge" 14 "Error" 15 "Not Available" ;
VAL_ 2369519358 PinPullModeCommand_18 0 "None" 1 "PullDown" 2 "PullUp" 3 "Not Available" ;
VAL_ 2369519358 LoadDetectionCommand_18 0 "Off" 1 "On" 2 "Error" 3 "Not Available" ;
VAL_ 2369519358 PinModeCommand_19 0 "Disabled" 1 "VREF" 2 "HighSide" 3 "LowSide" 4 "InputOnly" 5 "Bridge" 14 "Error" 15 "Not Available" ;
VAL_ 2369519358 PinPullModeCommand_19 0 "None" 1 "PullDown" 2 "PullUp" 3 "Not Available" ;
VAL_ 2369519358 LoadDetectionCommand_19 0 "Off" 1 "On" 2 "Error" 3 "Not Available" ;
VAL_ 2369519358 PinModeCommand_20 0 "Disabled" 1 "VREF" 2 "HighSide" 3 "LowSide" 4 "InputOnly" 5 "Bridge" 14 "Error" 15 "Not Available" ;
VAL_ 2369519358 PinPullModeCommand_20 0 "None" 1 "PullDown" 2 "PullUp" 3 "Not Available" ;
VAL_ 2369519358 LoadDetectionCommand_20 0 "Off" 1 "On" 2 "Error" 3 "Not Available" ;
VAL_ 2369519358 PinModeCommand_21 0 "Disabled" 1 "VREF" 2 "HighSide" 3 "LowSide" 4 "InputOnly" 5 "Bridge" 14 "Error" 15 "Not Available" ;
VAL_ 2369519358 PinPullModeCommand_21 0 "None" 1 "PullDown" 2 "PullUp" 3 "Not Available" ;
VAL_ 2369519358 LoadDetectionCommand_21 0 "Off" 1 "On" 2 "Error" 3 "Not Available" ;
VAL_ 2369519358 PinModeCommand_22 0 "Disabled" 1 "VREF" 2 "HighSide" 3 "LowSide" 4 "InputOnly" 5 "Bridge" 14 "Error" 15 "Not Available" ;
VAL_ 2369519358 PinPullModeCommand_22 0 "None" 1 "PullDown" 2 "PullUp" 3 "Not Available" ;
VAL_ 2369519358 LoadDetectionCommand_22 0 "Off" 1 "On" 2 "Error" 3 "Not Available" ;
VAL_ 2369519358 PinModeCommand_23 0 "Disabled" 1 "VREF" 2 "HighSide" 3 "LowSide" 4 "InputOnly" 5 "Bridge" 14 "Error" 15 "Not Available" ;
VAL_ 2369519358 PinPullModeCommand_23 0 "None" 1 "PullDown" 2 "PullUp" 3 "Not Available" ;
VAL_ 2369519358 LoadDetectionCommand_23 0 "Off" 1 "On" 2 "Error" 3 "Not Available" ;
VAL_ 2369519358 PinModeCommand_24 0 "Disabled" 1 "VREF" 2 "HighSide" 3 "LowSide" 4 "InputOnly" 5 "Bridge" 14 "Error" 15 "Not Available" ;
VAL_ 2369519358 PinPullModeCommand_24 0 "None" 1 "PullDown" 2 "PullUp" 3 "Not Available" ;
VAL_ 2369519358 LoadDetectionCommand_24 0 "Off" 1 "On" 2 "Error" 3 "Not Available" ;
VAL_ 2369584894 PinModeCommand_25 0 "Disabled" 1 "VREF" 2 "HighSide" 3 "LowSide" 4 "InputOnly" 5 "Bridge" 14 "Error" 15 "Not Available" ;
VAL_ 2369584894 PinPullModeCommand_25 0 "None" 1 "PullDown" 2 "PullUp" 3 "Not Available" ;
VAL_ 2369584894 LoadDetectionCommand_25 0 "Off" 1 "On" 2 "Error" 3 "Not Available" ;
VAL_ 2369584894 PinModeCommand_26 0 "Disabled" 1 "VREF" 2 "HighSide" 3 "LowSide" 4 "InputOnly" 5 "Bridge" 14 "Error" 15 "Not Available" ;
VAL_ 2369584894 PinPullModeCommand_26 0 "None" 1 "PullDown" 2 "PullUp" 3 "Not Available" ;
VAL_ 2369584894 LoadDetectionCommand_26 0 "Off" 1 "On" 2 "Error" 3 "Not Available" ;
VAL_ 2369584894 PinModeCommand_27 0 "Disabled" 1 "VREF" 2 "HighSide" 3 "LowSide" 4 "InputOnly" 5 "Bridge" 14 "Error" 15 "Not Available" ;
VAL_ 2369584894 PinPullModeCommand_27 0 "None" 1 "PullDown" 2 "PullUp" 3 "Not Available" ;
VAL_ 2369584894 LoadDetectionCommand_27 0 "Off" 1 "On" 2 "Error" 3 "Not Available" ;
VAL_ 2369584894 PinModeCommand_28 0 "Disabled" 1 "VREF" 2 "HighSide" 3 "LowSide" 4 "InputOnly" 5 "Bridge" 14 "Error" 15 "Not Available" ;
VAL_ 2369584894 PinPullModeCommand_28 0 "None" 1 "PullDown" 2 "PullUp" 3 "Not Available" ;
VAL_ 2369584894 LoadDetectionCommand_28 0 "Off" 1 "On" 2 "Error" 3 "Not Available" ;
VAL_ 2369584894 PinModeCommand_29 0 "Disabled" 1 "VREF" 2 "HighSide" 3 "LowSide" 4 "InputOnly" 5 "Bridge" 14 "Error" 15 "Not Available" ;
VAL_ 2369584894 PinPullModeCommand_29 0 "None" 1 "PullDown" 2 "PullUp" 3 "Not Available" ;
VAL_ 2369584894 LoadDetectionCommand_29 0 "Off" 1 "On" 2 "Error" 3 "Not Available" ;
VAL_ 2369584894 PinModeCommand_30 0 "Disabled" 1 "VREF" 2 "HighSide" 3 "LowSide" 4 "InputOnly" 5 "Bridge" 14 "Error" 15 "Not Available" ;
VAL_ 2369584894 PinPullModeCommand_30 0 "None" 1 "PullDown" 2 "PullUp" 3 "Not Available" ;
VAL_ 2369584894 LoadDetectionCommand_30 0 "Off" 1 "On" 2 "Error" 3 "Not Available" ;
VAL_ 2369584894 PinModeCommand_31 0 "Disabled" 1 "VREF" 2 "HighSide" 3 "LowSide" 4 "InputOnly" 5 "Bridge" 14 "Error" 15 "Not Available" ;
VAL_ 2369584894 PinPullModeCommand_31 0 "None" 1 "PullDown" 2 "PullUp" 3 "Not Available" ;
VAL_ 2369584894 LoadDetectionCommand_31 0 "Off" 1 "On" 2 "Error" 3 "Not Available" ;
VAL_ 2369584894 PinModeCommand_32 0 "Disabled" 1 "VREF" 2 "HighSide" 3 "LowSide" 4 "InputOnly" 5 "Bridge" 14 "Error" 15 "Not Available" ;
VAL_ 2369584894 PinPullModeCommand_32 0 "None" 1 "PullDown" 2 "PullUp" 3 "Not Available" ;
VAL_ 2369584894 LoadDetectionCommand_32 0 "Off" 1 "On" 2 "Error" 3 "Not Available" ;
VAL_ 2369912574 PwmFrequencyCommand_01 0 "1 Hz" 1 "2 Hz" 2 "5 Hz" 3 "10 Hz" 4 "20 Hz" 5 "50 Hz" 6 "100 Hz" 7 "200 Hz" 8 "500 Hz" 9 "1 KHz" 10 "2 KHz" 11 "5 KHz" 12 "Custom 1" 13 "Custom 2" 14 "Custom 3" 15 "Not Available" ;
VAL_ 2369912574 PwmFrequencyCommand_02 0 "1 Hz" 1 "2 Hz" 2 "5 Hz" 3 "10 Hz" 4 "20 Hz" 5 "50 Hz" 6 "100 Hz" 7 "200 Hz" 8 "500 Hz" 9 "1 KHz" 10 "2 KHz" 11 "5 KHz" 12 "Custom 1" 13 "Custom 2" 14 "Custom 3" 15 "Not Available" ;
VAL_ 2369912574 PwmFrequencyCommand_03 0 "1 Hz" 1 "2 Hz" 2 "5 Hz" 3 "10 Hz" 4 "20 Hz" 5 "50 Hz" 6 "100 Hz" 7 "200 Hz" 8 "500 Hz" 9 "1 KHz" 10 "2 KHz" 11 "5 KHz" 12 "Custom 1" 13 "Custom 2" 14 "Custom 3" 15 "Not Available" ;
VAL_ 2369912574 PwmFrequencyCommand_04 0 "1 Hz" 1 "2 Hz" 2 "5 Hz" 3 "10 Hz" 4 "20 Hz" 5 "50 Hz" 6 "100 Hz" 7 "200 Hz" 8 "500 Hz" 9 "1 KHz" 10 "2 KHz" 11 "5 KHz" 12 "Custom 1" 13 "Custom 2" 14 "Custom 3" 15 "Not Available" ;
VAL_ 2369912574 PwmFrequencyCommand_05 0 "1 Hz" 1 "2 Hz" 2 "5 Hz" 3 "10 Hz" 4 "20 Hz" 5 "50 Hz" 6 "100 Hz" 7 "200 Hz" 8 "500 Hz" 9 "1 KHz" 10 "2 KHz" 11 "5 KHz" 12 "Custom 1" 13 "Custom 2" 14 "Custom 3" 15 "Not Available" ;
VAL_ 2369912574 PwmFrequencyCommand_06 0 "1 Hz" 1 "2 Hz" 2 "5 Hz" 3 "10 Hz" 4 "20 Hz" 5 "50 Hz" 6 "100 Hz" 7 "200 Hz" 8 "500 Hz" 9 "1 KHz" 10 "2 KHz" 11 "5 KHz" 12 "Custom 1" 13 "Custom 2" 14 "Custom 3" 15 "Not Available" ;
VAL_ 2369912574 PwmFrequencyCommand_07 0 "1 Hz" 1 "2 Hz" 2 "5 Hz" 3 "10 Hz" 4 "20 Hz" 5 "50 Hz" 6 "100 Hz" 7 "200 Hz" 8 "500 Hz" 9 "1 KHz" 10 "2 KHz" 11 "5 KHz" 12 "Custom 1" 13 "Custom 2" 14 "Custom 3" 15 "Not Available" ;
VAL_ 2369912574 PwmFrequencyCommand_08 0 "1 Hz" 1 "2 Hz" 2 "5 Hz" 3 "10 Hz" 4 "20 Hz" 5 "50 Hz" 6 "100 Hz" 7 "200 Hz" 8 "500 Hz" 9 "1 KHz" 10 "2 KHz" 11 "5 KHz" 12 "Custom 1" 13 "Custom 2" 14 "Custom 3" 15 "Not Available" ;
VAL_ 2369912574 PwmFrequencyCommand_09 0 "1 Hz" 1 "2 Hz" 2 "5 Hz" 3 "10 Hz" 4 "20 Hz" 5 "50 Hz" 6 "100 Hz" 7 "200 Hz" 8 "500 Hz" 9 "1 KHz" 10 "2 KHz" 11 "5 KHz" 12 "Custom 1" 13 "Custom 2" 14 "Custom 3" 15 "Not Available" ;
VAL_ 2369912574 PwmFrequencyCommand_10 0 "1 Hz" 1 "2 Hz" 2 "5 Hz" 3 "10 Hz" 4 "20 Hz" 5 "50 Hz" 6 "100 Hz" 7 "200 Hz" 8 "500 Hz" 9 "1 KHz" 10 "2 KHz" 11 "5 KHz" 12 "Custom 1" 13 "Custom 2" 14 "Custom 3" 15 "Not Available" ;
VAL_ 2369912574 PwmFrequencyCommand_11 0 "1 Hz" 1 "2 Hz" 2 "5 Hz" 3 "10 Hz" 4 "20 Hz" 5 "50 Hz" 6 "100 Hz" 7 "200 Hz" 8 "500 Hz" 9 "1 KHz" 10 "2 KHz" 11 "5 KHz" 12 "Custom 1" 13 "Custom 2" 14 "Custom 3" 15 "Not Available" ;
VAL_ 2369912574 PwmFrequencyCommand_12 0 "1 Hz" 1 "2 Hz" 2 "5 Hz" 3 "10 Hz" 4 "20 Hz" 5 "50 Hz" 6 "100 Hz" 7 "200 Hz" 8 "500 Hz" 9 "1 KHz" 10 "2 KHz" 11 "5 KHz" 12 "Custom 1" 13 "Custom 2" 14 "Custom 3" 15 "Not Available" ;
VAL_ 2369912574 PwmFrequencyCommand_13 0 "1 Hz" 1 "2 Hz" 2 "5 Hz" 3 "10 Hz" 4 "20 Hz" 5 "50 Hz" 6 "100 Hz" 7 "200 Hz" 8 "500 Hz" 9 "1 KHz" 10 "2 KHz" 11 "5 KHz" 12 "Custom 1" 13 "Custom 2" 14 "Custom 3" 15 "Not Available" ;
VAL_ 2369912574 PwmFrequencyCommand_14 0 "1 Hz" 1 "2 Hz" 2 "5 Hz" 3 "10 Hz" 4 "20 Hz" 5 "50 Hz" 6 "100 Hz" 7 "200 Hz" 8 "500 Hz" 9 "1 KHz" 10 "2 KHz" 11 "5 KHz" 12 "Custom 1" 13 "Custom 2" 14 "Custom 3" 15 "Not Available" ;
VAL_ 2369912574 PwmFrequencyCommand_15 0 "1 Hz" 1 "2 Hz" 2 "5 Hz" 3 "10 Hz" 4 "20 Hz" 5 "50 Hz" 6 "100 Hz" 7 "200 Hz" 8 "500 Hz" 9 "1 KHz" 10 "2 KHz" 11 "5 KHz" 12 "Custom 1" 13 "Custom 2" 14 "Custom 3" 15 "Not Available" ;
VAL_ 2369912574 PwmFrequencyCommand_16 0 "1 Hz" 1 "2 Hz" 2 "5 Hz" 3 "10 Hz" 4 "20 Hz" 5 "50 Hz" 6 "100 Hz" 7 "200 Hz" 8 "500 Hz" 9 "1 KHz" 10 "2 KHz" 11 "5 KHz" 12 "Custom 1" 13 "Custom 2" 14 "Custom 3" 15 "Not Available" ;
VAL_ 2369978110 PwmFrequencyCommand_17 0 "1 Hz" 1 "2 Hz" 2 "5 Hz" 3 "10 Hz" 4 "20 Hz" 5 "50 Hz" 6 "100 Hz" 7 "200 Hz" 8 "500 Hz" 9 "1 KHz" 10 "2 KHz" 11 "5 KHz" 12 "Custom 1" 13 "Custom 2" 14 "Custom 3" 15 "Not Available" ;
VAL_ 2369978110 PwmFrequencyCommand_18 0 "1 Hz" 1 "2 Hz" 2 "5 Hz" 3 "10 Hz" 4 "20 Hz" 5 "50 Hz" 6 "100 Hz" 7 "200 Hz" 8 "500 Hz" 9 "1 KHz" 10 "2 KHz" 11 "5 KHz" 12 "Custom 1" 13 "Custom 2" 14 "Custom 3" 15 "Not Available" ;
VAL_ 2369978110 PwmFrequencyCommand_19 0 "1 Hz" 1 "2 Hz" 2 "5 Hz" 3 "10 Hz" 4 "20 Hz" 5 "50 Hz" 6 "100 Hz" 7 "200 Hz" 8 "500 Hz" 9 "1 KHz" 10 "2 KHz" 11 "5 KHz" 12 "Custom 1" 13 "Custom 2" 14 "Custom 3" 15 "Not Available" ;
VAL_ 2369978110 PwmFrequencyCommand_20 0 "1 Hz" 1 "2 Hz" 2 "5 Hz" 3 "10 Hz" 4 "20 Hz" 5 "50 Hz" 6 "100 Hz" 7 "200 Hz" 8 "500 Hz" 9 "1 KHz" 10 "2 KHz" 11 "5 KHz" 12 "Custom 1" 13 "Custom 2" 14 "Custom 3" 15 "Not Available" ;
VAL_ 2369978110 PwmFrequencyCommand_21 0 "1 Hz" 1 "2 Hz" 2 "5 Hz" 3 "10 Hz" 4 "20 Hz" 5 "50 Hz" 6 "100 Hz" 7 "200 Hz" 8 "500 Hz" 9 "1 KHz" 10 "2 KHz" 11 "5 KHz" 12 "Custom 1" 13 "Custom 2" 14 "Custom 3" 15 "Not Available" ;
VAL_ 2369978110 PwmFrequencyCommand_22 0 "1 Hz" 1 "2 Hz" 2 "5 Hz" 3 "10 Hz" 4 "20 Hz" 5 "50 Hz" 6 "100 Hz" 7 "200 Hz" 8 "500 Hz" 9 "1 KHz" 10 "2 KHz" 11 "5 KHz" 12 "Custom 1" 13 "Custom 2" 14 "Custom 3" 15 "Not Available" ;
VAL_ 2369978110 PwmFrequencyCommand_23 0 "1 Hz" 1 "2 Hz" 2 "5 Hz" 3 "10 Hz" 4 "20 Hz" 5 "50 Hz" 6 "100 Hz" 7 "200 Hz" 8 "500 Hz" 9 "1 KHz" 10 "2 KHz" 11 "5 KHz" 12 "Custom 1" 13 "Custom 2" 14 "Custom 3" 15 "Not Available" ;
VAL_ 2369978110 PwmFrequencyCommand_24 0 "1 Hz" 1 "2 Hz" 2 "5 Hz" 3 "10 Hz" 4 "20 Hz" 5 "50 Hz" 6 "100 Hz" 7 "200 Hz" 8 "500 Hz" 9 "1 KHz" 10 "2 KHz" 11 "5 KHz" 12 "Custom 1" 13 "Custom 2" 14 "Custom 3" 15 "Not Available" ;
VAL_ 2369978110 PwmFrequencyCommand_25 0 "1 Hz" 1 "2 Hz" 2 "5 Hz" 3 "10 Hz" 4 "20 Hz" 5 "50 Hz" 6 "100 Hz" 7 "200 Hz" 8 "500 Hz" 9 "1 KHz" 10 "2 KHz" 11 "5 KHz" 12 "Custom 1" 13 "Custom 2" 14 "Custom 3" 15 "Not Available" ;
VAL_ 2369978110 PwmFrequencyCommand_26 0 "1 Hz" 1 "2 Hz" 2 "5 Hz" 3 "10 Hz" 4 "20 Hz" 5 "50 Hz" 6 "100 Hz" 7 "200 Hz" 8 "500 Hz" 9 "1 KHz" 10 "2 KHz" 11 "5 KHz" 12 "Custom 1" 13 "Custom 2" 14 "Custom 3" 15 "Not Available" ;
VAL_ 2369978110 PwmFrequencyCommand_27 0 "1 Hz" 1 "2 Hz" 2 "5 Hz" 3 "10 Hz" 4 "20 Hz" 5 "50 Hz" 6 "100 Hz" 7 "200 Hz" 8 "500 Hz" 9 "1 KHz" 10 "2 KHz" 11 "5 KHz" 12 "Custom 1" 13 "Custom 2" 14 "Custom 3" 15 "Not Available" ;
VAL_ 2369978110 PwmFrequencyCommand_28 0 "1 Hz" 1 "2 Hz" 2 "5 Hz" 3 "10 Hz" 4 "20 Hz" 5 "50 Hz" 6 "100 Hz" 7 "200 Hz" 8 "500 Hz" 9 "1 KHz" 10 "2 KHz" 11 "5 KHz" 12 "Custom 1" 13 "Custom 2" 14 "Custom 3" 15 "Not Available" ;
VAL_ 2369978110 PwmFrequencyCommand_29 0 "1 Hz" 1 "2 Hz" 2 "5 Hz" 3 "10 Hz" 4 "20 Hz" 5 "50 Hz" 6 "100 Hz" 7 "200 Hz" 8 "500 Hz" 9 "1 KHz" 10 "2 KHz" 11 "5 KHz" 12 "Custom 1" 13 "Custom 2" 14 "Custom 3" 15 "Not Available" ;
VAL_ 2369978110 PwmFrequencyCommand_30 0 "1 Hz" 1 "2 Hz" 2 "5 Hz" 3 "10 Hz" 4 "20 Hz" 5 "50 Hz" 6 "100 Hz" 7 "200 Hz" 8 "500 Hz" 9 "1 KHz" 10 "2 KHz" 11 "5 KHz" 12 "Custom 1" 13 "Custom 2" 14 "Custom 3" 15 "Not Available" ;
VAL_ 2369978110 PwmFrequencyCommand_31 0 "1 Hz" 1 "2 Hz" 2 "5 Hz" 3 "10 Hz" 4 "20 Hz" 5 "50 Hz" 6 "100 Hz" 7 "200 Hz" 8 "500 Hz" 9 "1 KHz" 10 "2 KHz" 11 "5 KHz" 12 "Custom 1" 13 "Custom 2" 14 "Custom 3" 15 "Not Available" ;
VAL_ 2369978110 PwmFrequencyCommand_32 0 "1 Hz" 1 "2 Hz" 2 "5 Hz" 3 "10 Hz" 4 "20 Hz" 5 "50 Hz" 6 "100 Hz" 7 "200 Hz" 8 "500 Hz" 9 "1 KHz" 10 "2 KHz" 11 "5 KHz" 12 "Custom 1" 13 "Custom 2" 14 "Custom 3" 15 "Not Available" ;
VAL_ 2583656190 BridgeModeStatus_b01 0 "Freewheeling" 1 "Forward" 2 "Reverse" 3 "Brake" 6 "Error" 7 "Not Available" ;
VAL_ 2583656190 BridgeStatus_b01 0 "OK" 1 "Shutdown" 2 "Unconfigured" 7 "Not Available" ;
VAL_ 2583656190 BridgeModeStatus_b02 0 "Freewheeling" 1 "Forward" 2 "Reverse" 3 "Brake" 6 "Error" 7 "Not Available" ;
VAL_ 2583656190 BridgeStatus_b02 0 "OK" 1 "Shutdown" 2 "Unconfigured" 7 "Not Available" ;
VAL_ 2583656190 BridgeModeStatus_b03 0 "Freewheeling" 1 "Forward" 2 "Reverse" 3 "Brake" 6 "Error" 7 "Not Available" ;
VAL_ 2583656190 BridgeStatus_b03 0 "OK" 1 "Shutdown" 2 "Unconfigured" 7 "Not Available" ;
VAL_ 2583656190 BridgeModeStatus_b04 0 "Freewheeling" 1 "Forward" 2 "Reverse" 3 "Brake" 6 "Error" 7 "Not Available" ;
VAL_ 2583656190 BridgeStatus_b04 0 "OK" 1 "Shutdown" 2 "Unconfigured" 7 "Not Available" ;
VAL_ 2583656190 BridgeModeStatus_b05 0 "Freewheeling" 1 "Forward" 2 "Reverse" 3 "Brake" 6 "Error" 7 "Not Available" ;
VAL_ 2583656190 BridgeStatus_b05 0 "OK" 1 "Shutdown" 2 "Unconfigured" 7 "Not Available" ;
VAL_ 2583656190 BridgeModeStatus_b06 0 "Freewheeling" 1 "Forward" 2 "Reverse" 3 "Brake" 6 "Error" 7 "Not Available" ;
VAL_ 2583656190 BridgeStatus_b06 0 "OK" 1 "Shutdown" 2 "Unconfigured" 7 "Not Available" ;
VAL_ 2583656190 BridgeModeStatus_b07 0 "Freewheeling" 1 "Forward" 2 "Reverse" 3 "Brake" 6 "Error" 7 "Not Available" ;
VAL_ 2583656190 BridgeStatus_b07 0 "OK" 1 "Shutdown" 2 "Unconfigured" 7 "Not Available" ;
VAL_ 2583656190 BridgeModeStatus_b08 0 "Freewheeling" 1 "Forward" 2 "Reverse" 3 "Brake" 6 "Error" 7 "Not Available" ;
VAL_ 2583656190 BridgeStatus_b08 0 "OK" 1 "Shutdown" 2 "Unconfigured" 7 "Not Available" ;
VAL_ 2583648766 DiagnosticStatus_01 0 "OK" 1 "Open Load" 2 "Short to VBAT" 3 "Short to GND" 4 "Over-current" 5 "Over temperature" 6 "Under voltage" 7 "Over voltage" 8 "Bad Configuration" 9 "HW Fault Detected" 10 "Vbat Error" 14 "Error" 15 "Not Available" ;
VAL_ 2583648766 DiagnosticStatus_02 0 "OK" 1 "Open Load" 2 "Short to VBAT" 3 "Short to GND" 4 "Over-current" 5 "Over temperature" 6 "Under voltage" 7 "Over voltage" 8 "Bad Configuration" 9 "HW Fault Detected" 10 "Vbat Error" 14 "Error" 15 "Not Available" ;
VAL_ 2583648766 DiagnosticStatus_03 0 "OK" 1 "Open Load" 2 "Short to VBAT" 3 "Short to GND" 4 "Over-current" 5 "Over temperature" 6 "Under voltage" 7 "Over voltage" 8 "Bad Configuration" 9 "HW Fault Detected" 10 "Vbat Error" 14 "Error" 15 "Not Available" ;
VAL_ 2583648766 DiagnosticStatus_04 0 "OK" 1 "Open Load" 2 "Short to VBAT" 3 "Short to GND" 4 "Over-current" 5 "Over temperature" 6 "Under voltage" 7 "Over voltage" 8 "Bad Configuration" 9 "HW Fault Detected" 10 "Vbat Error" 14 "Error" 15 "Not Available" ;
VAL_ 2583648766 DiagnosticStatus_05 0 "OK" 1 "Open Load" 2 "Short to VBAT" 3 "Short to GND" 4 "Over-current" 5 "Over temperature" 6 "Under voltage" 7 "Over voltage" 8 "Bad Configuration" 9 "HW Fault Detected" 10 "Vbat Error" 14 "Error" 15 "Not Available" ;
VAL_ 2583648766 DiagnosticStatus_06 0 "OK" 1 "Open Load" 2 "Short to VBAT" 3 "Short to GND" 4 "Over-current" 5 "Over temperature" 6 "Under voltage" 7 "Over voltage" 8 "Bad Configuration" 9 "HW Fault Detected" 10 "Vbat Error" 14 "Error" 15 "Not Available" ;
VAL_ 2583648766 DiagnosticStatus_07 0 "OK" 1 "Open Load" 2 "Short to VBAT" 3 "Short to GND" 4 "Over-current" 5 "Over temperature" 6 "Under voltage" 7 "Over voltage" 8 "Bad Configuration" 9 "HW Fault Detected" 10 "Vbat Error" 14 "Error" 15 "Not Available" ;
VAL_ 2583648766 DiagnosticStatus_08 0 "OK" 1 "Open Load" 2 "Short to VBAT" 3 "Short to GND" 4 "Over-current" 5 "Over temperature" 6 "Under voltage" 7 "Over voltage" 8 "Bad Configuration" 9 "HW Fault Detected" 10 "Vbat Error" 14 "Error" 15 "Not Available" ;
VAL_ 2583648766 DiagnosticStatus_09 0 "OK" 1 "Open Load" 2 "Short to VBAT" 3 "Short to GND" 4 "Over-current" 5 "Over temperature" 6 "Under voltage" 7 "Over voltage" 8 "Bad Configuration" 9 "HW Fault Detected" 10 "Vbat Error" 14 "Error" 15 "Not Available" ;
VAL_ 2583648766 DiagnosticStatus_10 0 "OK" 1 "Open Load" 2 "Short to VBAT" 3 "Short to GND" 4 "Over-current" 5 "Over temperature" 6 "Under voltage" 7 "Over voltage" 8 "Bad Configuration" 9 "HW Fault Detected" 10 "Vbat Error" 14 "Error" 15 "Not Available" ;
VAL_ 2583648766 DiagnosticStatus_11 0 "OK" 1 "Open Load" 2 "Short to VBAT" 3 "Short to GND" 4 "Over-current" 5 "Over temperature" 6 "Under voltage" 7 "Over voltage" 8 "Bad Configuration" 9 "HW Fault Detected" 10 "Vbat Error" 14 "Error" 15 "Not Available" ;
VAL_ 2583648766 DiagnosticStatus_12 0 "OK" 1 "Open Load" 2 "Short to VBAT" 3 "Short to GND" 4 "Over-current" 5 "Over temperature" 6 "Under voltage" 7 "Over voltage" 8 "Bad Configuration" 9 "HW Fault Detected" 10 "Vbat Error" 14 "Error" 15 "Not Available" ;
VAL_ 2583648766 DiagnosticStatus_13 0 "OK" 1 "Open Load" 2 "Short to VBAT" 3 "Short to GND" 4 "Over-current" 5 "Over temperature" 6 "Under voltage" 7 "Over voltage" 8 "Bad Configuration" 9 "HW Fault Detected" 10 "Vbat Error" 14 "Error" 15 "Not Available" ;
VAL_ 2583648766 DiagnosticStatus_14 0 "OK" 1 "Open Load" 2 "Short to VBAT" 3 "Short to GND" 4 "Over-current" 5 "Over temperature" 6 "Under voltage" 7 "Over voltage" 8 "Bad Configuration" 9 "HW Fault Detected" 10 "Vbat Error" 14 "Error" 15 "Not Available" ;
VAL_ 2583648766 DiagnosticStatus_15 0 "OK" 1 "Open Load" 2 "Short to VBAT" 3 "Short to GND" 4 "Over-current" 5 "Over temperature" 6 "Under voltage" 7 "Over voltage" 8 "Bad Configuration" 9 "HW Fault Detected" 10 "Vbat Error" 14 "Error" 15 "Not Available" ;
VAL_ 2583648766 DiagnosticStatus_16 0 "OK" 1 "Open Load" 2 "Short to VBAT" 3 "Short to GND" 4 "Over-current" 5 "Over temperature" 6 "Under voltage" 7 "Over voltage" 8 "Bad Configuration" 9 "HW Fault Detected" 10 "Vbat Error" 14 "Error" 15 "Not Available" ;
VAL_ 2583649022 DiagnosticStatus_17 0 "OK" 1 "Open Load" 2 "Short to VBAT" 3 "Short to GND" 4 "Over-current" 5 "Over temperature" 6 "Under voltage" 7 "Over voltage" 8 "Bad Configuration" 9 "HW Fault Detected" 10 "Vbat Error" 14 "Error" 15 "Not Available" ;
VAL_ 2583649022 DiagnosticStatus_18 0 "OK" 1 "Open Load" 2 "Short to VBAT" 3 "Short to GND" 4 "Over-current" 5 "Over temperature" 6 "Under voltage" 7 "Over voltage" 8 "Bad Configuration" 9 "HW Fault Detected" 10 "Vbat Error" 14 "Error" 15 "Not Available" ;
VAL_ 2583649022 DiagnosticStatus_19 0 "OK" 1 "Open Load" 2 "Short to VBAT" 3 "Short to GND" 4 "Over-current" 5 "Over temperature" 6 "Under voltage" 7 "Over voltage" 8 "Bad Configuration" 9 "HW Fault Detected" 10 "Vbat Error" 14 "Error" 15 "Not Available" ;
VAL_ 2583649022 DiagnosticStatus_20 0 "OK" 1 "Open Load" 2 "Short to VBAT" 3 "Short to GND" 4 "Over-current" 5 "Over temperature" 6 "Under voltage" 7 "Over voltage" 8 "Bad Configuration" 9 "HW Fault Detected" 10 "Vbat Error" 14 "Error" 15 "Not Available" ;
VAL_ 2583649022 DiagnosticStatus_21 0 "OK" 1 "Open Load" 2 "Short to VBAT" 3 "Short to GND" 4 "Over-current" 5 "Over temperature" 6 "Under voltage" 7 "Over voltage" 8 "Bad Configuration" 9 "HW Fault Detected" 10 "Vbat Error" 14 "Error" 15 "Not Available" ;
VAL_ 2583649022 DiagnosticStatus_22 0 "OK" 1 "Open Load" 2 "Short to VBAT" 3 "Short to GND" 4 "Over-current" 5 "Over temperature" 6 "Under voltage" 7 "Over voltage" 8 "Bad Configuration" 9 "HW Fault Detected" 10 "Vbat Error" 14 "Error" 15 "Not Available" ;
VAL_ 2583649022 DiagnosticStatus_23 0 "OK" 1 "Open Load" 2 "Short to VBAT" 3 "Short to GND" 4 "Over-current" 5 "Over temperature" 6 "Under voltage" 7 "Over voltage" 8 "Bad Configuration" 9 "HW Fault Detected" 10 "Vbat Error" 14 "Error" 15 "Not Available" ;
VAL_ 2583649022 DiagnosticStatus_24 0 "OK" 1 "Open Load" 2 "Short to VBAT" 3 "Short to GND" 4 "Over-current" 5 "Over temperature" 6 "Under voltage" 7 "Over voltage" 8 "Bad Configuration" 9 "HW Fault Detected" 10 "Vbat Error" 14 "Error" 15 "Not Available" ;
VAL_ 2583649022 DiagnosticStatus_25 0 "OK" 1 "Open Load" 2 "Short to VBAT" 3 "Short to GND" 4 "Over-current" 5 "Over temperature" 6 "Under voltage" 7 "Over voltage" 8 "Bad Configuration" 9 "HW Fault Detected" 10 "Vbat Error" 14 "Error" 15 "Not Available" ;
VAL_ 2583649022 DiagnosticStatus_26 0 "OK" 1 "Open Load" 2 "Short to VBAT" 3 "Short to GND" 4 "Over-current" 5 "Over temperature" 6 "Under voltage" 7 "Over voltage" 8 "Bad Configuration" 9 "HW Fault Detected" 10 "Vbat Error" 14 "Error" 15 "Not Available" ;
VAL_ 2583649022 DiagnosticStatus_27 0 "OK" 1 "Open Load" 2 "Short to VBAT" 3 "Short to GND" 4 "Over-current" 5 "Over temperature" 6 "Under voltage" 7 "Over voltage" 8 "Bad Configuration" 9 "HW Fault Detected" 10 "Vbat Error" 14 "Error" 15 "Not Available" ;
VAL_ 2583649022 DiagnosticStatus_28 0 "OK" 1 "Open Load" 2 "Short to VBAT" 3 "Short to GND" 4 "Over-current" 5 "Over temperature" 6 "Under voltage" 7 "Over voltage" 8 "Bad Configuration" 9 "HW Fault Detected" 10 "Vbat Error" 14 "Error" 15 "Not Available" ;
VAL_ 2583649022 DiagnosticStatus_29 0 "OK" 1 "Open Load" 2 "Short to VBAT" 3 "Short to GND" 4 "Over-current" 5 "Over temperature" 6 "Under voltage" 7 "Over voltage" 8 "Bad Configuration" 9 "HW Fault Detected" 10 "Vbat Error" 14 "Error" 15 "Not Available" ;
VAL_ 2583649022 DiagnosticStatus_30 0 "OK" 1 "Open Load" 2 "Short to VBAT" 3 "Short to GND" 4 "Over-current" 5 "Over temperature" 6 "Under voltage" 7 "Over voltage" 8 "Bad Configuration" 9 "HW Fault Detected" 10 "Vbat Error" 14 "Error" 15 "Not Available" ;
VAL_ 2583649022 DiagnosticStatus_31 0 "OK" 1 "Open Load" 2 "Short to VBAT" 3 "Short to GND" 4 "Over-current" 5 "Over temperature" 6 "Under voltage" 7 "Over voltage" 8 "Bad Configuration" 9 "HW Fault Detected" 10 "Vbat Error" 14 "Error" 15 "Not Available" ;
VAL_ 2583649022 DiagnosticStatus_32 0 "OK" 1 "Open Load" 2 "Short to VBAT" 3 "Short to GND" 4 "Over-current" 5 "Over temperature" 6 "Under voltage" 7 "Over voltage" 8 "Bad Configuration" 9 "HW Fault Detected" 10 "Vbat Error" 14 "Error" 15 "Not Available" ;
VAL_ 2582847486 DiagnosticStatus_01 0 "OK" 1 "Open Load" 2 "Short to VBAT" 3 "Short to GND" 4 "Over-current" 5 "Over temperature" 6 "Under voltage" 7 "Over voltage" 8 "Bad Configuration" 9 "HW Fault Detected" 10 "Vbat Error" 14 "Error" 15 "Not Available" ;
VAL_ 2582847486 DiagnosticStatus_02 0 "OK" 1 "Open Load" 2 "Short to VBAT" 3 "Short to GND" 4 "Over-current" 5 "Over temperature" 6 "Under voltage" 7 "Over voltage" 8 "Bad Configuration" 9 "HW Fault Detected" 10 "Vbat Error" 14 "Error" 15 "Not Available" ;
VAL_ 2582847486 DiagnosticStatus_03 0 "OK" 1 "Open Load" 2 "Short to VBAT" 3 "Short to GND" 4 "Over-current" 5 "Over temperature" 6 "Under voltage" 7 "Over voltage" 8 "Bad Configuration" 9 "HW Fault Detected" 10 "Vbat Error" 14 "Error" 15 "Not Available" ;
VAL_ 2582847486 DiagnosticStatus_04 0 "OK" 1 "Open Load" 2 "Short to VBAT" 3 "Short to GND" 4 "Over-current" 5 "Over temperature" 6 "Under voltage" 7 "Over voltage" 8 "Bad Configuration" 9 "HW Fault Detected" 10 "Vbat Error" 14 "Error" 15 "Not Available" ;
VAL_ 2582847486 DiagnosticStatus_05 0 "OK" 1 "Open Load" 2 "Short to VBAT" 3 "Short to GND" 4 "Over-current" 5 "Over temperature" 6 "Under voltage" 7 "Over voltage" 8 "Bad Configuration" 9 "HW Fault Detected" 10 "Vbat Error" 14 "Error" 15 "Not Available" ;
VAL_ 2582847486 DiagnosticStatus_06 0 "OK" 1 "Open Load" 2 "Short to VBAT" 3 "Short to GND" 4 "Over-current" 5 "Over temperature" 6 "Under voltage" 7 "Over voltage" 8 "Bad Configuration" 9 "HW Fault Detected" 10 "Vbat Error" 14 "Error" 15 "Not Available" ;
VAL_ 2582847486 DiagnosticStatus_07 0 "OK" 1 "Open Load" 2 "Short to VBAT" 3 "Short to GND" 4 "Over-current" 5 "Over temperature" 6 "Under voltage" 7 "Over voltage" 8 "Bad Configuration" 9 "HW Fault Detected" 10 "Vbat Error" 14 "Error" 15 "Not Available" ;
VAL_ 2582847486 DiagnosticStatus_08 0 "OK" 1 "Open Load" 2 "Short to VBAT" 3 "Short to GND" 4 "Over-current" 5 "Over temperature" 6 "Under voltage" 7 "Over voltage" 8 "Bad Configuration" 9 "HW Fault Detected" 10 "Vbat Error" 14 "Error" 15 "Not Available" ;
VAL_ 2582847486 DiagnosticStatus_09 0 "OK" 1 "Open Load" 2 "Short to VBAT" 3 "Short to GND" 4 "Over-current" 5 "Over temperature" 6 "Under voltage" 7 "Over voltage" 8 "Bad Configuration" 9 "HW Fault Detected" 10 "Vbat Error" 14 "Error" 15 "Not Available" ;
VAL_ 2582847486 DiagnosticStatus_10 0 "OK" 1 "Open Load" 2 "Short to VBAT" 3 "Short to GND" 4 "Over-current" 5 "Over temperature" 6 "Under voltage" 7 "Over voltage" 8 "Bad Configuration" 9 "HW Fault Detected" 10 "Vbat Error" 14 "Error" 15 "Not Available" ;
VAL_ 2582847486 DiagnosticStatus_11 0 "OK" 1 "Open Load" 2 "Short to VBAT" 3 "Short to GND" 4 "Over-current" 5 "Over temperature" 6 "Under voltage" 7 "Over voltage" 8 "Bad Configuration" 9 "HW Fault Detected" 10 "Vbat Error" 14 "Error" 15 "Not Available" ;
VAL_ 2582847486 DiagnosticStatus_12 0 "OK" 1 "Open Load" 2 "Short to VBAT" 3 "Short to GND" 4 "Over-current" 5 "Over temperature" 6 "Under voltage" 7 "Over voltage" 8 "Bad Configuration" 9 "HW Fault Detected" 10 "Vbat Error" 14 "Error" 15 "Not Available" ;
VAL_ 2582847486 DiagnosticStatus_13 0 "OK" 1 "Open Load" 2 "Short to VBAT" 3 "Short to GND" 4 "Over-current" 5 "Over temperature" 6 "Under voltage" 7 "Over voltage" 8 "Bad Configuration" 9 "HW Fault Detected" 10 "Vbat Error" 14 "Error" 15 "Not Available" ;
VAL_ 2582847486 DiagnosticStatus_14 0 "OK" 1 "Open Load" 2 "Short to VBAT" 3 "Short to GND" 4 "Over-current" 5 "Over temperature" 6 "Under voltage" 7 "Over voltage" 8 "Bad Configuration" 9 "HW Fault Detected" 10 "Vbat Error" 14 "Error" 15 "Not Available" ;
VAL_ 2582847486 DiagnosticStatus_15 0 "OK" 1 "Open Load" 2 "Short to VBAT" 3 "Short to GND" 4 "Over-current" 5 "Over temperature" 6 "Under voltage" 7 "Over voltage" 8 "Bad Configuration" 9 "HW Fault Detected" 10 "Vbat Error" 14 "Error" 15 "Not Available" ;
VAL_ 2582847486 DiagnosticStatus_16 0 "OK" 1 "Open Load" 2 "Short to VBAT" 3 "Short to GND" 4 "Over-current" 5 "Over temperature" 6 "Under voltage" 7 "Over voltage" 8 "Bad Configuration" 9 "HW Fault Detected" 10 "Vbat Error" 14 "Error" 15 "Not Available" ;
VAL_ 2582847486 DiagnosticStatus_17 0 "OK" 1 "Open Load" 2 "Short to VBAT" 3 "Short to GND" 4 "Over-current" 5 "Over temperature" 6 "Under voltage" 7 "Over voltage" 8 "Bad Configuration" 9 "HW Fault Detected" 10 "Vbat Error" 14 "Error" 15 "Not Available" ;
VAL_ 2582847486 DiagnosticStatus_18 0 "OK" 1 "Open Load" 2 "Short to VBAT" 3 "Short to GND" 4 "Over-current" 5 "Over temperature" 6 "Under voltage" 7 "Over voltage" 8 "Bad Configuration" 9 "HW Fault Detected" 10 "Vbat Error" 14 "Error" 15 "Not Available" ;
VAL_ 2582847486 DiagnosticStatus_19 0 "OK" 1 "Open Load" 2 "Short to VBAT" 3 "Short to GND" 4 "Over-current" 5 "Over temperature" 6 "Under voltage" 7 "Over voltage" 8 "Bad Configuration" 9 "HW Fault Detected" 10 "Vbat Error" 14 "Error" 15 "Not Available" ;
VAL_ 2582847486 DiagnosticStatus_20 0 "OK" 1 "Open Load" 2 "Short to VBAT" 3 "Short to GND" 4 "Over-current" 5 "Over temperature" 6 "Under voltage" 7 "Over voltage" 8 "Bad Configuration" 9 "HW Fault Detected" 10 "Vbat Error" 14 "Error" 15 "Not Available" ;
VAL_ 2582847486 DiagnosticStatus_21 0 "OK" 1 "Open Load" 2 "Short to VBAT" 3 "Short to GND" 4 "Over-current" 5 "Over temperature" 6 "Under voltage" 7 "Over voltage" 8 "Bad Configuration" 9 "HW Fault Detected" 10 "Vbat Error" 14 "Error" 15 "Not Available" ;
VAL_ 2582847486 DiagnosticStatus_22 0 "OK" 1 "Open Load" 2 "Short to VBAT" 3 "Short to GND" 4 "Over-current" 5 "Over temperature" 6 "Under voltage" 7 "Over voltage" 8 "Bad Configuration" 9 "HW Fault Detected" 10 "Vbat Error" 14 "Error" 15 "Not Available" ;
VAL_ 2582847486 DiagnosticStatus_23 0 "OK" 1 "Open Load" 2 "Short to VBAT" 3 "Short to GND" 4 "Over-current" 5 "Over temperature" 6 "Under voltage" 7 "Over voltage" 8 "Bad Configuration" 9 "HW Fault Detected" 10 "Vbat Error" 14 "Error" 15 "Not Available" ;
VAL_ 2582847486 DiagnosticStatus_24 0 "OK" 1 "Open Load" 2 "Short to VBAT" 3 "Short to GND" 4 "Over-current" 5 "Over temperature" 6 "Under voltage" 7 "Over voltage" 8 "Bad Configuration" 9 "HW Fault Detected" 10 "Vbat Error" 14 "Error" 15 "Not Available" ;
VAL_ 2582847486 DiagnosticStatus_25 0 "OK" 1 "Open Load" 2 "Short to VBAT" 3 "Short to GND" 4 "Over-current" 5 "Over temperature" 6 "Under voltage" 7 "Over voltage" 8 "Bad Configuration" 9 "HW Fault Detected" 10 "Vbat Error" 14 "Error" 15 "Not Available" ;
VAL_ 2582847486 DiagnosticStatus_26 0 "OK" 1 "Open Load" 2 "Short to VBAT" 3 "Short to GND" 4 "Over-current" 5 "Over temperature" 6 "Under voltage" 7 "Over voltage" 8 "Bad Configuration" 9 "HW Fault Detected" 10 "Vbat Error" 14 "Error" 15 "Not Available" ;
VAL_ 2582847486 DiagnosticStatus_27 0 "OK" 1 "Open Load" 2 "Short to VBAT" 3 "Short to GND" 4 "Over-current" 5 "Over temperature" 6 "Under voltage" 7 "Over voltage" 8 "Bad Configuration" 9 "HW Fault Detected" 10 "Vbat Error" 14 "Error" 15 "Not Available" ;
VAL_ 2582847486 DiagnosticStatus_28 0 "OK" 1 "Open Load" 2 "Short to VBAT" 3 "Short to GND" 4 "Over-current" 5 "Over temperature" 6 "Under voltage" 7 "Over voltage" 8 "Bad Configuration" 9 "HW Fault Detected" 10 "Vbat Error" 14 "Error" 15 "Not Available" ;
VAL_ 2582847486 DiagnosticStatus_29 0 "OK" 1 "Open Load" 2 "Short to VBAT" 3 "Short to GND" 4 "Over-current" 5 "Over temperature" 6 "Under voltage" 7 "Over voltage" 8 "Bad Configuration" 9 "HW Fault Detected" 10 "Vbat Error" 14 "Error" 15 "Not Available" ;
VAL_ 2582847486 DiagnosticStatus_30 0 "OK" 1 "Open Load" 2 "Short to VBAT" 3 "Short to GND" 4 "Over-current" 5 "Over temperature" 6 "Under voltage" 7 "Over voltage" 8 "Bad Configuration" 9 "HW Fault Detected" 10 "Vbat Error" 14 "Error" 15 "Not Available" ;
VAL_ 2582847486 DiagnosticStatus_31 0 "OK" 1 "Open Load" 2 "Short to VBAT" 3 "Short to GND" 4 "Over-current" 5 "Over temperature" 6 "Under voltage" 7 "Over voltage" 8 "Bad Configuration" 9 "HW Fault Detected" 10 "Vbat Error" 14 "Error" 15 "Not Available" ;
VAL_ 2582847486 DiagnosticStatus_32 0 "OK" 1 "Open Load" 2 "Short to VBAT" 3 "Short to GND" 4 "Over-current" 5 "Over temperature" 6 "Under voltage" 7 "Over voltage" 8 "Bad Configuration" 9 "HW Fault Detected" 10 "Vbat Error" 14 "Error" 15 "Not Available" ;
